VERSION ""

NS_ :

BS_:

BU_: HVESP01 HVESS

BO_ 2499741802 HVESP01_InternalResistance_6: 8 HVESP01
 SG_ HVESP01_brickResistance_01__6 m0: 8|14@1+ (0.01,0) [0|50] "mOhm"  HVESP01
 SG_ HVESP01_brickResistance_02__6 m0: 22|14@1+ (0.01,0) [0|50] "mOhm"  HVESP01
 SG_ HVESP01_brickResistance_03__6 m0: 36|14@1+ (0.01,0) [0|50] "mOhm"  HVESP01
 SG_ HVESP01_brickResistance_04__6 m0: 50|14@1+ (0.01,0) [0|50] "mOhm"  HVESP01
 SG_ HVESP01_brickResistance_05__6 m1: 8|14@1+ (0.01,0) [0|50] "mOhm"  HVESP01
 SG_ HVESP01_brickResistance_06__6 m1: 22|14@1+ (0.01,0) [0|50] "mOhm"  HVESP01
 SG_ HVESP01_brickResistance_07__6 m1: 36|14@1+ (0.01,0) [0|50] "mOhm"  HVESP01
 SG_ HVESP01_brickResistance_08__6 m1: 50|14@1+ (0.01,0) [0|50] "mOhm"  HVESP01
 SG_ HVESP01_brickResistance_09__6 m2: 8|14@1+ (0.01,0) [0|50] "mOhm"  HVESP01
 SG_ HVESP01_brickResistance_10__6 m2: 22|14@1+ (0.01,0) [0|50] "mOhm"  HVESP01
 SG_ HVESP01_brickResistance_11__6 m2: 36|14@1+ (0.01,0) [0|50] "mOhm"  HVESP01
 SG_ HVESP01_brickResistance_12__6 m2: 50|14@1+ (0.01,0) [0|50] "mOhm"  HVESP01
 SG_ HVESP01_brickResistance_13__6 m3: 8|14@1+ (0.01,0) [0|50] "mOhm"  HVESP01
 SG_ HVESP01_brickResistance_14__6 m3: 22|14@1+ (0.01,0) [0|50] "mOhm"  HVESP01
 SG_ HVESP01_brickResistance_15__6 m3: 36|14@1+ (0.01,0) [0|50] "mOhm"  HVESP01
 SG_ HVESP01_brickResistance_16__6 m3: 50|14@1+ (0.01,0) [0|50] "mOhm"  HVESP01
 SG_ HVESP01_brickResistance_17__6 m4: 8|14@1+ (0.01,0) [0|50] "mOhm"  HVESP01
 SG_ HVESP01_brickResistance_18__6 m4: 22|14@1+ (0.01,0) [0|50] "mOhm"  HVESP01
 SG_ HVESP01_brickResistance_19__6 m4: 36|14@1+ (0.01,0) [0|50] "mOhm"  HVESP01
 SG_ HVESP01_brickResistance_20__6 m4: 50|14@1+ (0.01,0) [0|50] "mOhm"  HVESP01
 SG_ HVESP01_brickResistance_21__6 m5: 8|14@1+ (0.01,0) [0|50] "mOhm"  HVESP01
 SG_ HVESP01_brickResistance_22__6 m5: 22|14@1+ (0.01,0) [0|50] "mOhm"  HVESP01
 SG_ HVESP01_brickResistance_23__6 m5: 36|14@1+ (0.01,0) [0|50] "mOhm"  HVESP01
 SG_ HVESP01_brickResistance_24__6 m5: 50|14@1+ (0.01,0) [0|50] "mOhm"  HVESP01
 SG_ HVESP01_brickResistance_25__6 m6: 8|14@1+ (0.01,0) [0|50] "mOhm"  HVESP01
 SG_ HVESP01_brickResistance_26__6 m6: 22|14@1+ (0.01,0) [0|50] "mOhm"  HVESP01
 SG_ HVESP01_brickResistance_27__6 m6: 36|14@1+ (0.01,0) [0|50] "mOhm"  HVESP01
 SG_ HVESP01_brickResistance_28__6 m6: 50|14@1+ (0.01,0) [0|50] "mOhm"  HVESP01
 SG_ HVESP01_brickResistance_29__6 m7: 8|14@1+ (0.01,0) [0|50] "mOhm"  HVESP01
 SG_ HVESP01_brickResistance_30__6 m7: 22|14@1+ (0.01,0) [0|50] "mOhm"  HVESP01
 SG_ HVESP01_brickResistance_31__6 m7: 36|14@1+ (0.01,0) [0|50] "mOhm"  HVESP01
 SG_ HVESP01_brickResistance_32__6 m7: 50|14@1+ (0.01,0) [0|50] "mOhm"  HVESP01
 SG_ HVESP01_brickResistance_33__6 m8: 8|14@1+ (0.01,0) [0|50] "mOhm"  HVESP01
 SG_ HVESP01_brickResistance_34__6 m8: 22|14@1+ (0.01,0) [0|50] "mOhm"  HVESP01
 SG_ HVESP01_brickResistance_35__6 m8: 36|14@1+ (0.01,0) [0|50] "mOhm"  HVESP01
 SG_ HVESP01_brickResistance_36__6 m8: 50|14@1+ (0.01,0) [0|50] "mOhm"  HVESP01
 SG_ HVESP01_brickResistance_37__6 m9: 8|14@1+ (0.01,0) [0|50] "mOhm"  HVESP01
 SG_ HVESP01_brickResistance_38__6 m9: 22|14@1+ (0.01,0) [0|50] "mOhm"  HVESP01
 SG_ HVESP01_brickResistance_39__6 m9: 36|14@1+ (0.01,0) [0|50] "mOhm"  HVESP01
 SG_ HVESP01_brickResistance_40__6 m9: 50|14@1+ (0.01,0) [0|50] "mOhm"  HVESP01
 SG_ HVESP01_brickResistance_41__6 m10: 8|14@1+ (0.01,0) [0|50] "mOhm"  HVESP01
 SG_ HVESP01_brickResistance_42__6 m10: 22|14@1+ (0.01,0) [0|50] "mOhm"  HVESP01
 SG_ HVESP01_brickResistance_43__6 m10: 36|14@1+ (0.01,0) [0|50] "mOhm"  HVESP01
 SG_ HVESP01_brickResistance_44__6 m10: 50|14@1+ (0.01,0) [0|50] "mOhm"  HVESP01
 SG_ HVESP01_brickResistance_45__6 m11: 8|14@1+ (0.01,0) [0|50] "mOhm"  HVESP01
 SG_ HVESP01_brickResistance_46__6 m11: 22|14@1+ (0.01,0) [0|50] "mOhm"  HVESP01
 SG_ HVESP01_brickResistance_47__6 m11: 36|14@1+ (0.01,0) [0|50] "mOhm"  HVESP01
 SG_ HVESP01_brickResistance_48__6 m11: 50|14@1+ (0.01,0) [0|50] "mOhm"  HVESP01
 SG_ HVESP01_brickResistance_49__6 m12: 8|14@1+ (0.01,0) [0|50] "mOhm"  HVESP01
 SG_ HVESP01_brickResistance_50__6 m12: 22|14@1+ (0.01,0) [0|50] "mOhm"  HVESP01
 SG_ HVESP01_brickResistance_51__6 m12: 36|14@1+ (0.01,0) [0|50] "mOhm"  HVESP01
 SG_ HVESP01_brickResistance_52__6 m12: 50|14@1+ (0.01,0) [0|50] "mOhm"  HVESP01
 SG_ HVESP01_brickResistance_53__6 m13: 8|14@1+ (0.01,0) [0|50] "mOhm"  HVESP01
 SG_ HVESP01_brickResistance_54__6 m13: 22|14@1+ (0.01,0) [0|50] "mOhm"  HVESP01
 SG_ HVESP01_brickResistance_55__6 m13: 36|14@1+ (0.01,0) [0|50] "mOhm"  HVESP01
 SG_ HVESP01_brickResistance_56__6 m13: 50|14@1+ (0.01,0) [0|50] "mOhm"  HVESP01
 SG_ HVESP01_brickResistance_57__6 m14: 8|14@1+ (0.01,0) [0|50] "mOhm"  HVESP01
 SG_ HVESP01_brickResistance_58__6 m14: 22|14@1+ (0.01,0) [0|50] "mOhm"  HVESP01
 SG_ HVESP01_brickResistance_59__6 m14: 36|14@1+ (0.01,0) [0|50] "mOhm"  HVESP01
 SG_ HVESP01_brickResistance_60__6 m14: 50|14@1+ (0.01,0) [0|50] "mOhm"  HVESP01
 SG_ HVESP01_brickResistance_61__6 m15: 8|14@1+ (0.01,0) [0|50] "mOhm"  HVESP01
 SG_ HVESP01_brickResistance_62__6 m15: 22|14@1+ (0.01,0) [0|50] "mOhm"  HVESP01
 SG_ HVESP01_brickResistance_63__6 m15: 36|14@1+ (0.01,0) [0|50] "mOhm"  HVESP01
 SG_ HVESP01_brickResistance_64__6 m15: 50|14@1+ (0.01,0) [0|50] "mOhm"  HVESP01
 SG_ HVESP01_brickResistance_65__6 m16: 8|14@1+ (0.01,0) [0|50] "mOhm"  HVESP01
 SG_ HVESP01_brickResistance_66__6 m16: 22|14@1+ (0.01,0) [0|50] "mOhm"  HVESP01
 SG_ HVESP01_brickResistance_67__6 m16: 36|14@1+ (0.01,0) [0|50] "mOhm"  HVESP01
 SG_ HVESP01_brickResistance_68__6 m16: 50|14@1+ (0.01,0) [0|50] "mOhm"  HVESP01
 SG_ HVESP01_brickResistance_69__6 m17: 8|14@1+ (0.01,0) [0|50] "mOhm"  HVESP01
 SG_ HVESP01_brickResistance_70__6 m17: 22|14@1+ (0.01,0) [0|50] "mOhm"  HVESP01
 SG_ HVESP01_brickResistance_71__6 m17: 36|14@1+ (0.01,0) [0|50] "mOhm"  HVESP01
 SG_ HVESP01_brickResistance_72__6 m17: 50|14@1+ (0.01,0) [0|50] "mOhm"  HVESP01
 SG_ HVESP01_brickResistance_73__6 m18: 8|14@1+ (0.01,0) [0|50] "mOhm"  HVESP01
 SG_ HVESP01_brickResistance_74__6 m18: 22|14@1+ (0.01,0) [0|50] "mOhm"  HVESP01
 SG_ HVESP01_brickResistance_75__6 m18: 36|14@1+ (0.01,0) [0|50] "mOhm"  HVESP01
 SG_ HVESP01_brickResistance_76__6 m18: 50|14@1+ (0.01,0) [0|50] "mOhm"  HVESP01
 SG_ HVESP01_brickResistance_77__6 m19: 8|14@1+ (0.01,0) [0|50] "mOhm"  HVESP01
 SG_ HVESP01_brickResistance_78__6 m19: 22|14@1+ (0.01,0) [0|50] "mOhm"  HVESP01
 SG_ HVESP01_brickResistance_79__6 m19: 36|14@1+ (0.01,0) [0|50] "mOhm"  HVESP01
 SG_ HVESP01_brickResistance_80__6 m19: 50|14@1+ (0.01,0) [0|50] "mOhm"  HVESP01
 SG_ HVESP01_brickResistance_81__6 m20: 8|14@1+ (0.01,0) [0|50] "mOhm"  HVESP01
 SG_ HVESP01_brickResistance_82__6 m20: 22|14@1+ (0.01,0) [0|50] "mOhm"  HVESP01
 SG_ HVESP01_brickResistance_83__6 m20: 36|14@1+ (0.01,0) [0|50] "mOhm"  HVESP01
 SG_ HVESP01_brickResistance_84__6 m20: 50|14@1+ (0.01,0) [0|50] "mOhm"  HVESP01
 SG_ HVESP01_brickResistance_85__6 m21: 8|14@1+ (0.01,0) [0|50] "mOhm"  HVESP01
 SG_ HVESP01_brickResistance_86__6 m21: 22|14@1+ (0.01,0) [0|50] "mOhm"  HVESP01
 SG_ HVESP01_brickResistance_87__6 m21: 36|14@1+ (0.01,0) [0|50] "mOhm"  HVESP01
 SG_ HVESP01_brickResistance_88__6 m21: 50|14@1+ (0.01,0) [0|50] "mOhm"  HVESP01
 SG_ HVESP01_brickResistance_89__6 m22: 8|14@1+ (0.01,0) [0|50] "mOhm"  HVESP01
 SG_ HVESP01_brickResistance_90__6 m22: 22|14@1+ (0.01,0) [0|50] "mOhm"  HVESP01
 SG_ HVESP01_brickResistance_91__6 m22: 36|14@1+ (0.01,0) [0|50] "mOhm"  HVESP01
 SG_ HVESP01_brickResistance_92__6 m22: 50|14@1+ (0.01,0) [0|50] "mOhm"  HVESP01
 SG_ HVESP01_brickResistance_93__6 m23: 8|14@1+ (0.01,0) [0|50] "mOhm"  HVESP01
 SG_ HVESP01_brickResistance_94__6 m23: 22|14@1+ (0.01,0) [0|50] "mOhm"  HVESP01
 SG_ HVESP01_brickResistance_95__6 m23: 36|14@1+ (0.01,0) [0|50] "mOhm"  HVESP01
 SG_ HVESP01_brickResistance_96__6 m23: 50|14@1+ (0.01,0) [0|50] "mOhm"  HVESP01
 SG_ HVESP01_brickResistance_97__6 m24: 8|14@1+ (0.01,0) [0|50] "mOhm"  HVESP01
 SG_ HVESP01_brickResistance_98__6 m24: 22|14@1+ (0.01,0) [0|50] "mOhm"  HVESP01
 SG_ HVESP01_brickResistance_99__6 m24: 36|14@1+ (0.01,0) [0|50] "mOhm"  HVESP01
 SG_ HVESP01_brickResistance_100_6 m24: 50|14@1+ (0.01,0) [0|50] "mOhm"  HVESP01
 SG_ HVESP01_brickResistance_101_6 m25: 8|14@1+ (0.01,0) [0|50] "mOhm"  HVESP01
 SG_ HVESP01_brickResistance_102_6 m25: 22|14@1+ (0.01,0) [0|50] "mOhm"  HVESP01
 SG_ HVESP01_brickResistance_103_6 m25: 36|14@1+ (0.01,0) [0|50] "mOhm"  HVESP01
 SG_ HVESP01_brickResistance_104_6 m25: 50|14@1+ (0.01,0) [0|50] "mOhm"  HVESP01
 SG_ HVESP01_brickResistance_105_6 m26: 8|14@1+ (0.01,0) [0|50] "mOhm"  HVESP01
 SG_ HVESP01_brickResistance_106_6 m26: 22|14@1+ (0.01,0) [0|50] "mOhm"  HVESP01
 SG_ HVESP01_brickResistance_107_6 m26: 36|14@1+ (0.01,0) [0|50] "mOhm"  HVESP01
 SG_ HVESP01_brickResistance_108_6 m26: 50|14@1+ (0.01,0) [0|50] "mOhm"  HVESP01
 SG_ HVESP01_brickResistance_109_6 m27: 8|14@1+ (0.01,0) [0|50] "mOhm"  HVESP01
 SG_ HVESP01_brickResistance_110_6 m27: 22|14@1+ (0.01,0) [0|50] "mOhm"  HVESP01
 SG_ HVESP01_brickResistance_111_6 m27: 36|14@1+ (0.01,0) [0|50] "mOhm"  HVESP01
 SG_ HVESP01_brickResistance_112_6 m27: 50|14@1+ (0.01,0) [0|50] "mOhm"  HVESP01
 SG_ HVESP01_brickResistance_113_6 m28: 8|14@1+ (0.01,0) [0|50] "mOhm"  HVESP01
 SG_ HVESP01_brickResistance_114_6 m28: 22|14@1+ (0.01,0) [0|50] "mOhm"  HVESP01
 SG_ HVESP01_brickResistance_115_6 m28: 36|14@1+ (0.01,0) [0|50] "mOhm"  HVESP01
 SG_ HVESP01_brickResistance_116_6 m28: 50|14@1+ (0.01,0) [0|50] "mOhm"  HVESP01
 SG_ HVESP01_brickResistance_117_6 m29: 8|14@1+ (0.01,0) [0|50] "mOhm"  HVESP01
 SG_ HVESP01_brickResistance_118_6 m29: 22|14@1+ (0.01,0) [0|50] "mOhm"  HVESP01
 SG_ HVESP01_brickResistance_119_6 m29: 36|14@1+ (0.01,0) [0|50] "mOhm"  HVESP01
 SG_ HVESP01_brickResistance_120_6 m29: 50|14@1+ (0.01,0) [0|50] "mOhm"  HVESP01
 SG_ HVESP01_brickResistance_121_6 m30: 8|14@1+ (0.01,0) [0|50] "mOhm"  HVESP01
 SG_ HVESP01_brickResistance_122_6 m30: 22|14@1+ (0.01,0) [0|50] "mOhm"  HVESP01
 SG_ HVESP01_brickResistance_123_6 m30: 36|14@1+ (0.01,0) [0|50] "mOhm"  HVESP01
 SG_ HVESP01_brickResistance_124_6 m30: 50|14@1+ (0.01,0) [0|50] "mOhm"  HVESP01
 SG_ HVESP01_brickResistance_125_6 m31: 8|14@1+ (0.01,0) [0|50] "mOhm"  HVESP01
 SG_ HVESP01_brickResistance_126_6 m31: 22|14@1+ (0.01,0) [0|50] "mOhm"  HVESP01
 SG_ HVESP01_brickResistance_127_6 m31: 36|14@1+ (0.01,0) [0|50] "mOhm"  HVESP01
 SG_ HVESP01_brickResistance_128_6 m31: 50|14@1+ (0.01,0) [0|50] "mOhm"  HVESP01
 SG_ HVESP01_brickResistance_129_6 m32: 8|14@1+ (0.01,0) [0|50] "mOhm"  HVESP01
 SG_ HVESP01_brickResistance_130_6 m32: 22|14@1+ (0.01,0) [0|50] "mOhm"  HVESP01
 SG_ HVESP01_brickResistance_131_6 m32: 36|14@1+ (0.01,0) [0|50] "mOhm"  HVESP01
 SG_ HVESP01_brickResistance_132_6 m32: 50|14@1+ (0.01,0) [0|50] "mOhm"  HVESP01
 SG_ HVESP01_brickResistance_133_6 m33: 8|14@1+ (0.01,0) [0|50] "mOhm"  HVESP01
 SG_ HVESP01_brickResistance_134_6 m33: 22|14@1+ (0.01,0) [0|50] "mOhm"  HVESP01
 SG_ HVESP01_brickResistance_135_6 m33: 36|14@1+ (0.01,0) [0|50] "mOhm"  HVESP01
 SG_ HVESP01_brickResistance_136_6 m33: 50|14@1+ (0.01,0) [0|50] "mOhm"  HVESP01
 SG_ HVESP01_brickResistance_137_6 m34: 8|14@1+ (0.01,0) [0|50] "mOhm"  HVESP01
 SG_ HVESP01_brickResistance_138_6 m34: 22|14@1+ (0.01,0) [0|50] "mOhm"  HVESP01
 SG_ HVESP01_brickResistance_139_6 m34: 36|14@1+ (0.01,0) [0|50] "mOhm"  HVESP01
 SG_ HVESP01_brickResistance_140_6 m34: 50|14@1+ (0.01,0) [0|50] "mOhm"  HVESP01
 SG_ HVESP01_brickResistance_141_6 m35: 8|14@1+ (0.01,0) [0|50] "mOhm"  HVESP01
 SG_ HVESP01_brickResistance_142_6 m35: 22|14@1+ (0.01,0) [0|50] "mOhm"  HVESP01
 SG_ HVESP01_brickResistance_143_6 m35: 36|14@1+ (0.01,0) [0|50] "mOhm"  HVESP01
 SG_ HVESP01_brickResistance_144_6 m35: 50|14@1+ (0.01,0) [0|50] "mOhm"  HVESP01
 SG_ HVESP01_brickResistance_145_6 m36: 8|14@1+ (0.01,0) [0|50] "mOhm"  HVESP01
 SG_ HVESP01_brickResistance_146_6 m36: 22|14@1+ (0.01,0) [0|50] "mOhm"  HVESP01
 SG_ HVESP01_brickResistance_147_6 m36: 36|14@1+ (0.01,0) [0|50] "mOhm"  HVESP01
 SG_ HVESP01_brickResistance_148_6 m36: 50|14@1+ (0.01,0) [0|50] "mOhm"  HVESP01
 SG_ HVESP01_brickResistance_149_6 m37: 8|14@1+ (0.01,0) [0|50] "mOhm"  HVESP01
 SG_ HVESP01_brickResistance_150_6 m37: 22|14@1+ (0.01,0) [0|50] "mOhm"  HVESP01
 SG_ HVESP01_brickResistance_151_6 m37: 36|14@1+ (0.01,0) [0|50] "mOhm"  HVESP01
 SG_ HVESP01_brickResistance_152_6 m37: 50|14@1+ (0.01,0) [0|50] "mOhm"  HVESP01
 SG_ HVESP01_brickResistance_153_6 m38: 8|14@1+ (0.01,0) [0|50] "mOhm"  HVESP01
 SG_ HVESP01_brickResistance_154_6 m38: 22|14@1+ (0.01,0) [0|50] "mOhm"  HVESP01
 SG_ HVESP01_brickResistance_155_6 m38: 36|14@1+ (0.01,0) [0|50] "mOhm"  HVESP01
 SG_ HVESP01_brickResistance_156_6 m38: 50|14@1+ (0.01,0) [0|50] "mOhm"  HVESP01
 SG_ HVESP01_brickResistance_157_6 m39: 8|14@1+ (0.01,0) [0|50] "mOhm"  HVESP01
 SG_ HVESP01_brickResistance_158_6 m39: 22|14@1+ (0.01,0) [0|50] "mOhm"  HVESP01
 SG_ HVESP01_brickResistance_159_6 m39: 36|14@1+ (0.01,0) [0|50] "mOhm"  HVESP01
 SG_ HVESP01_brickResistance_160_6 m39: 50|14@1+ (0.01,0) [0|50] "mOhm"  HVESP01
 SG_ HVESP01_brickResistance_161_6 m40: 8|14@1+ (0.01,0) [0|50] "mOhm"  HVESP01
 SG_ HVESP01_brickResistance_162_6 m40: 22|14@1+ (0.01,0) [0|50] "mOhm"  HVESP01
 SG_ HVESP01_brickResistance_163_6 m40: 36|14@1+ (0.01,0) [0|50] "mOhm"  HVESP01
 SG_ HVESP01_brickResistance_164_6 m40: 50|14@1+ (0.01,0) [0|50] "mOhm"  HVESP01
 SG_ HVESP01_brickResistance_165_6 m41: 8|14@1+ (0.01,0) [0|50] "mOhm"  HVESP01
 SG_ HVESP01_brickResistance_166_6 m41: 22|14@1+ (0.01,0) [0|50] "mOhm"  HVESP01
 SG_ HVESP01_brickResistance_167_6 m41: 36|14@1+ (0.01,0) [0|50] "mOhm"  HVESP01
 SG_ HVESP01_brickResistance_168_6 m41: 50|14@1+ (0.01,0) [0|50] "mOhm"  HVESP01
 SG_ HVESP01_brickResistance_169_6 m42: 8|14@1+ (0.01,0) [0|50] "mOhm"  HVESP01
 SG_ HVESP01_brickResistance_170_6 m42: 22|14@1+ (0.01,0) [0|50] "mOhm"  HVESP01
 SG_ HVESP01_brickResistance_171_6 m42: 36|14@1+ (0.01,0) [0|50] "mOhm"  HVESP01
 SG_ HVESP01_brickResistance_172_6 m42: 50|14@1+ (0.01,0) [0|50] "mOhm"  HVESP01
 SG_ HVESP01_brickResistance_173_6 m43: 8|14@1+ (0.01,0) [0|50] "mOhm"  HVESP01
 SG_ HVESP01_brickResistance_174_6 m43: 22|14@1+ (0.01,0) [0|50] "mOhm"  HVESP01
 SG_ HVESP01_brickResistance_175_6 m43: 36|14@1+ (0.01,0) [0|50] "mOhm"  HVESP01
 SG_ HVESP01_brickResistance_176_6 m43: 50|14@1+ (0.01,0) [0|50] "mOhm"  HVESP01
 SG_ HVESP01_brickResistance_177_6 m44: 8|14@1+ (0.01,0) [0|50] "mOhm"  HVESP01
 SG_ HVESP01_brickResistance_178_6 m44: 22|14@1+ (0.01,0) [0|50] "mOhm"  HVESP01
 SG_ HVESP01_brickResistance_179_6 m44: 36|14@1+ (0.01,0) [0|50] "mOhm"  HVESP01
 SG_ HVESP01_brickResistance_180_6 m44: 50|14@1+ (0.01,0) [0|50] "mOhm"  HVESP01
 SG_ HVESP01_brickResistance_181_6 m45: 8|14@1+ (0.01,0) [0|50] "mOhm"  HVESP01
 SG_ HVESP01_brickResistance_182_6 m45: 22|14@1+ (0.01,0) [0|50] "mOhm"  HVESP01
 SG_ HVESP01_brickResistance_183_6 m45: 36|14@1+ (0.01,0) [0|50] "mOhm"  HVESP01
 SG_ HVESP01_brickResistance_184_6 m45: 50|14@1+ (0.01,0) [0|50] "mOhm"  HVESP01
 SG_ HVESP01_brickResistance_185_6 m46: 8|14@1+ (0.01,0) [0|50] "mOhm"  HVESP01
 SG_ HVESP01_brickResistance_186_6 m46: 22|14@1+ (0.01,0) [0|50] "mOhm"  HVESP01
 SG_ HVESP01_brickResistance_187_6 m46: 36|14@1+ (0.01,0) [0|50] "mOhm"  HVESP01
 SG_ HVESP01_brickResistance_188_6 m46: 50|14@1+ (0.01,0) [0|50] "mOhm"  HVESP01
 SG_ HVESP01_brickResistance_189_6 m47: 8|14@1+ (0.01,0) [0|50] "mOhm"  HVESP01
 SG_ HVESP01_brickResistance_190_6 m47: 22|14@1+ (0.01,0) [0|50] "mOhm"  HVESP01
 SG_ HVESP01_brickResistance_191_6 m47: 36|14@1+ (0.01,0) [0|50] "mOhm"  HVESP01
 SG_ HVESP01_brickResistance_192_6 m47: 50|14@1+ (0.01,0) [0|50] "mOhm"  HVESP01
 SG_ multiplexorbr_6 M: 0|8@1+ (1,0) [0|255] ""  HVESP01

BO_ 2499741803 HVESP01_InternalResistance_7: 8 HVESP01
 SG_ HVESP01_brickResistance_01__7 m0: 8|14@1+ (0.01,0) [0|50] "mOhm"  HVESP01
 SG_ HVESP01_brickResistance_02__7 m0: 22|14@1+ (0.01,0) [0|50] "mOhm"  HVESP01
 SG_ HVESP01_brickResistance_03__7 m0: 36|14@1+ (0.01,0) [0|50] "mOhm"  HVESP01
 SG_ HVESP01_brickResistance_04__7 m0: 50|14@1+ (0.01,0) [0|50] "mOhm"  HVESP01
 SG_ HVESP01_brickResistance_05__7 m1: 8|14@1+ (0.01,0) [0|50] "mOhm"  HVESP01
 SG_ HVESP01_brickResistance_06__7 m1: 22|14@1+ (0.01,0) [0|50] "mOhm"  HVESP01
 SG_ HVESP01_brickResistance_07__7 m1: 36|14@1+ (0.01,0) [0|50] "mOhm"  HVESP01
 SG_ HVESP01_brickResistance_08__7 m1: 50|14@1+ (0.01,0) [0|50] "mOhm"  HVESP01
 SG_ HVESP01_brickResistance_09__7 m2: 8|14@1+ (0.01,0) [0|50] "mOhm"  HVESP01
 SG_ HVESP01_brickResistance_10__7 m2: 22|14@1+ (0.01,0) [0|50] "mOhm"  HVESP01
 SG_ HVESP01_brickResistance_11__7 m2: 36|14@1+ (0.01,0) [0|50] "mOhm"  HVESP01
 SG_ HVESP01_brickResistance_12__7 m2: 50|14@1+ (0.01,0) [0|50] "mOhm"  HVESP01
 SG_ HVESP01_brickResistance_13__7 m3: 8|14@1+ (0.01,0) [0|50] "mOhm"  HVESP01
 SG_ HVESP01_brickResistance_14__7 m3: 22|14@1+ (0.01,0) [0|50] "mOhm"  HVESP01
 SG_ HVESP01_brickResistance_15__7 m3: 36|14@1+ (0.01,0) [0|50] "mOhm"  HVESP01
 SG_ HVESP01_brickResistance_16__7 m3: 50|14@1+ (0.01,0) [0|50] "mOhm"  HVESP01
 SG_ HVESP01_brickResistance_17__7 m4: 8|14@1+ (0.01,0) [0|50] "mOhm"  HVESP01
 SG_ HVESP01_brickResistance_18__7 m4: 22|14@1+ (0.01,0) [0|50] "mOhm"  HVESP01
 SG_ HVESP01_brickResistance_19__7 m4: 36|14@1+ (0.01,0) [0|50] "mOhm"  HVESP01
 SG_ HVESP01_brickResistance_20__7 m4: 50|14@1+ (0.01,0) [0|50] "mOhm"  HVESP01
 SG_ HVESP01_brickResistance_21__7 m5: 8|14@1+ (0.01,0) [0|50] "mOhm"  HVESP01
 SG_ HVESP01_brickResistance_22__7 m5: 22|14@1+ (0.01,0) [0|50] "mOhm"  HVESP01
 SG_ HVESP01_brickResistance_23__7 m5: 36|14@1+ (0.01,0) [0|50] "mOhm"  HVESP01
 SG_ HVESP01_brickResistance_24__7 m5: 50|14@1+ (0.01,0) [0|50] "mOhm"  HVESP01
 SG_ HVESP01_brickResistance_25__7 m6: 8|14@1+ (0.01,0) [0|50] "mOhm"  HVESP01
 SG_ HVESP01_brickResistance_26__7 m6: 22|14@1+ (0.01,0) [0|50] "mOhm"  HVESP01
 SG_ HVESP01_brickResistance_27__7 m6: 36|14@1+ (0.01,0) [0|50] "mOhm"  HVESP01
 SG_ HVESP01_brickResistance_28__7 m6: 50|14@1+ (0.01,0) [0|50] "mOhm"  HVESP01
 SG_ HVESP01_brickResistance_29__7 m7: 8|14@1+ (0.01,0) [0|50] "mOhm"  HVESP01
 SG_ HVESP01_brickResistance_30__7 m7: 22|14@1+ (0.01,0) [0|50] "mOhm"  HVESP01
 SG_ HVESP01_brickResistance_31__7 m7: 36|14@1+ (0.01,0) [0|50] "mOhm"  HVESP01
 SG_ HVESP01_brickResistance_32__7 m7: 50|14@1+ (0.01,0) [0|50] "mOhm"  HVESP01
 SG_ HVESP01_brickResistance_33__7 m8: 8|14@1+ (0.01,0) [0|50] "mOhm"  HVESP01
 SG_ HVESP01_brickResistance_34__7 m8: 22|14@1+ (0.01,0) [0|50] "mOhm"  HVESP01
 SG_ HVESP01_brickResistance_35__7 m8: 36|14@1+ (0.01,0) [0|50] "mOhm"  HVESP01
 SG_ HVESP01_brickResistance_36__7 m8: 50|14@1+ (0.01,0) [0|50] "mOhm"  HVESP01
 SG_ HVESP01_brickResistance_37__7 m9: 8|14@1+ (0.01,0) [0|50] "mOhm"  HVESP01
 SG_ HVESP01_brickResistance_38__7 m9: 22|14@1+ (0.01,0) [0|50] "mOhm"  HVESP01
 SG_ HVESP01_brickResistance_39__7 m9: 36|14@1+ (0.01,0) [0|50] "mOhm"  HVESP01
 SG_ HVESP01_brickResistance_40__7 m9: 50|14@1+ (0.01,0) [0|50] "mOhm"  HVESP01
 SG_ HVESP01_brickResistance_41__7 m10: 8|14@1+ (0.01,0) [0|50] "mOhm"  HVESP01
 SG_ HVESP01_brickResistance_42__7 m10: 22|14@1+ (0.01,0) [0|50] "mOhm"  HVESP01
 SG_ HVESP01_brickResistance_43__7 m10: 36|14@1+ (0.01,0) [0|50] "mOhm"  HVESP01
 SG_ HVESP01_brickResistance_44__7 m10: 50|14@1+ (0.01,0) [0|50] "mOhm"  HVESP01
 SG_ HVESP01_brickResistance_45__7 m11: 8|14@1+ (0.01,0) [0|50] "mOhm"  HVESP01
 SG_ HVESP01_brickResistance_46__7 m11: 22|14@1+ (0.01,0) [0|50] "mOhm"  HVESP01
 SG_ HVESP01_brickResistance_47__7 m11: 36|14@1+ (0.01,0) [0|50] "mOhm"  HVESP01
 SG_ HVESP01_brickResistance_48__7 m11: 50|14@1+ (0.01,0) [0|50] "mOhm"  HVESP01
 SG_ HVESP01_brickResistance_49__7 m12: 8|14@1+ (0.01,0) [0|50] "mOhm"  HVESP01
 SG_ HVESP01_brickResistance_50__7 m12: 22|14@1+ (0.01,0) [0|50] "mOhm"  HVESP01
 SG_ HVESP01_brickResistance_51__7 m12: 36|14@1+ (0.01,0) [0|50] "mOhm"  HVESP01
 SG_ HVESP01_brickResistance_52__7 m12: 50|14@1+ (0.01,0) [0|50] "mOhm"  HVESP01
 SG_ HVESP01_brickResistance_53__7 m13: 8|14@1+ (0.01,0) [0|50] "mOhm"  HVESP01
 SG_ HVESP01_brickResistance_54__7 m13: 22|14@1+ (0.01,0) [0|50] "mOhm"  HVESP01
 SG_ HVESP01_brickResistance_55__7 m13: 36|14@1+ (0.01,0) [0|50] "mOhm"  HVESP01
 SG_ HVESP01_brickResistance_56__7 m13: 50|14@1+ (0.01,0) [0|50] "mOhm"  HVESP01
 SG_ HVESP01_brickResistance_57__7 m14: 8|14@1+ (0.01,0) [0|50] "mOhm"  HVESP01
 SG_ HVESP01_brickResistance_58__7 m14: 22|14@1+ (0.01,0) [0|50] "mOhm"  HVESP01
 SG_ HVESP01_brickResistance_59__7 m14: 36|14@1+ (0.01,0) [0|50] "mOhm"  HVESP01
 SG_ HVESP01_brickResistance_60__7 m14: 50|14@1+ (0.01,0) [0|50] "mOhm"  HVESP01
 SG_ HVESP01_brickResistance_61__7 m15: 8|14@1+ (0.01,0) [0|50] "mOhm"  HVESP01
 SG_ HVESP01_brickResistance_62__7 m15: 22|14@1+ (0.01,0) [0|50] "mOhm"  HVESP01
 SG_ HVESP01_brickResistance_63__7 m15: 36|14@1+ (0.01,0) [0|50] "mOhm"  HVESP01
 SG_ HVESP01_brickResistance_64__7 m15: 50|14@1+ (0.01,0) [0|50] "mOhm"  HVESP01
 SG_ HVESP01_brickResistance_65__7 m16: 8|14@1+ (0.01,0) [0|50] "mOhm"  HVESP01
 SG_ HVESP01_brickResistance_66__7 m16: 22|14@1+ (0.01,0) [0|50] "mOhm"  HVESP01
 SG_ HVESP01_brickResistance_67__7 m16: 36|14@1+ (0.01,0) [0|50] "mOhm"  HVESP01
 SG_ HVESP01_brickResistance_68__7 m16: 50|14@1+ (0.01,0) [0|50] "mOhm"  HVESP01
 SG_ HVESP01_brickResistance_69__7 m17: 8|14@1+ (0.01,0) [0|50] "mOhm"  HVESP01
 SG_ HVESP01_brickResistance_70__7 m17: 22|14@1+ (0.01,0) [0|50] "mOhm"  HVESP01
 SG_ HVESP01_brickResistance_71__7 m17: 36|14@1+ (0.01,0) [0|50] "mOhm"  HVESP01
 SG_ HVESP01_brickResistance_72__7 m17: 50|14@1+ (0.01,0) [0|50] "mOhm"  HVESP01
 SG_ HVESP01_brickResistance_73__7 m18: 8|14@1+ (0.01,0) [0|50] "mOhm"  HVESP01
 SG_ HVESP01_brickResistance_74__7 m18: 22|14@1+ (0.01,0) [0|50] "mOhm"  HVESP01
 SG_ HVESP01_brickResistance_75__7 m18: 36|14@1+ (0.01,0) [0|50] "mOhm"  HVESP01
 SG_ HVESP01_brickResistance_76__7 m18: 50|14@1+ (0.01,0) [0|50] "mOhm"  HVESP01
 SG_ HVESP01_brickResistance_77__7 m19: 8|14@1+ (0.01,0) [0|50] "mOhm"  HVESP01
 SG_ HVESP01_brickResistance_78__7 m19: 22|14@1+ (0.01,0) [0|50] "mOhm"  HVESP01
 SG_ HVESP01_brickResistance_79__7 m19: 36|14@1+ (0.01,0) [0|50] "mOhm"  HVESP01
 SG_ HVESP01_brickResistance_80__7 m19: 50|14@1+ (0.01,0) [0|50] "mOhm"  HVESP01
 SG_ HVESP01_brickResistance_81__7 m20: 8|14@1+ (0.01,0) [0|50] "mOhm"  HVESP01
 SG_ HVESP01_brickResistance_82__7 m20: 22|14@1+ (0.01,0) [0|50] "mOhm"  HVESP01
 SG_ HVESP01_brickResistance_83__7 m20: 36|14@1+ (0.01,0) [0|50] "mOhm"  HVESP01
 SG_ HVESP01_brickResistance_84__7 m20: 50|14@1+ (0.01,0) [0|50] "mOhm"  HVESP01
 SG_ HVESP01_brickResistance_85__7 m21: 8|14@1+ (0.01,0) [0|50] "mOhm"  HVESP01
 SG_ HVESP01_brickResistance_86__7 m21: 22|14@1+ (0.01,0) [0|50] "mOhm"  HVESP01
 SG_ HVESP01_brickResistance_87__7 m21: 36|14@1+ (0.01,0) [0|50] "mOhm"  HVESP01
 SG_ HVESP01_brickResistance_88__7 m21: 50|14@1+ (0.01,0) [0|50] "mOhm"  HVESP01
 SG_ HVESP01_brickResistance_89__7 m22: 8|14@1+ (0.01,0) [0|50] "mOhm"  HVESP01
 SG_ HVESP01_brickResistance_90__7 m22: 22|14@1+ (0.01,0) [0|50] "mOhm"  HVESP01
 SG_ HVESP01_brickResistance_91__7 m22: 36|14@1+ (0.01,0) [0|50] "mOhm"  HVESP01
 SG_ HVESP01_brickResistance_92__7 m22: 50|14@1+ (0.01,0) [0|50] "mOhm"  HVESP01
 SG_ HVESP01_brickResistance_93__7 m23: 8|14@1+ (0.01,0) [0|50] "mOhm"  HVESP01
 SG_ HVESP01_brickResistance_94__7 m23: 22|14@1+ (0.01,0) [0|50] "mOhm"  HVESP01
 SG_ HVESP01_brickResistance_95__7 m23: 36|14@1+ (0.01,0) [0|50] "mOhm"  HVESP01
 SG_ HVESP01_brickResistance_96__7 m23: 50|14@1+ (0.01,0) [0|50] "mOhm"  HVESP01
 SG_ HVESP01_brickResistance_97__7 m24: 8|14@1+ (0.01,0) [0|50] "mOhm"  HVESP01
 SG_ HVESP01_brickResistance_98__7 m24: 22|14@1+ (0.01,0) [0|50] "mOhm"  HVESP01
 SG_ HVESP01_brickResistance_99__7 m24: 36|14@1+ (0.01,0) [0|50] "mOhm"  HVESP01
 SG_ HVESP01_brickResistance_100_7 m24: 50|14@1+ (0.01,0) [0|50] "mOhm"  HVESP01
 SG_ HVESP01_brickResistance_101_7 m25: 8|14@1+ (0.01,0) [0|50] "mOhm"  HVESP01
 SG_ HVESP01_brickResistance_102_7 m25: 22|14@1+ (0.01,0) [0|50] "mOhm"  HVESP01
 SG_ HVESP01_brickResistance_103_7 m25: 36|14@1+ (0.01,0) [0|50] "mOhm"  HVESP01
 SG_ HVESP01_brickResistance_104_7 m25: 50|14@1+ (0.01,0) [0|50] "mOhm"  HVESP01
 SG_ HVESP01_brickResistance_105_7 m26: 8|14@1+ (0.01,0) [0|50] "mOhm"  HVESP01
 SG_ HVESP01_brickResistance_106_7 m26: 22|14@1+ (0.01,0) [0|50] "mOhm"  HVESP01
 SG_ HVESP01_brickResistance_107_7 m26: 36|14@1+ (0.01,0) [0|50] "mOhm"  HVESP01
 SG_ HVESP01_brickResistance_108_7 m26: 50|14@1+ (0.01,0) [0|50] "mOhm"  HVESP01
 SG_ HVESP01_brickResistance_109_7 m27: 8|14@1+ (0.01,0) [0|50] "mOhm"  HVESP01
 SG_ HVESP01_brickResistance_110_7 m27: 22|14@1+ (0.01,0) [0|50] "mOhm"  HVESP01
 SG_ HVESP01_brickResistance_111_7 m27: 36|14@1+ (0.01,0) [0|50] "mOhm"  HVESP01
 SG_ HVESP01_brickResistance_112_7 m27: 50|14@1+ (0.01,0) [0|50] "mOhm"  HVESP01
 SG_ HVESP01_brickResistance_113_7 m28: 8|14@1+ (0.01,0) [0|50] "mOhm"  HVESP01
 SG_ HVESP01_brickResistance_114_7 m28: 22|14@1+ (0.01,0) [0|50] "mOhm"  HVESP01
 SG_ HVESP01_brickResistance_115_7 m28: 36|14@1+ (0.01,0) [0|50] "mOhm"  HVESP01
 SG_ HVESP01_brickResistance_116_7 m28: 50|14@1+ (0.01,0) [0|50] "mOhm"  HVESP01
 SG_ HVESP01_brickResistance_117_7 m29: 8|14@1+ (0.01,0) [0|50] "mOhm"  HVESP01
 SG_ HVESP01_brickResistance_118_7 m29: 22|14@1+ (0.01,0) [0|50] "mOhm"  HVESP01
 SG_ HVESP01_brickResistance_119_7 m29: 36|14@1+ (0.01,0) [0|50] "mOhm"  HVESP01
 SG_ HVESP01_brickResistance_120_7 m29: 50|14@1+ (0.01,0) [0|50] "mOhm"  HVESP01
 SG_ HVESP01_brickResistance_121_7 m30: 8|14@1+ (0.01,0) [0|50] "mOhm"  HVESP01
 SG_ HVESP01_brickResistance_122_7 m30: 22|14@1+ (0.01,0) [0|50] "mOhm"  HVESP01
 SG_ HVESP01_brickResistance_123_7 m30: 36|14@1+ (0.01,0) [0|50] "mOhm"  HVESP01
 SG_ HVESP01_brickResistance_124_7 m30: 50|14@1+ (0.01,0) [0|50] "mOhm"  HVESP01
 SG_ HVESP01_brickResistance_125_7 m31: 8|14@1+ (0.01,0) [0|50] "mOhm"  HVESP01
 SG_ HVESP01_brickResistance_126_7 m31: 22|14@1+ (0.01,0) [0|50] "mOhm"  HVESP01
 SG_ HVESP01_brickResistance_127_7 m31: 36|14@1+ (0.01,0) [0|50] "mOhm"  HVESP01
 SG_ HVESP01_brickResistance_128_7 m31: 50|14@1+ (0.01,0) [0|50] "mOhm"  HVESP01
 SG_ HVESP01_brickResistance_129_7 m32: 8|14@1+ (0.01,0) [0|50] "mOhm"  HVESP01
 SG_ HVESP01_brickResistance_130_7 m32: 22|14@1+ (0.01,0) [0|50] "mOhm"  HVESP01
 SG_ HVESP01_brickResistance_131_7 m32: 36|14@1+ (0.01,0) [0|50] "mOhm"  HVESP01
 SG_ HVESP01_brickResistance_132_7 m32: 50|14@1+ (0.01,0) [0|50] "mOhm"  HVESP01
 SG_ HVESP01_brickResistance_133_7 m33: 8|14@1+ (0.01,0) [0|50] "mOhm"  HVESP01
 SG_ HVESP01_brickResistance_134_7 m33: 22|14@1+ (0.01,0) [0|50] "mOhm"  HVESP01
 SG_ HVESP01_brickResistance_135_7 m33: 36|14@1+ (0.01,0) [0|50] "mOhm"  HVESP01
 SG_ HVESP01_brickResistance_136_7 m33: 50|14@1+ (0.01,0) [0|50] "mOhm"  HVESP01
 SG_ HVESP01_brickResistance_137_7 m34: 8|14@1+ (0.01,0) [0|50] "mOhm"  HVESP01
 SG_ HVESP01_brickResistance_138_7 m34: 22|14@1+ (0.01,0) [0|50] "mOhm"  HVESP01
 SG_ HVESP01_brickResistance_139_7 m34: 36|14@1+ (0.01,0) [0|50] "mOhm"  HVESP01
 SG_ HVESP01_brickResistance_140_7 m34: 50|14@1+ (0.01,0) [0|50] "mOhm"  HVESP01
 SG_ HVESP01_brickResistance_141_7 m35: 8|14@1+ (0.01,0) [0|50] "mOhm"  HVESP01
 SG_ HVESP01_brickResistance_142_7 m35: 22|14@1+ (0.01,0) [0|50] "mOhm"  HVESP01
 SG_ HVESP01_brickResistance_143_7 m35: 36|14@1+ (0.01,0) [0|50] "mOhm"  HVESP01
 SG_ HVESP01_brickResistance_144_7 m35: 50|14@1+ (0.01,0) [0|50] "mOhm"  HVESP01
 SG_ HVESP01_brickResistance_145_7 m36: 8|14@1+ (0.01,0) [0|50] "mOhm"  HVESP01
 SG_ HVESP01_brickResistance_146_7 m36: 22|14@1+ (0.01,0) [0|50] "mOhm"  HVESP01
 SG_ HVESP01_brickResistance_147_7 m36: 36|14@1+ (0.01,0) [0|50] "mOhm"  HVESP01
 SG_ HVESP01_brickResistance_148_7 m36: 50|14@1+ (0.01,0) [0|50] "mOhm"  HVESP01
 SG_ HVESP01_brickResistance_149_7 m37: 8|14@1+ (0.01,0) [0|50] "mOhm"  HVESP01
 SG_ HVESP01_brickResistance_150_7 m37: 22|14@1+ (0.01,0) [0|50] "mOhm"  HVESP01
 SG_ HVESP01_brickResistance_151_7 m37: 36|14@1+ (0.01,0) [0|50] "mOhm"  HVESP01
 SG_ HVESP01_brickResistance_152_7 m37: 50|14@1+ (0.01,0) [0|50] "mOhm"  HVESP01
 SG_ HVESP01_brickResistance_153_7 m38: 8|14@1+ (0.01,0) [0|50] "mOhm"  HVESP01
 SG_ HVESP01_brickResistance_154_7 m38: 22|14@1+ (0.01,0) [0|50] "mOhm"  HVESP01
 SG_ HVESP01_brickResistance_155_7 m38: 36|14@1+ (0.01,0) [0|50] "mOhm"  HVESP01
 SG_ HVESP01_brickResistance_156_7 m38: 50|14@1+ (0.01,0) [0|50] "mOhm"  HVESP01
 SG_ HVESP01_brickResistance_157_7 m39: 8|14@1+ (0.01,0) [0|50] "mOhm"  HVESP01
 SG_ HVESP01_brickResistance_158_7 m39: 22|14@1+ (0.01,0) [0|50] "mOhm"  HVESP01
 SG_ HVESP01_brickResistance_159_7 m39: 36|14@1+ (0.01,0) [0|50] "mOhm"  HVESP01
 SG_ HVESP01_brickResistance_160_7 m39: 50|14@1+ (0.01,0) [0|50] "mOhm"  HVESP01
 SG_ HVESP01_brickResistance_161_7 m40: 8|14@1+ (0.01,0) [0|50] "mOhm"  HVESP01
 SG_ HVESP01_brickResistance_162_7 m40: 22|14@1+ (0.01,0) [0|50] "mOhm"  HVESP01
 SG_ HVESP01_brickResistance_163_7 m40: 36|14@1+ (0.01,0) [0|50] "mOhm"  HVESP01
 SG_ HVESP01_brickResistance_164_7 m40: 50|14@1+ (0.01,0) [0|50] "mOhm"  HVESP01
 SG_ HVESP01_brickResistance_165_7 m41: 8|14@1+ (0.01,0) [0|50] "mOhm"  HVESP01
 SG_ HVESP01_brickResistance_166_7 m41: 22|14@1+ (0.01,0) [0|50] "mOhm"  HVESP01
 SG_ HVESP01_brickResistance_167_7 m41: 36|14@1+ (0.01,0) [0|50] "mOhm"  HVESP01
 SG_ HVESP01_brickResistance_168_7 m41: 50|14@1+ (0.01,0) [0|50] "mOhm"  HVESP01
 SG_ HVESP01_brickResistance_169_7 m42: 8|14@1+ (0.01,0) [0|50] "mOhm"  HVESP01
 SG_ HVESP01_brickResistance_170_7 m42: 22|14@1+ (0.01,0) [0|50] "mOhm"  HVESP01
 SG_ HVESP01_brickResistance_171_7 m42: 36|14@1+ (0.01,0) [0|50] "mOhm"  HVESP01
 SG_ HVESP01_brickResistance_172_7 m42: 50|14@1+ (0.01,0) [0|50] "mOhm"  HVESP01
 SG_ HVESP01_brickResistance_173_7 m43: 8|14@1+ (0.01,0) [0|50] "mOhm"  HVESP01
 SG_ HVESP01_brickResistance_174_7 m43: 22|14@1+ (0.01,0) [0|50] "mOhm"  HVESP01
 SG_ HVESP01_brickResistance_175_7 m43: 36|14@1+ (0.01,0) [0|50] "mOhm"  HVESP01
 SG_ HVESP01_brickResistance_176_7 m43: 50|14@1+ (0.01,0) [0|50] "mOhm"  HVESP01
 SG_ HVESP01_brickResistance_177_7 m44: 8|14@1+ (0.01,0) [0|50] "mOhm"  HVESP01
 SG_ HVESP01_brickResistance_178_7 m44: 22|14@1+ (0.01,0) [0|50] "mOhm"  HVESP01
 SG_ HVESP01_brickResistance_179_7 m44: 36|14@1+ (0.01,0) [0|50] "mOhm"  HVESP01
 SG_ HVESP01_brickResistance_180_7 m44: 50|14@1+ (0.01,0) [0|50] "mOhm"  HVESP01
 SG_ HVESP01_brickResistance_181_7 m45: 8|14@1+ (0.01,0) [0|50] "mOhm"  HVESP01
 SG_ HVESP01_brickResistance_182_7 m45: 22|14@1+ (0.01,0) [0|50] "mOhm"  HVESP01
 SG_ HVESP01_brickResistance_183_7 m45: 36|14@1+ (0.01,0) [0|50] "mOhm"  HVESP01
 SG_ HVESP01_brickResistance_184_7 m45: 50|14@1+ (0.01,0) [0|50] "mOhm"  HVESP01
 SG_ HVESP01_brickResistance_185_7 m46: 8|14@1+ (0.01,0) [0|50] "mOhm"  HVESP01
 SG_ HVESP01_brickResistance_186_7 m46: 22|14@1+ (0.01,0) [0|50] "mOhm"  HVESP01
 SG_ HVESP01_brickResistance_187_7 m46: 36|14@1+ (0.01,0) [0|50] "mOhm"  HVESP01
 SG_ HVESP01_brickResistance_188_7 m46: 50|14@1+ (0.01,0) [0|50] "mOhm"  HVESP01
 SG_ HVESP01_brickResistance_189_7 m47: 8|14@1+ (0.01,0) [0|50] "mOhm"  HVESP01
 SG_ HVESP01_brickResistance_190_7 m47: 22|14@1+ (0.01,0) [0|50] "mOhm"  HVESP01
 SG_ HVESP01_brickResistance_191_7 m47: 36|14@1+ (0.01,0) [0|50] "mOhm"  HVESP01
 SG_ HVESP01_brickResistance_192_7 m47: 50|14@1+ (0.01,0) [0|50] "mOhm"  HVESP01
 SG_ multiplexorbr_7 M: 0|8@1+ (1,0) [0|255] ""  HVESP01

BO_ 2499741804 HVESP01_InternalResistance_8: 8 HVESP01
 SG_ HVESP01_brickResistance_01__8 m0: 8|14@1+ (0.01,0) [0|50] "mOhm"  HVESP01
 SG_ HVESP01_brickResistance_02__8 m0: 22|14@1+ (0.01,0) [0|50] "mOhm"  HVESP01
 SG_ HVESP01_brickResistance_03__8 m0: 36|14@1+ (0.01,0) [0|50] "mOhm"  HVESP01
 SG_ HVESP01_brickResistance_04__8 m0: 50|14@1+ (0.01,0) [0|50] "mOhm"  HVESP01
 SG_ HVESP01_brickResistance_05__8 m1: 8|14@1+ (0.01,0) [0|50] "mOhm"  HVESP01
 SG_ HVESP01_brickResistance_06__8 m1: 22|14@1+ (0.01,0) [0|50] "mOhm"  HVESP01
 SG_ HVESP01_brickResistance_07__8 m1: 36|14@1+ (0.01,0) [0|50] "mOhm"  HVESP01
 SG_ HVESP01_brickResistance_08__8 m1: 50|14@1+ (0.01,0) [0|50] "mOhm"  HVESP01
 SG_ HVESP01_brickResistance_09__8 m2: 8|14@1+ (0.01,0) [0|50] "mOhm"  HVESP01
 SG_ HVESP01_brickResistance_10__8 m2: 22|14@1+ (0.01,0) [0|50] "mOhm"  HVESP01
 SG_ HVESP01_brickResistance_11__8 m2: 36|14@1+ (0.01,0) [0|50] "mOhm"  HVESP01
 SG_ HVESP01_brickResistance_12__8 m2: 50|14@1+ (0.01,0) [0|50] "mOhm"  HVESP01
 SG_ HVESP01_brickResistance_13__8 m3: 8|14@1+ (0.01,0) [0|50] "mOhm"  HVESP01
 SG_ HVESP01_brickResistance_14__8 m3: 22|14@1+ (0.01,0) [0|50] "mOhm"  HVESP01
 SG_ HVESP01_brickResistance_15__8 m3: 36|14@1+ (0.01,0) [0|50] "mOhm"  HVESP01
 SG_ HVESP01_brickResistance_16__8 m3: 50|14@1+ (0.01,0) [0|50] "mOhm"  HVESP01
 SG_ HVESP01_brickResistance_17__8 m4: 8|14@1+ (0.01,0) [0|50] "mOhm"  HVESP01
 SG_ HVESP01_brickResistance_18__8 m4: 22|14@1+ (0.01,0) [0|50] "mOhm"  HVESP01
 SG_ HVESP01_brickResistance_19__8 m4: 36|14@1+ (0.01,0) [0|50] "mOhm"  HVESP01
 SG_ HVESP01_brickResistance_20__8 m4: 50|14@1+ (0.01,0) [0|50] "mOhm"  HVESP01
 SG_ HVESP01_brickResistance_21__8 m5: 8|14@1+ (0.01,0) [0|50] "mOhm"  HVESP01
 SG_ HVESP01_brickResistance_22__8 m5: 22|14@1+ (0.01,0) [0|50] "mOhm"  HVESP01
 SG_ HVESP01_brickResistance_23__8 m5: 36|14@1+ (0.01,0) [0|50] "mOhm"  HVESP01
 SG_ HVESP01_brickResistance_24__8 m5: 50|14@1+ (0.01,0) [0|50] "mOhm"  HVESP01
 SG_ HVESP01_brickResistance_25__8 m6: 8|14@1+ (0.01,0) [0|50] "mOhm"  HVESP01
 SG_ HVESP01_brickResistance_26__8 m6: 22|14@1+ (0.01,0) [0|50] "mOhm"  HVESP01
 SG_ HVESP01_brickResistance_27__8 m6: 36|14@1+ (0.01,0) [0|50] "mOhm"  HVESP01
 SG_ HVESP01_brickResistance_28__8 m6: 50|14@1+ (0.01,0) [0|50] "mOhm"  HVESP01
 SG_ HVESP01_brickResistance_29__8 m7: 8|14@1+ (0.01,0) [0|50] "mOhm"  HVESP01
 SG_ HVESP01_brickResistance_30__8 m7: 22|14@1+ (0.01,0) [0|50] "mOhm"  HVESP01
 SG_ HVESP01_brickResistance_31__8 m7: 36|14@1+ (0.01,0) [0|50] "mOhm"  HVESP01
 SG_ HVESP01_brickResistance_32__8 m7: 50|14@1+ (0.01,0) [0|50] "mOhm"  HVESP01
 SG_ HVESP01_brickResistance_33__8 m8: 8|14@1+ (0.01,0) [0|50] "mOhm"  HVESP01
 SG_ HVESP01_brickResistance_34__8 m8: 22|14@1+ (0.01,0) [0|50] "mOhm"  HVESP01
 SG_ HVESP01_brickResistance_35__8 m8: 36|14@1+ (0.01,0) [0|50] "mOhm"  HVESP01
 SG_ HVESP01_brickResistance_36__8 m8: 50|14@1+ (0.01,0) [0|50] "mOhm"  HVESP01
 SG_ HVESP01_brickResistance_37__8 m9: 8|14@1+ (0.01,0) [0|50] "mOhm"  HVESP01
 SG_ HVESP01_brickResistance_38__8 m9: 22|14@1+ (0.01,0) [0|50] "mOhm"  HVESP01
 SG_ HVESP01_brickResistance_39__8 m9: 36|14@1+ (0.01,0) [0|50] "mOhm"  HVESP01
 SG_ HVESP01_brickResistance_40__8 m9: 50|14@1+ (0.01,0) [0|50] "mOhm"  HVESP01
 SG_ HVESP01_brickResistance_41__8 m10: 8|14@1+ (0.01,0) [0|50] "mOhm"  HVESP01
 SG_ HVESP01_brickResistance_42__8 m10: 22|14@1+ (0.01,0) [0|50] "mOhm"  HVESP01
 SG_ HVESP01_brickResistance_43__8 m10: 36|14@1+ (0.01,0) [0|50] "mOhm"  HVESP01
 SG_ HVESP01_brickResistance_44__8 m10: 50|14@1+ (0.01,0) [0|50] "mOhm"  HVESP01
 SG_ HVESP01_brickResistance_45__8 m11: 8|14@1+ (0.01,0) [0|50] "mOhm"  HVESP01
 SG_ HVESP01_brickResistance_46__8 m11: 22|14@1+ (0.01,0) [0|50] "mOhm"  HVESP01
 SG_ HVESP01_brickResistance_47__8 m11: 36|14@1+ (0.01,0) [0|50] "mOhm"  HVESP01
 SG_ HVESP01_brickResistance_48__8 m11: 50|14@1+ (0.01,0) [0|50] "mOhm"  HVESP01
 SG_ HVESP01_brickResistance_49__8 m12: 8|14@1+ (0.01,0) [0|50] "mOhm"  HVESP01
 SG_ HVESP01_brickResistance_50__8 m12: 22|14@1+ (0.01,0) [0|50] "mOhm"  HVESP01
 SG_ HVESP01_brickResistance_51__8 m12: 36|14@1+ (0.01,0) [0|50] "mOhm"  HVESP01
 SG_ HVESP01_brickResistance_52__8 m12: 50|14@1+ (0.01,0) [0|50] "mOhm"  HVESP01
 SG_ HVESP01_brickResistance_53__8 m13: 8|14@1+ (0.01,0) [0|50] "mOhm"  HVESP01
 SG_ HVESP01_brickResistance_54__8 m13: 22|14@1+ (0.01,0) [0|50] "mOhm"  HVESP01
 SG_ HVESP01_brickResistance_55__8 m13: 36|14@1+ (0.01,0) [0|50] "mOhm"  HVESP01
 SG_ HVESP01_brickResistance_56__8 m13: 50|14@1+ (0.01,0) [0|50] "mOhm"  HVESP01
 SG_ HVESP01_brickResistance_57__8 m14: 8|14@1+ (0.01,0) [0|50] "mOhm"  HVESP01
 SG_ HVESP01_brickResistance_58__8 m14: 22|14@1+ (0.01,0) [0|50] "mOhm"  HVESP01
 SG_ HVESP01_brickResistance_59__8 m14: 36|14@1+ (0.01,0) [0|50] "mOhm"  HVESP01
 SG_ HVESP01_brickResistance_60__8 m14: 50|14@1+ (0.01,0) [0|50] "mOhm"  HVESP01
 SG_ HVESP01_brickResistance_61__8 m15: 8|14@1+ (0.01,0) [0|50] "mOhm"  HVESP01
 SG_ HVESP01_brickResistance_62__8 m15: 22|14@1+ (0.01,0) [0|50] "mOhm"  HVESP01
 SG_ HVESP01_brickResistance_63__8 m15: 36|14@1+ (0.01,0) [0|50] "mOhm"  HVESP01
 SG_ HVESP01_brickResistance_64__8 m15: 50|14@1+ (0.01,0) [0|50] "mOhm"  HVESP01
 SG_ HVESP01_brickResistance_65__8 m16: 8|14@1+ (0.01,0) [0|50] "mOhm"  HVESP01
 SG_ HVESP01_brickResistance_66__8 m16: 22|14@1+ (0.01,0) [0|50] "mOhm"  HVESP01
 SG_ HVESP01_brickResistance_67__8 m16: 36|14@1+ (0.01,0) [0|50] "mOhm"  HVESP01
 SG_ HVESP01_brickResistance_68__8 m16: 50|14@1+ (0.01,0) [0|50] "mOhm"  HVESP01
 SG_ HVESP01_brickResistance_69__8 m17: 8|14@1+ (0.01,0) [0|50] "mOhm"  HVESP01
 SG_ HVESP01_brickResistance_70__8 m17: 22|14@1+ (0.01,0) [0|50] "mOhm"  HVESP01
 SG_ HVESP01_brickResistance_71__8 m17: 36|14@1+ (0.01,0) [0|50] "mOhm"  HVESP01
 SG_ HVESP01_brickResistance_72__8 m17: 50|14@1+ (0.01,0) [0|50] "mOhm"  HVESP01
 SG_ HVESP01_brickResistance_73__8 m18: 8|14@1+ (0.01,0) [0|50] "mOhm"  HVESP01
 SG_ HVESP01_brickResistance_74__8 m18: 22|14@1+ (0.01,0) [0|50] "mOhm"  HVESP01
 SG_ HVESP01_brickResistance_75__8 m18: 36|14@1+ (0.01,0) [0|50] "mOhm"  HVESP01
 SG_ HVESP01_brickResistance_76__8 m18: 50|14@1+ (0.01,0) [0|50] "mOhm"  HVESP01
 SG_ HVESP01_brickResistance_77__8 m19: 8|14@1+ (0.01,0) [0|50] "mOhm"  HVESP01
 SG_ HVESP01_brickResistance_78__8 m19: 22|14@1+ (0.01,0) [0|50] "mOhm"  HVESP01
 SG_ HVESP01_brickResistance_79__8 m19: 36|14@1+ (0.01,0) [0|50] "mOhm"  HVESP01
 SG_ HVESP01_brickResistance_80__8 m19: 50|14@1+ (0.01,0) [0|50] "mOhm"  HVESP01
 SG_ HVESP01_brickResistance_81__8 m20: 8|14@1+ (0.01,0) [0|50] "mOhm"  HVESP01
 SG_ HVESP01_brickResistance_82__8 m20: 22|14@1+ (0.01,0) [0|50] "mOhm"  HVESP01
 SG_ HVESP01_brickResistance_83__8 m20: 36|14@1+ (0.01,0) [0|50] "mOhm"  HVESP01
 SG_ HVESP01_brickResistance_84__8 m20: 50|14@1+ (0.01,0) [0|50] "mOhm"  HVESP01
 SG_ HVESP01_brickResistance_85__8 m21: 8|14@1+ (0.01,0) [0|50] "mOhm"  HVESP01
 SG_ HVESP01_brickResistance_86__8 m21: 22|14@1+ (0.01,0) [0|50] "mOhm"  HVESP01
 SG_ HVESP01_brickResistance_87__8 m21: 36|14@1+ (0.01,0) [0|50] "mOhm"  HVESP01
 SG_ HVESP01_brickResistance_88__8 m21: 50|14@1+ (0.01,0) [0|50] "mOhm"  HVESP01
 SG_ HVESP01_brickResistance_89__8 m22: 8|14@1+ (0.01,0) [0|50] "mOhm"  HVESP01
 SG_ HVESP01_brickResistance_90__8 m22: 22|14@1+ (0.01,0) [0|50] "mOhm"  HVESP01
 SG_ HVESP01_brickResistance_91__8 m22: 36|14@1+ (0.01,0) [0|50] "mOhm"  HVESP01
 SG_ HVESP01_brickResistance_92__8 m22: 50|14@1+ (0.01,0) [0|50] "mOhm"  HVESP01
 SG_ HVESP01_brickResistance_93__8 m23: 8|14@1+ (0.01,0) [0|50] "mOhm"  HVESP01
 SG_ HVESP01_brickResistance_94__8 m23: 22|14@1+ (0.01,0) [0|50] "mOhm"  HVESP01
 SG_ HVESP01_brickResistance_95__8 m23: 36|14@1+ (0.01,0) [0|50] "mOhm"  HVESP01
 SG_ HVESP01_brickResistance_96__8 m23: 50|14@1+ (0.01,0) [0|50] "mOhm"  HVESP01
 SG_ HVESP01_brickResistance_97__8 m24: 8|14@1+ (0.01,0) [0|50] "mOhm"  HVESP01
 SG_ HVESP01_brickResistance_98__8 m24: 22|14@1+ (0.01,0) [0|50] "mOhm"  HVESP01
 SG_ HVESP01_brickResistance_99__8 m24: 36|14@1+ (0.01,0) [0|50] "mOhm"  HVESP01
 SG_ HVESP01_brickResistance_100_8 m24: 50|14@1+ (0.01,0) [0|50] "mOhm"  HVESP01
 SG_ HVESP01_brickResistance_101_8 m25: 8|14@1+ (0.01,0) [0|50] "mOhm"  HVESP01
 SG_ HVESP01_brickResistance_102_8 m25: 22|14@1+ (0.01,0) [0|50] "mOhm"  HVESP01
 SG_ HVESP01_brickResistance_103_8 m25: 36|14@1+ (0.01,0) [0|50] "mOhm"  HVESP01
 SG_ HVESP01_brickResistance_104_8 m25: 50|14@1+ (0.01,0) [0|50] "mOhm"  HVESP01
 SG_ HVESP01_brickResistance_105_8 m26: 8|14@1+ (0.01,0) [0|50] "mOhm"  HVESP01
 SG_ HVESP01_brickResistance_106_8 m26: 22|14@1+ (0.01,0) [0|50] "mOhm"  HVESP01
 SG_ HVESP01_brickResistance_107_8 m26: 36|14@1+ (0.01,0) [0|50] "mOhm"  HVESP01
 SG_ HVESP01_brickResistance_108_8 m26: 50|14@1+ (0.01,0) [0|50] "mOhm"  HVESP01
 SG_ HVESP01_brickResistance_109_8 m27: 8|14@1+ (0.01,0) [0|50] "mOhm"  HVESP01
 SG_ HVESP01_brickResistance_110_8 m27: 22|14@1+ (0.01,0) [0|50] "mOhm"  HVESP01
 SG_ HVESP01_brickResistance_111_8 m27: 36|14@1+ (0.01,0) [0|50] "mOhm"  HVESP01
 SG_ HVESP01_brickResistance_112_8 m27: 50|14@1+ (0.01,0) [0|50] "mOhm"  HVESP01
 SG_ HVESP01_brickResistance_113_8 m28: 8|14@1+ (0.01,0) [0|50] "mOhm"  HVESP01
 SG_ HVESP01_brickResistance_114_8 m28: 22|14@1+ (0.01,0) [0|50] "mOhm"  HVESP01
 SG_ HVESP01_brickResistance_115_8 m28: 36|14@1+ (0.01,0) [0|50] "mOhm"  HVESP01
 SG_ HVESP01_brickResistance_116_8 m28: 50|14@1+ (0.01,0) [0|50] "mOhm"  HVESP01
 SG_ HVESP01_brickResistance_117_8 m29: 8|14@1+ (0.01,0) [0|50] "mOhm"  HVESP01
 SG_ HVESP01_brickResistance_118_8 m29: 22|14@1+ (0.01,0) [0|50] "mOhm"  HVESP01
 SG_ HVESP01_brickResistance_119_8 m29: 36|14@1+ (0.01,0) [0|50] "mOhm"  HVESP01
 SG_ HVESP01_brickResistance_120_8 m29: 50|14@1+ (0.01,0) [0|50] "mOhm"  HVESP01
 SG_ HVESP01_brickResistance_121_8 m30: 8|14@1+ (0.01,0) [0|50] "mOhm"  HVESP01
 SG_ HVESP01_brickResistance_122_8 m30: 22|14@1+ (0.01,0) [0|50] "mOhm"  HVESP01
 SG_ HVESP01_brickResistance_123_8 m30: 36|14@1+ (0.01,0) [0|50] "mOhm"  HVESP01
 SG_ HVESP01_brickResistance_124_8 m30: 50|14@1+ (0.01,0) [0|50] "mOhm"  HVESP01
 SG_ HVESP01_brickResistance_125_8 m31: 8|14@1+ (0.01,0) [0|50] "mOhm"  HVESP01
 SG_ HVESP01_brickResistance_126_8 m31: 22|14@1+ (0.01,0) [0|50] "mOhm"  HVESP01
 SG_ HVESP01_brickResistance_127_8 m31: 36|14@1+ (0.01,0) [0|50] "mOhm"  HVESP01
 SG_ HVESP01_brickResistance_128_8 m31: 50|14@1+ (0.01,0) [0|50] "mOhm"  HVESP01
 SG_ HVESP01_brickResistance_129_8 m32: 8|14@1+ (0.01,0) [0|50] "mOhm"  HVESP01
 SG_ HVESP01_brickResistance_130_8 m32: 22|14@1+ (0.01,0) [0|50] "mOhm"  HVESP01
 SG_ HVESP01_brickResistance_131_8 m32: 36|14@1+ (0.01,0) [0|50] "mOhm"  HVESP01
 SG_ HVESP01_brickResistance_132_8 m32: 50|14@1+ (0.01,0) [0|50] "mOhm"  HVESP01
 SG_ HVESP01_brickResistance_133_8 m33: 8|14@1+ (0.01,0) [0|50] "mOhm"  HVESP01
 SG_ HVESP01_brickResistance_134_8 m33: 22|14@1+ (0.01,0) [0|50] "mOhm"  HVESP01
 SG_ HVESP01_brickResistance_135_8 m33: 36|14@1+ (0.01,0) [0|50] "mOhm"  HVESP01
 SG_ HVESP01_brickResistance_136_8 m33: 50|14@1+ (0.01,0) [0|50] "mOhm"  HVESP01
 SG_ HVESP01_brickResistance_137_8 m34: 8|14@1+ (0.01,0) [0|50] "mOhm"  HVESP01
 SG_ HVESP01_brickResistance_138_8 m34: 22|14@1+ (0.01,0) [0|50] "mOhm"  HVESP01
 SG_ HVESP01_brickResistance_139_8 m34: 36|14@1+ (0.01,0) [0|50] "mOhm"  HVESP01
 SG_ HVESP01_brickResistance_140_8 m34: 50|14@1+ (0.01,0) [0|50] "mOhm"  HVESP01
 SG_ HVESP01_brickResistance_141_8 m35: 8|14@1+ (0.01,0) [0|50] "mOhm"  HVESP01
 SG_ HVESP01_brickResistance_142_8 m35: 22|14@1+ (0.01,0) [0|50] "mOhm"  HVESP01
 SG_ HVESP01_brickResistance_143_8 m35: 36|14@1+ (0.01,0) [0|50] "mOhm"  HVESP01
 SG_ HVESP01_brickResistance_144_8 m35: 50|14@1+ (0.01,0) [0|50] "mOhm"  HVESP01
 SG_ HVESP01_brickResistance_145_8 m36: 8|14@1+ (0.01,0) [0|50] "mOhm"  HVESP01
 SG_ HVESP01_brickResistance_146_8 m36: 22|14@1+ (0.01,0) [0|50] "mOhm"  HVESP01
 SG_ HVESP01_brickResistance_147_8 m36: 36|14@1+ (0.01,0) [0|50] "mOhm"  HVESP01
 SG_ HVESP01_brickResistance_148_8 m36: 50|14@1+ (0.01,0) [0|50] "mOhm"  HVESP01
 SG_ HVESP01_brickResistance_149_8 m37: 8|14@1+ (0.01,0) [0|50] "mOhm"  HVESP01
 SG_ HVESP01_brickResistance_150_8 m37: 22|14@1+ (0.01,0) [0|50] "mOhm"  HVESP01
 SG_ HVESP01_brickResistance_151_8 m37: 36|14@1+ (0.01,0) [0|50] "mOhm"  HVESP01
 SG_ HVESP01_brickResistance_152_8 m37: 50|14@1+ (0.01,0) [0|50] "mOhm"  HVESP01
 SG_ HVESP01_brickResistance_153_8 m38: 8|14@1+ (0.01,0) [0|50] "mOhm"  HVESP01
 SG_ HVESP01_brickResistance_154_8 m38: 22|14@1+ (0.01,0) [0|50] "mOhm"  HVESP01
 SG_ HVESP01_brickResistance_155_8 m38: 36|14@1+ (0.01,0) [0|50] "mOhm"  HVESP01
 SG_ HVESP01_brickResistance_156_8 m38: 50|14@1+ (0.01,0) [0|50] "mOhm"  HVESP01
 SG_ HVESP01_brickResistance_157_8 m39: 8|14@1+ (0.01,0) [0|50] "mOhm"  HVESP01
 SG_ HVESP01_brickResistance_158_8 m39: 22|14@1+ (0.01,0) [0|50] "mOhm"  HVESP01
 SG_ HVESP01_brickResistance_159_8 m39: 36|14@1+ (0.01,0) [0|50] "mOhm"  HVESP01
 SG_ HVESP01_brickResistance_160_8 m39: 50|14@1+ (0.01,0) [0|50] "mOhm"  HVESP01
 SG_ HVESP01_brickResistance_161_8 m40: 8|14@1+ (0.01,0) [0|50] "mOhm"  HVESP01
 SG_ HVESP01_brickResistance_162_8 m40: 22|14@1+ (0.01,0) [0|50] "mOhm"  HVESP01
 SG_ HVESP01_brickResistance_163_8 m40: 36|14@1+ (0.01,0) [0|50] "mOhm"  HVESP01
 SG_ HVESP01_brickResistance_164_8 m40: 50|14@1+ (0.01,0) [0|50] "mOhm"  HVESP01
 SG_ HVESP01_brickResistance_165_8 m41: 8|14@1+ (0.01,0) [0|50] "mOhm"  HVESP01
 SG_ HVESP01_brickResistance_166_8 m41: 22|14@1+ (0.01,0) [0|50] "mOhm"  HVESP01
 SG_ HVESP01_brickResistance_167_8 m41: 36|14@1+ (0.01,0) [0|50] "mOhm"  HVESP01
 SG_ HVESP01_brickResistance_168_8 m41: 50|14@1+ (0.01,0) [0|50] "mOhm"  HVESP01
 SG_ HVESP01_brickResistance_169_8 m42: 8|14@1+ (0.01,0) [0|50] "mOhm"  HVESP01
 SG_ HVESP01_brickResistance_170_8 m42: 22|14@1+ (0.01,0) [0|50] "mOhm"  HVESP01
 SG_ HVESP01_brickResistance_171_8 m42: 36|14@1+ (0.01,0) [0|50] "mOhm"  HVESP01
 SG_ HVESP01_brickResistance_172_8 m42: 50|14@1+ (0.01,0) [0|50] "mOhm"  HVESP01
 SG_ HVESP01_brickResistance_173_8 m43: 8|14@1+ (0.01,0) [0|50] "mOhm"  HVESP01
 SG_ HVESP01_brickResistance_174_8 m43: 22|14@1+ (0.01,0) [0|50] "mOhm"  HVESP01
 SG_ HVESP01_brickResistance_175_8 m43: 36|14@1+ (0.01,0) [0|50] "mOhm"  HVESP01
 SG_ HVESP01_brickResistance_176_8 m43: 50|14@1+ (0.01,0) [0|50] "mOhm"  HVESP01
 SG_ HVESP01_brickResistance_177_8 m44: 8|14@1+ (0.01,0) [0|50] "mOhm"  HVESP01
 SG_ HVESP01_brickResistance_178_8 m44: 22|14@1+ (0.01,0) [0|50] "mOhm"  HVESP01
 SG_ HVESP01_brickResistance_179_8 m44: 36|14@1+ (0.01,0) [0|50] "mOhm"  HVESP01
 SG_ HVESP01_brickResistance_180_8 m44: 50|14@1+ (0.01,0) [0|50] "mOhm"  HVESP01
 SG_ HVESP01_brickResistance_181_8 m45: 8|14@1+ (0.01,0) [0|50] "mOhm"  HVESP01
 SG_ HVESP01_brickResistance_182_8 m45: 22|14@1+ (0.01,0) [0|50] "mOhm"  HVESP01
 SG_ HVESP01_brickResistance_183_8 m45: 36|14@1+ (0.01,0) [0|50] "mOhm"  HVESP01
 SG_ HVESP01_brickResistance_184_8 m45: 50|14@1+ (0.01,0) [0|50] "mOhm"  HVESP01
 SG_ HVESP01_brickResistance_185_8 m46: 8|14@1+ (0.01,0) [0|50] "mOhm"  HVESP01
 SG_ HVESP01_brickResistance_186_8 m46: 22|14@1+ (0.01,0) [0|50] "mOhm"  HVESP01
 SG_ HVESP01_brickResistance_187_8 m46: 36|14@1+ (0.01,0) [0|50] "mOhm"  HVESP01
 SG_ HVESP01_brickResistance_188_8 m46: 50|14@1+ (0.01,0) [0|50] "mOhm"  HVESP01
 SG_ HVESP01_brickResistance_189_8 m47: 8|14@1+ (0.01,0) [0|50] "mOhm"  HVESP01
 SG_ HVESP01_brickResistance_190_8 m47: 22|14@1+ (0.01,0) [0|50] "mOhm"  HVESP01
 SG_ HVESP01_brickResistance_191_8 m47: 36|14@1+ (0.01,0) [0|50] "mOhm"  HVESP01
 SG_ HVESP01_brickResistance_192_8 m47: 50|14@1+ (0.01,0) [0|50] "mOhm"  HVESP01
 SG_ multiplexorbr_8 M: 0|8@1+ (1,0) [0|255] ""  HVESP01

BO_ 2499742053 HVESP01_modTemperature_1: 8 HVESP01
 SG_ HVESP01_modTemperature_01_1 m0: 16|8@1- (1,25) [-103|152] "Celsius"  HVESP01
 SG_ HVESP01_modTemperature_02_1 m0: 24|8@1- (1,25) [-103|152] "Celsius"  HVESP01
 SG_ HVESP01_modTemperature_03_1 m0: 32|8@1- (1,25) [-103|152] "Celsius"  HVESP01
 SG_ HVESP01_modTemperature_04_1 m0: 40|8@1- (1,25) [-103|152] "Celsius"  HVESP01
 SG_ HVESP01_modTemperature_05_1 m0: 48|8@1- (1,25) [-103|152] "Celsius"  HVESP01
 SG_ HVESP01_modTemperature_06_1 m1: 16|8@1- (1,25) [-103|152] "Celsius"  HVESP01
 SG_ HVESP01_modTemperature_07_1 m1: 24|8@1- (1,25) [-103|152] "Celsius"  HVESP01
 SG_ HVESP01_modTemperature_08_1 m1: 32|8@1- (1,25) [-103|152] "Celsius"  HVESP01
 SG_ HVESP01_modTemperature_09_1 m1: 40|8@1- (1,25) [-103|152] "Celsius"  HVESP01
 SG_ HVESP01_modTemperature_10_1 m1: 48|8@1- (1,25) [-103|152] "Celsius"  HVESP01
 SG_ HVESP01_modTemperature_11_1 m2: 16|8@1- (1,25) [-103|152] "Celsius"  HVESP01
 SG_ HVESP01_modTemperature_12_1 m2: 24|8@1- (1,25) [-103|152] "Celsius"  HVESP01
 SG_ HVESP01_modTemperature_13_1 m2: 32|8@1- (1,25) [-103|152] "Celsius"  HVESP01
 SG_ HVESP01_modTemperature_14_1 m2: 40|8@1- (1,25) [-103|152] "Celsius"  HVESP01
 SG_ HVESP01_modTemperature_15_1 m2: 48|8@1- (1,25) [-103|152] "Celsius"  HVESP01
 SG_ HVESP01_modTemperature_16_1 m3: 16|8@1- (1,25) [-103|152] "Celsius"  HVESP01
 SG_ HVESP01_modTemperature_17_1 m3: 24|8@1- (1,25) [-103|152] "Celsius"  HVESP01
 SG_ HVESP01_modTemperature_18_1 m3: 32|8@1- (1,25) [-103|152] "Celsius"  HVESP01
 SG_ HVESP01_modTemperature_19_1 m3: 40|8@1- (1,25) [-103|152] "Celsius"  HVESP01
 SG_ HVESP01_modTemperature_20_1 m3: 48|8@1- (1,25) [-103|152] "Celsius"  HVESP01
 SG_ HVESP01_modTemperature_21_1 m4: 16|8@1- (1,25) [-103|152] "Celsius"  HVESP01
 SG_ HVESP01_modTemperature_22_1 m4: 24|8@1- (1,25) [-103|152] "Celsius"  HVESP01
 SG_ HVESP01_modTemperature_23_1 m4: 32|8@1- (1,25) [-103|152] "Celsius"  HVESP01
 SG_ HVESP01_modTemperature_24_1 m4: 40|8@1- (1,25) [-103|152] "Celsius"  HVESP01
 SG_ HVESP01_modTemperature_25_1 m4: 48|8@1- (1,25) [-103|152] "Celsius"  HVESP01
 SG_ HVESP01_modTemperature_26_1 m5: 16|8@1- (1,25) [-103|152] "Celsius"  HVESP01
 SG_ HVESP01_modTemperature_27_1 m5: 24|8@1- (1,25) [-103|152] "Celsius"  HVESP01
 SG_ HVESP01_modTemperature_28_1 m5: 32|8@1- (1,25) [-103|152] "Celsius"  HVESP01
 SG_ HVESP01_modTemperature_29_1 m5: 40|8@1- (1,25) [-103|152] "Celsius"  HVESP01
 SG_ HVESP01_modTemperature_30_1 m5: 48|8@1- (1,25) [-103|152] "Celsius"  HVESP01
 SG_ HVESP01_modTemperature_31_1 m6: 16|8@1- (1,25) [-103|152] "Celsius"  HVESP01
 SG_ HVESP01_modTemperature_32_1 m6: 24|8@1- (1,25) [-103|152] "Celsius"  HVESP01
 SG_ HVESP01_modTemperature_33_1 m6: 32|8@1- (1,25) [-103|152] "Celsius"  HVESP01
 SG_ HVESP01_modTemperature_34_1 m6: 40|8@1- (1,25) [-103|152] "Celsius"  HVESP01
 SG_ HVESP01_modTemperature_35_1 m6: 48|8@1- (1,25) [-103|152] "Celsius"  HVESP01
 SG_ HVESP01_modTemperature_36_1 m7: 16|8@1- (1,25) [-103|152] "Celsius"  HVESP01
 SG_ HVESP01_modTemperature_37_1 m7: 24|8@1- (1,25) [-103|152] "Celsius"  HVESP01
 SG_ HVESP01_modTemperature_38_1 m7: 32|8@1- (1,25) [-103|152] "Celsius"  HVESP01
 SG_ HVESP01_modTemperature_39_1 m7: 40|8@1- (1,25) [-103|152] "Celsius"  HVESP01
 SG_ HVESP01_modTemperature_40_1 m7: 48|8@1- (1,25) [-103|152] "Celsius"  HVESP01
 SG_ HVESP01_modTemperature_41_1 m8: 16|8@1- (1,25) [-103|152] "Celsius"  HVESP01
 SG_ HVESP01_modTemperature_42_1 m8: 24|8@1- (1,25) [-103|152] "Celsius"  HVESP01
 SG_ HVESP01_modTemperature_43_1 m8: 32|8@1- (1,25) [-103|152] "Celsius"  HVESP01
 SG_ HVESP01_modTemperature_44_1 m8: 40|8@1- (1,25) [-103|152] "Celsius"  HVESP01
 SG_ HVESP01_modTemperature_45_1 m8: 48|8@1- (1,25) [-103|152] "Celsius"  HVESP01
 SG_ HVESP01_modTemperature_46_1 m9: 16|8@1- (1,25) [-103|152] "Celsius"  HVESP01
 SG_ HVESP01_modTemperature_47_1 m9: 24|8@1- (1,25) [-103|152] "Celsius"  HVESP01
 SG_ HVESP01_modTemperature_48_1 m9: 32|8@1- (1,25) [-103|152] "Celsius"  HVESP01
 SG_ HVESP01_modTemperature_49_1 m9: 40|8@1- (1,25) [-103|152] "Celsius"  HVESP01
 SG_ HVESP01_modTemperature_50_1 m9: 48|8@1- (1,25) [-103|152] "Celsius"  HVESP01
 SG_ multiplexormt_1 M: 0|9@1+ (1,0) [0|255] ""  HVESP01

BO_ 2499742054 HVESP01_modTemperature_2: 8 HVESP01
 SG_ HVESP01_modTemperature_01_2 m0: 16|8@1- (1,25) [-103|152] "Celsius"  HVESP01
 SG_ HVESP01_modTemperature_02_2 m0: 24|8@1- (1,25) [-103|152] "Celsius"  HVESP01
 SG_ HVESP01_modTemperature_03_2 m0: 32|8@1- (1,25) [-103|152] "Celsius"  HVESP01
 SG_ HVESP01_modTemperature_04_2 m0: 40|8@1- (1,25) [-103|152] "Celsius"  HVESP01
 SG_ HVESP01_modTemperature_05_2 m0: 48|8@1- (1,25) [-103|152] "Celsius"  HVESP01
 SG_ HVESP01_modTemperature_06_2 m1: 16|8@1- (1,25) [-103|152] "Celsius"  HVESP01
 SG_ HVESP01_modTemperature_07_2 m1: 24|8@1- (1,25) [-103|152] "Celsius"  HVESP01
 SG_ HVESP01_modTemperature_08_2 m1: 32|8@1- (1,25) [-103|152] "Celsius"  HVESP01
 SG_ HVESP01_modTemperature_09_2 m1: 40|8@1- (1,25) [-103|152] "Celsius"  HVESP01
 SG_ HVESP01_modTemperature_10_2 m1: 48|8@1- (1,25) [-103|152] "Celsius"  HVESP01
 SG_ HVESP01_modTemperature_11_2 m2: 16|8@1- (1,25) [-103|152] "Celsius"  HVESP01
 SG_ HVESP01_modTemperature_12_2 m2: 24|8@1- (1,25) [-103|152] "Celsius"  HVESP01
 SG_ HVESP01_modTemperature_13_2 m2: 32|8@1- (1,25) [-103|152] "Celsius"  HVESP01
 SG_ HVESP01_modTemperature_14_2 m2: 40|8@1- (1,25) [-103|152] "Celsius"  HVESP01
 SG_ HVESP01_modTemperature_15_2 m2: 48|8@1- (1,25) [-103|152] "Celsius"  HVESP01
 SG_ HVESP01_modTemperature_16_2 m3: 16|8@1- (1,25) [-103|152] "Celsius"  HVESP01
 SG_ HVESP01_modTemperature_17_2 m3: 24|8@1- (1,25) [-103|152] "Celsius"  HVESP01
 SG_ HVESP01_modTemperature_18_2 m3: 32|8@1- (1,25) [-103|152] "Celsius"  HVESP01
 SG_ HVESP01_modTemperature_19_2 m3: 40|8@1- (1,25) [-103|152] "Celsius"  HVESP01
 SG_ HVESP01_modTemperature_20_2 m3: 48|8@1- (1,25) [-103|152] "Celsius"  HVESP01
 SG_ HVESP01_modTemperature_21_2 m4: 16|8@1- (1,25) [-103|152] "Celsius"  HVESP01
 SG_ HVESP01_modTemperature_22_2 m4: 24|8@1- (1,25) [-103|152] "Celsius"  HVESP01
 SG_ HVESP01_modTemperature_23_2 m4: 32|8@1- (1,25) [-103|152] "Celsius"  HVESP01
 SG_ HVESP01_modTemperature_24_2 m4: 40|8@1- (1,25) [-103|152] "Celsius"  HVESP01
 SG_ HVESP01_modTemperature_25_2 m4: 48|8@1- (1,25) [-103|152] "Celsius"  HVESP01
 SG_ HVESP01_modTemperature_26_2 m5: 16|8@1- (1,25) [-103|152] "Celsius"  HVESP01
 SG_ HVESP01_modTemperature_27_2 m5: 24|8@1- (1,25) [-103|152] "Celsius"  HVESP01
 SG_ HVESP01_modTemperature_28_2 m5: 32|8@1- (1,25) [-103|152] "Celsius"  HVESP01
 SG_ HVESP01_modTemperature_29_2 m5: 40|8@1- (1,25) [-103|152] "Celsius"  HVESP01
 SG_ HVESP01_modTemperature_30_2 m5: 48|8@1- (1,25) [-103|152] "Celsius"  HVESP01
 SG_ HVESP01_modTemperature_31_2 m6: 16|8@1- (1,25) [-103|152] "Celsius"  HVESP01
 SG_ HVESP01_modTemperature_32_2 m6: 24|8@1- (1,25) [-103|152] "Celsius"  HVESP01
 SG_ HVESP01_modTemperature_33_2 m6: 32|8@1- (1,25) [-103|152] "Celsius"  HVESP01
 SG_ HVESP01_modTemperature_34_2 m6: 40|8@1- (1,25) [-103|152] "Celsius"  HVESP01
 SG_ HVESP01_modTemperature_35_2 m6: 48|8@1- (1,25) [-103|152] "Celsius"  HVESP01
 SG_ HVESP01_modTemperature_36_2 m7: 16|8@1- (1,25) [-103|152] "Celsius"  HVESP01
 SG_ HVESP01_modTemperature_37_2 m7: 24|8@1- (1,25) [-103|152] "Celsius"  HVESP01
 SG_ HVESP01_modTemperature_38_2 m7: 32|8@1- (1,25) [-103|152] "Celsius"  HVESP01
 SG_ HVESP01_modTemperature_39_2 m7: 40|8@1- (1,25) [-103|152] "Celsius"  HVESP01
 SG_ HVESP01_modTemperature_40_2 m7: 48|8@1- (1,25) [-103|152] "Celsius"  HVESP01
 SG_ HVESP01_modTemperature_41_2 m8: 16|8@1- (1,25) [-103|152] "Celsius"  HVESP01
 SG_ HVESP01_modTemperature_42_2 m8: 24|8@1- (1,25) [-103|152] "Celsius"  HVESP01
 SG_ HVESP01_modTemperature_43_2 m8: 32|8@1- (1,25) [-103|152] "Celsius"  HVESP01
 SG_ HVESP01_modTemperature_44_2 m8: 40|8@1- (1,25) [-103|152] "Celsius"  HVESP01
 SG_ HVESP01_modTemperature_45_2 m8: 48|8@1- (1,25) [-103|152] "Celsius"  HVESP01
 SG_ HVESP01_modTemperature_46_2 m9: 16|8@1- (1,25) [-103|152] "Celsius"  HVESP01
 SG_ HVESP01_modTemperature_47_2 m9: 24|8@1- (1,25) [-103|152] "Celsius"  HVESP01
 SG_ HVESP01_modTemperature_48_2 m9: 32|8@1- (1,25) [-103|152] "Celsius"  HVESP01
 SG_ HVESP01_modTemperature_49_2 m9: 40|8@1- (1,25) [-103|152] "Celsius"  HVESP01
 SG_ HVESP01_modTemperature_50_2 m9: 48|8@1- (1,25) [-103|152] "Celsius"  HVESP01
 SG_ multiplexormt_2 M: 0|9@1+ (1,0) [0|255] ""  HVESP01

BO_ 2499742055 HVESP01_modTemperature_3: 8 HVESP01
 SG_ HVESP01_modTemperature_01_3 m0: 16|8@1- (1,25) [-103|152] "Celsius"  HVESP01
 SG_ HVESP01_modTemperature_02_3 m0: 24|8@1- (1,25) [-103|152] "Celsius"  HVESP01
 SG_ HVESP01_modTemperature_03_3 m0: 32|8@1- (1,25) [-103|152] "Celsius"  HVESP01
 SG_ HVESP01_modTemperature_04_3 m0: 40|8@1- (1,25) [-103|152] "Celsius"  HVESP01
 SG_ HVESP01_modTemperature_05_3 m0: 48|8@1- (1,25) [-103|152] "Celsius"  HVESP01
 SG_ HVESP01_modTemperature_06_3 m1: 16|8@1- (1,25) [-103|152] "Celsius"  HVESP01
 SG_ HVESP01_modTemperature_07_3 m1: 24|8@1- (1,25) [-103|152] "Celsius"  HVESP01
 SG_ HVESP01_modTemperature_08_3 m1: 32|8@1- (1,25) [-103|152] "Celsius"  HVESP01
 SG_ HVESP01_modTemperature_09_3 m1: 40|8@1- (1,25) [-103|152] "Celsius"  HVESP01
 SG_ HVESP01_modTemperature_10_3 m1: 48|8@1- (1,25) [-103|152] "Celsius"  HVESP01
 SG_ HVESP01_modTemperature_11_3 m2: 16|8@1- (1,25) [-103|152] "Celsius"  HVESP01
 SG_ HVESP01_modTemperature_12_3 m2: 24|8@1- (1,25) [-103|152] "Celsius"  HVESP01
 SG_ HVESP01_modTemperature_13_3 m2: 32|8@1- (1,25) [-103|152] "Celsius"  HVESP01
 SG_ HVESP01_modTemperature_14_3 m2: 40|8@1- (1,25) [-103|152] "Celsius"  HVESP01
 SG_ HVESP01_modTemperature_15_3 m2: 48|8@1- (1,25) [-103|152] "Celsius"  HVESP01
 SG_ HVESP01_modTemperature_16_3 m3: 16|8@1- (1,25) [-103|152] "Celsius"  HVESP01
 SG_ HVESP01_modTemperature_17_3 m3: 24|8@1- (1,25) [-103|152] "Celsius"  HVESP01
 SG_ HVESP01_modTemperature_18_3 m3: 32|8@1- (1,25) [-103|152] "Celsius"  HVESP01
 SG_ HVESP01_modTemperature_19_3 m3: 40|8@1- (1,25) [-103|152] "Celsius"  HVESP01
 SG_ HVESP01_modTemperature_20_3 m3: 48|8@1- (1,25) [-103|152] "Celsius"  HVESP01
 SG_ HVESP01_modTemperature_21_3 m4: 16|8@1- (1,25) [-103|152] "Celsius"  HVESP01
 SG_ HVESP01_modTemperature_22_3 m4: 24|8@1- (1,25) [-103|152] "Celsius"  HVESP01
 SG_ HVESP01_modTemperature_23_3 m4: 32|8@1- (1,25) [-103|152] "Celsius"  HVESP01
 SG_ HVESP01_modTemperature_24_3 m4: 40|8@1- (1,25) [-103|152] "Celsius"  HVESP01
 SG_ HVESP01_modTemperature_25_3 m4: 48|8@1- (1,25) [-103|152] "Celsius"  HVESP01
 SG_ HVESP01_modTemperature_26_3 m5: 16|8@1- (1,25) [-103|152] "Celsius"  HVESP01
 SG_ HVESP01_modTemperature_27_3 m5: 24|8@1- (1,25) [-103|152] "Celsius"  HVESP01
 SG_ HVESP01_modTemperature_28_3 m5: 32|8@1- (1,25) [-103|152] "Celsius"  HVESP01
 SG_ HVESP01_modTemperature_29_3 m5: 40|8@1- (1,25) [-103|152] "Celsius"  HVESP01
 SG_ HVESP01_modTemperature_30_3 m5: 48|8@1- (1,25) [-103|152] "Celsius"  HVESP01
 SG_ HVESP01_modTemperature_31_3 m6: 16|8@1- (1,25) [-103|152] "Celsius"  HVESP01
 SG_ HVESP01_modTemperature_32_3 m6: 24|8@1- (1,25) [-103|152] "Celsius"  HVESP01
 SG_ HVESP01_modTemperature_33_3 m6: 32|8@1- (1,25) [-103|152] "Celsius"  HVESP01
 SG_ HVESP01_modTemperature_34_3 m6: 40|8@1- (1,25) [-103|152] "Celsius"  HVESP01
 SG_ HVESP01_modTemperature_35_3 m6: 48|8@1- (1,25) [-103|152] "Celsius"  HVESP01
 SG_ HVESP01_modTemperature_36_3 m7: 16|8@1- (1,25) [-103|152] "Celsius"  HVESP01
 SG_ HVESP01_modTemperature_37_3 m7: 24|8@1- (1,25) [-103|152] "Celsius"  HVESP01
 SG_ HVESP01_modTemperature_38_3 m7: 32|8@1- (1,25) [-103|152] "Celsius"  HVESP01
 SG_ HVESP01_modTemperature_39_3 m7: 40|8@1- (1,25) [-103|152] "Celsius"  HVESP01
 SG_ HVESP01_modTemperature_40_3 m7: 48|8@1- (1,25) [-103|152] "Celsius"  HVESP01
 SG_ HVESP01_modTemperature_41_3 m8: 16|8@1- (1,25) [-103|152] "Celsius"  HVESP01
 SG_ HVESP01_modTemperature_42_3 m8: 24|8@1- (1,25) [-103|152] "Celsius"  HVESP01
 SG_ HVESP01_modTemperature_43_3 m8: 32|8@1- (1,25) [-103|152] "Celsius"  HVESP01
 SG_ HVESP01_modTemperature_44_3 m8: 40|8@1- (1,25) [-103|152] "Celsius"  HVESP01
 SG_ HVESP01_modTemperature_45_3 m8: 48|8@1- (1,25) [-103|152] "Celsius"  HVESP01
 SG_ HVESP01_modTemperature_46_3 m9: 16|8@1- (1,25) [-103|152] "Celsius"  HVESP01
 SG_ HVESP01_modTemperature_47_3 m9: 24|8@1- (1,25) [-103|152] "Celsius"  HVESP01
 SG_ HVESP01_modTemperature_48_3 m9: 32|8@1- (1,25) [-103|152] "Celsius"  HVESP01
 SG_ HVESP01_modTemperature_49_3 m9: 40|8@1- (1,25) [-103|152] "Celsius"  HVESP01
 SG_ HVESP01_modTemperature_50_3 m9: 48|8@1- (1,25) [-103|152] "Celsius"  HVESP01
 SG_ multiplexormt_3 M: 0|9@1+ (1,0) [0|255] ""  HVESP01

BO_ 2499742056 HVESP01_modTemperature_4: 8 HVESP01
 SG_ HVESP01_modTemperature_01_4 m0: 16|8@1- (1,25) [-103|152] "Celsius"  HVESP01
 SG_ HVESP01_modTemperature_02_4 m0: 24|8@1- (1,25) [-103|152] "Celsius"  HVESP01
 SG_ HVESP01_modTemperature_03_4 m0: 32|8@1- (1,25) [-103|152] "Celsius"  HVESP01
 SG_ HVESP01_modTemperature_04_4 m0: 40|8@1- (1,25) [-103|152] "Celsius"  HVESP01
 SG_ HVESP01_modTemperature_05_4 m0: 48|8@1- (1,25) [-103|152] "Celsius"  HVESP01
 SG_ HVESP01_modTemperature_06_4 m1: 16|8@1- (1,25) [-103|152] "Celsius"  HVESP01
 SG_ HVESP01_modTemperature_07_4 m1: 24|8@1- (1,25) [-103|152] "Celsius"  HVESP01
 SG_ HVESP01_modTemperature_08_4 m1: 32|8@1- (1,25) [-103|152] "Celsius"  HVESP01
 SG_ HVESP01_modTemperature_09_4 m1: 40|8@1- (1,25) [-103|152] "Celsius"  HVESP01
 SG_ HVESP01_modTemperature_10_4 m1: 48|8@1- (1,25) [-103|152] "Celsius"  HVESP01
 SG_ HVESP01_modTemperature_11_4 m2: 16|8@1- (1,25) [-103|152] "Celsius"  HVESP01
 SG_ HVESP01_modTemperature_12_4 m2: 24|8@1- (1,25) [-103|152] "Celsius"  HVESP01
 SG_ HVESP01_modTemperature_13_4 m2: 32|8@1- (1,25) [-103|152] "Celsius"  HVESP01
 SG_ HVESP01_modTemperature_14_4 m2: 40|8@1- (1,25) [-103|152] "Celsius"  HVESP01
 SG_ HVESP01_modTemperature_15_4 m2: 48|8@1- (1,25) [-103|152] "Celsius"  HVESP01
 SG_ HVESP01_modTemperature_16_4 m3: 16|8@1- (1,25) [-103|152] "Celsius"  HVESP01
 SG_ HVESP01_modTemperature_17_4 m3: 24|8@1- (1,25) [-103|152] "Celsius"  HVESP01
 SG_ HVESP01_modTemperature_18_4 m3: 32|8@1- (1,25) [-103|152] "Celsius"  HVESP01
 SG_ HVESP01_modTemperature_19_4 m3: 40|8@1- (1,25) [-103|152] "Celsius"  HVESP01
 SG_ HVESP01_modTemperature_20_4 m3: 48|8@1- (1,25) [-103|152] "Celsius"  HVESP01
 SG_ HVESP01_modTemperature_21_4 m4: 16|8@1- (1,25) [-103|152] "Celsius"  HVESP01
 SG_ HVESP01_modTemperature_22_4 m4: 24|8@1- (1,25) [-103|152] "Celsius"  HVESP01
 SG_ HVESP01_modTemperature_23_4 m4: 32|8@1- (1,25) [-103|152] "Celsius"  HVESP01
 SG_ HVESP01_modTemperature_24_4 m4: 40|8@1- (1,25) [-103|152] "Celsius"  HVESP01
 SG_ HVESP01_modTemperature_25_4 m4: 48|8@1- (1,25) [-103|152] "Celsius"  HVESP01
 SG_ HVESP01_modTemperature_26_4 m5: 16|8@1- (1,25) [-103|152] "Celsius"  HVESP01
 SG_ HVESP01_modTemperature_27_4 m5: 24|8@1- (1,25) [-103|152] "Celsius"  HVESP01
 SG_ HVESP01_modTemperature_28_4 m5: 32|8@1- (1,25) [-103|152] "Celsius"  HVESP01
 SG_ HVESP01_modTemperature_29_4 m5: 40|8@1- (1,25) [-103|152] "Celsius"  HVESP01
 SG_ HVESP01_modTemperature_30_4 m5: 48|8@1- (1,25) [-103|152] "Celsius"  HVESP01
 SG_ HVESP01_modTemperature_31_4 m6: 16|8@1- (1,25) [-103|152] "Celsius"  HVESP01
 SG_ HVESP01_modTemperature_32_4 m6: 24|8@1- (1,25) [-103|152] "Celsius"  HVESP01
 SG_ HVESP01_modTemperature_33_4 m6: 32|8@1- (1,25) [-103|152] "Celsius"  HVESP01
 SG_ HVESP01_modTemperature_34_4 m6: 40|8@1- (1,25) [-103|152] "Celsius"  HVESP01
 SG_ HVESP01_modTemperature_35_4 m6: 48|8@1- (1,25) [-103|152] "Celsius"  HVESP01
 SG_ HVESP01_modTemperature_36_4 m7: 16|8@1- (1,25) [-103|152] "Celsius"  HVESP01
 SG_ HVESP01_modTemperature_37_4 m7: 24|8@1- (1,25) [-103|152] "Celsius"  HVESP01
 SG_ HVESP01_modTemperature_38_4 m7: 32|8@1- (1,25) [-103|152] "Celsius"  HVESP01
 SG_ HVESP01_modTemperature_39_4 m7: 40|8@1- (1,25) [-103|152] "Celsius"  HVESP01
 SG_ HVESP01_modTemperature_40_4 m7: 48|8@1- (1,25) [-103|152] "Celsius"  HVESP01
 SG_ HVESP01_modTemperature_41_4 m8: 16|8@1- (1,25) [-103|152] "Celsius"  HVESP01
 SG_ HVESP01_modTemperature_42_4 m8: 24|8@1- (1,25) [-103|152] "Celsius"  HVESP01
 SG_ HVESP01_modTemperature_43_4 m8: 32|8@1- (1,25) [-103|152] "Celsius"  HVESP01
 SG_ HVESP01_modTemperature_44_4 m8: 40|8@1- (1,25) [-103|152] "Celsius"  HVESP01
 SG_ HVESP01_modTemperature_45_4 m8: 48|8@1- (1,25) [-103|152] "Celsius"  HVESP01
 SG_ HVESP01_modTemperature_46_4 m9: 16|8@1- (1,25) [-103|152] "Celsius"  HVESP01
 SG_ HVESP01_modTemperature_47_4 m9: 24|8@1- (1,25) [-103|152] "Celsius"  HVESP01
 SG_ HVESP01_modTemperature_48_4 m9: 32|8@1- (1,25) [-103|152] "Celsius"  HVESP01
 SG_ HVESP01_modTemperature_49_4 m9: 40|8@1- (1,25) [-103|152] "Celsius"  HVESP01
 SG_ HVESP01_modTemperature_50_4 m9: 48|8@1- (1,25) [-103|152] "Celsius"  HVESP01
 SG_ multiplexormt_4 M: 0|9@1+ (1,0) [0|255] ""  HVESP01

BO_ 2499742057 HVESP01_modTemperature_5: 8 HVESP01
 SG_ HVESP01_modTemperature_01_5 m0: 16|8@1- (1,25) [-103|152] "Celsius"  HVESP01
 SG_ HVESP01_modTemperature_02_5 m0: 24|8@1- (1,25) [-103|152] "Celsius"  HVESP01
 SG_ HVESP01_modTemperature_03_5 m0: 32|8@1- (1,25) [-103|152] "Celsius"  HVESP01
 SG_ HVESP01_modTemperature_04_5 m0: 40|8@1- (1,25) [-103|152] "Celsius"  HVESP01
 SG_ HVESP01_modTemperature_05_5 m0: 48|8@1- (1,25) [-103|152] "Celsius"  HVESP01
 SG_ HVESP01_modTemperature_06_5 m1: 16|8@1- (1,25) [-103|152] "Celsius"  HVESP01
 SG_ HVESP01_modTemperature_07_5 m1: 24|8@1- (1,25) [-103|152] "Celsius"  HVESP01
 SG_ HVESP01_modTemperature_08_5 m1: 32|8@1- (1,25) [-103|152] "Celsius"  HVESP01
 SG_ HVESP01_modTemperature_09_5 m1: 40|8@1- (1,25) [-103|152] "Celsius"  HVESP01
 SG_ HVESP01_modTemperature_10_5 m1: 48|8@1- (1,25) [-103|152] "Celsius"  HVESP01
 SG_ HVESP01_modTemperature_11_5 m2: 16|8@1- (1,25) [-103|152] "Celsius"  HVESP01
 SG_ HVESP01_modTemperature_12_5 m2: 24|8@1- (1,25) [-103|152] "Celsius"  HVESP01
 SG_ HVESP01_modTemperature_13_5 m2: 32|8@1- (1,25) [-103|152] "Celsius"  HVESP01
 SG_ HVESP01_modTemperature_14_5 m2: 40|8@1- (1,25) [-103|152] "Celsius"  HVESP01
 SG_ HVESP01_modTemperature_15_5 m2: 48|8@1- (1,25) [-103|152] "Celsius"  HVESP01
 SG_ HVESP01_modTemperature_16_5 m3: 16|8@1- (1,25) [-103|152] "Celsius"  HVESP01
 SG_ HVESP01_modTemperature_17_5 m3: 24|8@1- (1,25) [-103|152] "Celsius"  HVESP01
 SG_ HVESP01_modTemperature_18_5 m3: 32|8@1- (1,25) [-103|152] "Celsius"  HVESP01
 SG_ HVESP01_modTemperature_19_5 m3: 40|8@1- (1,25) [-103|152] "Celsius"  HVESP01
 SG_ HVESP01_modTemperature_20_5 m3: 48|8@1- (1,25) [-103|152] "Celsius"  HVESP01
 SG_ HVESP01_modTemperature_21_5 m4: 16|8@1- (1,25) [-103|152] "Celsius"  HVESP01
 SG_ HVESP01_modTemperature_22_5 m4: 24|8@1- (1,25) [-103|152] "Celsius"  HVESP01
 SG_ HVESP01_modTemperature_23_5 m4: 32|8@1- (1,25) [-103|152] "Celsius"  HVESP01
 SG_ HVESP01_modTemperature_24_5 m4: 40|8@1- (1,25) [-103|152] "Celsius"  HVESP01
 SG_ HVESP01_modTemperature_25_5 m4: 48|8@1- (1,25) [-103|152] "Celsius"  HVESP01
 SG_ HVESP01_modTemperature_26_5 m5: 16|8@1- (1,25) [-103|152] "Celsius"  HVESP01
 SG_ HVESP01_modTemperature_27_5 m5: 24|8@1- (1,25) [-103|152] "Celsius"  HVESP01
 SG_ HVESP01_modTemperature_28_5 m5: 32|8@1- (1,25) [-103|152] "Celsius"  HVESP01
 SG_ HVESP01_modTemperature_29_5 m5: 40|8@1- (1,25) [-103|152] "Celsius"  HVESP01
 SG_ HVESP01_modTemperature_30_5 m5: 48|8@1- (1,25) [-103|152] "Celsius"  HVESP01
 SG_ HVESP01_modTemperature_31_5 m6: 16|8@1- (1,25) [-103|152] "Celsius"  HVESP01
 SG_ HVESP01_modTemperature_32_5 m6: 24|8@1- (1,25) [-103|152] "Celsius"  HVESP01
 SG_ HVESP01_modTemperature_33_5 m6: 32|8@1- (1,25) [-103|152] "Celsius"  HVESP01
 SG_ HVESP01_modTemperature_34_5 m6: 40|8@1- (1,25) [-103|152] "Celsius"  HVESP01
 SG_ HVESP01_modTemperature_35_5 m6: 48|8@1- (1,25) [-103|152] "Celsius"  HVESP01
 SG_ HVESP01_modTemperature_36_5 m7: 16|8@1- (1,25) [-103|152] "Celsius"  HVESP01
 SG_ HVESP01_modTemperature_37_5 m7: 24|8@1- (1,25) [-103|152] "Celsius"  HVESP01
 SG_ HVESP01_modTemperature_38_5 m7: 32|8@1- (1,25) [-103|152] "Celsius"  HVESP01
 SG_ HVESP01_modTemperature_39_5 m7: 40|8@1- (1,25) [-103|152] "Celsius"  HVESP01
 SG_ HVESP01_modTemperature_40_5 m7: 48|8@1- (1,25) [-103|152] "Celsius"  HVESP01
 SG_ HVESP01_modTemperature_41_5 m8: 16|8@1- (1,25) [-103|152] "Celsius"  HVESP01
 SG_ HVESP01_modTemperature_42_5 m8: 24|8@1- (1,25) [-103|152] "Celsius"  HVESP01
 SG_ HVESP01_modTemperature_43_5 m8: 32|8@1- (1,25) [-103|152] "Celsius"  HVESP01
 SG_ HVESP01_modTemperature_44_5 m8: 40|8@1- (1,25) [-103|152] "Celsius"  HVESP01
 SG_ HVESP01_modTemperature_45_5 m8: 48|8@1- (1,25) [-103|152] "Celsius"  HVESP01
 SG_ HVESP01_modTemperature_46_5 m9: 16|8@1- (1,25) [-103|152] "Celsius"  HVESP01
 SG_ HVESP01_modTemperature_47_5 m9: 24|8@1- (1,25) [-103|152] "Celsius"  HVESP01
 SG_ HVESP01_modTemperature_48_5 m9: 32|8@1- (1,25) [-103|152] "Celsius"  HVESP01
 SG_ HVESP01_modTemperature_49_5 m9: 40|8@1- (1,25) [-103|152] "Celsius"  HVESP01
 SG_ HVESP01_modTemperature_50_5 m9: 48|8@1- (1,25) [-103|152] "Celsius"  HVESP01
 SG_ multiplexormt_5 M: 0|9@1+ (1,0) [0|255] ""  HVESP01

BO_ 2499742058 HVESP01_modTemperature_6: 8 HVESP01
 SG_ HVESP01_modTemperature_01_6 m0: 16|8@1- (1,25) [-103|152] "Celsius"  HVESP01
 SG_ HVESP01_modTemperature_02_6 m0: 24|8@1- (1,25) [-103|152] "Celsius"  HVESP01
 SG_ HVESP01_modTemperature_03_6 m0: 32|8@1- (1,25) [-103|152] "Celsius"  HVESP01
 SG_ HVESP01_modTemperature_04_6 m0: 40|8@1- (1,25) [-103|152] "Celsius"  HVESP01
 SG_ HVESP01_modTemperature_05_6 m0: 48|8@1- (1,25) [-103|152] "Celsius"  HVESP01
 SG_ HVESP01_modTemperature_06_6 m1: 16|8@1- (1,25) [-103|152] "Celsius"  HVESP01
 SG_ HVESP01_modTemperature_07_6 m1: 24|8@1- (1,25) [-103|152] "Celsius"  HVESP01
 SG_ HVESP01_modTemperature_08_6 m1: 32|8@1- (1,25) [-103|152] "Celsius"  HVESP01
 SG_ HVESP01_modTemperature_09_6 m1: 40|8@1- (1,25) [-103|152] "Celsius"  HVESP01
 SG_ HVESP01_modTemperature_10_6 m1: 48|8@1- (1,25) [-103|152] "Celsius"  HVESP01
 SG_ HVESP01_modTemperature_11_6 m2: 16|8@1- (1,25) [-103|152] "Celsius"  HVESP01
 SG_ HVESP01_modTemperature_12_6 m2: 24|8@1- (1,25) [-103|152] "Celsius"  HVESP01
 SG_ HVESP01_modTemperature_13_6 m2: 32|8@1- (1,25) [-103|152] "Celsius"  HVESP01
 SG_ HVESP01_modTemperature_14_6 m2: 40|8@1- (1,25) [-103|152] "Celsius"  HVESP01
 SG_ HVESP01_modTemperature_15_6 m2: 48|8@1- (1,25) [-103|152] "Celsius"  HVESP01
 SG_ HVESP01_modTemperature_16_6 m3: 16|8@1- (1,25) [-103|152] "Celsius"  HVESP01
 SG_ HVESP01_modTemperature_17_6 m3: 24|8@1- (1,25) [-103|152] "Celsius"  HVESP01
 SG_ HVESP01_modTemperature_18_6 m3: 32|8@1- (1,25) [-103|152] "Celsius"  HVESP01
 SG_ HVESP01_modTemperature_19_6 m3: 40|8@1- (1,25) [-103|152] "Celsius"  HVESP01
 SG_ HVESP01_modTemperature_20_6 m3: 48|8@1- (1,25) [-103|152] "Celsius"  HVESP01
 SG_ HVESP01_modTemperature_21_6 m4: 16|8@1- (1,25) [-103|152] "Celsius"  HVESP01
 SG_ HVESP01_modTemperature_22_6 m4: 24|8@1- (1,25) [-103|152] "Celsius"  HVESP01
 SG_ HVESP01_modTemperature_23_6 m4: 32|8@1- (1,25) [-103|152] "Celsius"  HVESP01
 SG_ HVESP01_modTemperature_24_6 m4: 40|8@1- (1,25) [-103|152] "Celsius"  HVESP01
 SG_ HVESP01_modTemperature_25_6 m4: 48|8@1- (1,25) [-103|152] "Celsius"  HVESP01
 SG_ HVESP01_modTemperature_26_6 m5: 16|8@1- (1,25) [-103|152] "Celsius"  HVESP01
 SG_ HVESP01_modTemperature_27_6 m5: 24|8@1- (1,25) [-103|152] "Celsius"  HVESP01
 SG_ HVESP01_modTemperature_28_6 m5: 32|8@1- (1,25) [-103|152] "Celsius"  HVESP01
 SG_ HVESP01_modTemperature_29_6 m5: 40|8@1- (1,25) [-103|152] "Celsius"  HVESP01
 SG_ HVESP01_modTemperature_30_6 m5: 48|8@1- (1,25) [-103|152] "Celsius"  HVESP01
 SG_ HVESP01_modTemperature_31_6 m6: 16|8@1- (1,25) [-103|152] "Celsius"  HVESP01
 SG_ HVESP01_modTemperature_32_6 m6: 24|8@1- (1,25) [-103|152] "Celsius"  HVESP01
 SG_ HVESP01_modTemperature_33_6 m6: 32|8@1- (1,25) [-103|152] "Celsius"  HVESP01
 SG_ HVESP01_modTemperature_34_6 m6: 40|8@1- (1,25) [-103|152] "Celsius"  HVESP01
 SG_ HVESP01_modTemperature_35_6 m6: 48|8@1- (1,25) [-103|152] "Celsius"  HVESP01
 SG_ HVESP01_modTemperature_36_6 m7: 16|8@1- (1,25) [-103|152] "Celsius"  HVESP01
 SG_ HVESP01_modTemperature_37_6 m7: 24|8@1- (1,25) [-103|152] "Celsius"  HVESP01
 SG_ HVESP01_modTemperature_38_6 m7: 32|8@1- (1,25) [-103|152] "Celsius"  HVESP01
 SG_ HVESP01_modTemperature_39_6 m7: 40|8@1- (1,25) [-103|152] "Celsius"  HVESP01
 SG_ HVESP01_modTemperature_40_6 m7: 48|8@1- (1,25) [-103|152] "Celsius"  HVESP01
 SG_ HVESP01_modTemperature_41_6 m8: 16|8@1- (1,25) [-103|152] "Celsius"  HVESP01
 SG_ HVESP01_modTemperature_42_6 m8: 24|8@1- (1,25) [-103|152] "Celsius"  HVESP01
 SG_ HVESP01_modTemperature_43_6 m8: 32|8@1- (1,25) [-103|152] "Celsius"  HVESP01
 SG_ HVESP01_modTemperature_44_6 m8: 40|8@1- (1,25) [-103|152] "Celsius"  HVESP01
 SG_ HVESP01_modTemperature_45_6 m8: 48|8@1- (1,25) [-103|152] "Celsius"  HVESP01
 SG_ HVESP01_modTemperature_46_6 m9: 16|8@1- (1,25) [-103|152] "Celsius"  HVESP01
 SG_ HVESP01_modTemperature_47_6 m9: 24|8@1- (1,25) [-103|152] "Celsius"  HVESP01
 SG_ HVESP01_modTemperature_48_6 m9: 32|8@1- (1,25) [-103|152] "Celsius"  HVESP01
 SG_ HVESP01_modTemperature_49_6 m9: 40|8@1- (1,25) [-103|152] "Celsius"  HVESP01
 SG_ HVESP01_modTemperature_50_6 m9: 48|8@1- (1,25) [-103|152] "Celsius"  HVESP01
 SG_ multiplexormt_6 M: 0|9@1+ (1,0) [0|255] ""  HVESP01

BO_ 2499742059 HVESP01_modTemperature_7: 8 HVESP01
 SG_ HVESP01_modTemperature_01_7 m0: 16|8@1- (1,25) [-103|152] "Celsius"  HVESP01
 SG_ HVESP01_modTemperature_02_7 m0: 24|8@1- (1,25) [-103|152] "Celsius"  HVESP01
 SG_ HVESP01_modTemperature_03_7 m0: 32|8@1- (1,25) [-103|152] "Celsius"  HVESP01
 SG_ HVESP01_modTemperature_04_7 m0: 40|8@1- (1,25) [-103|152] "Celsius"  HVESP01
 SG_ HVESP01_modTemperature_05_7 m0: 48|8@1- (1,25) [-103|152] "Celsius"  HVESP01
 SG_ HVESP01_modTemperature_06_7 m1: 16|8@1- (1,25) [-103|152] "Celsius"  HVESP01
 SG_ HVESP01_modTemperature_07_7 m1: 24|8@1- (1,25) [-103|152] "Celsius"  HVESP01
 SG_ HVESP01_modTemperature_08_7 m1: 32|8@1- (1,25) [-103|152] "Celsius"  HVESP01
 SG_ HVESP01_modTemperature_09_7 m1: 40|8@1- (1,25) [-103|152] "Celsius"  HVESP01
 SG_ HVESP01_modTemperature_10_7 m1: 48|8@1- (1,25) [-103|152] "Celsius"  HVESP01
 SG_ HVESP01_modTemperature_11_7 m2: 16|8@1- (1,25) [-103|152] "Celsius"  HVESP01
 SG_ HVESP01_modTemperature_12_7 m2: 24|8@1- (1,25) [-103|152] "Celsius"  HVESP01
 SG_ HVESP01_modTemperature_13_7 m2: 32|8@1- (1,25) [-103|152] "Celsius"  HVESP01
 SG_ HVESP01_modTemperature_14_7 m2: 40|8@1- (1,25) [-103|152] "Celsius"  HVESP01
 SG_ HVESP01_modTemperature_15_7 m2: 48|8@1- (1,25) [-103|152] "Celsius"  HVESP01
 SG_ HVESP01_modTemperature_16_7 m3: 16|8@1- (1,25) [-103|152] "Celsius"  HVESP01
 SG_ HVESP01_modTemperature_17_7 m3: 24|8@1- (1,25) [-103|152] "Celsius"  HVESP01
 SG_ HVESP01_modTemperature_18_7 m3: 32|8@1- (1,25) [-103|152] "Celsius"  HVESP01
 SG_ HVESP01_modTemperature_19_7 m3: 40|8@1- (1,25) [-103|152] "Celsius"  HVESP01
 SG_ HVESP01_modTemperature_20_7 m3: 48|8@1- (1,25) [-103|152] "Celsius"  HVESP01
 SG_ HVESP01_modTemperature_21_7 m4: 16|8@1- (1,25) [-103|152] "Celsius"  HVESP01
 SG_ HVESP01_modTemperature_22_7 m4: 24|8@1- (1,25) [-103|152] "Celsius"  HVESP01
 SG_ HVESP01_modTemperature_23_7 m4: 32|8@1- (1,25) [-103|152] "Celsius"  HVESP01
 SG_ HVESP01_modTemperature_24_7 m4: 40|8@1- (1,25) [-103|152] "Celsius"  HVESP01
 SG_ HVESP01_modTemperature_25_7 m4: 48|8@1- (1,25) [-103|152] "Celsius"  HVESP01
 SG_ HVESP01_modTemperature_26_7 m5: 16|8@1- (1,25) [-103|152] "Celsius"  HVESP01
 SG_ HVESP01_modTemperature_27_7 m5: 24|8@1- (1,25) [-103|152] "Celsius"  HVESP01
 SG_ HVESP01_modTemperature_28_7 m5: 32|8@1- (1,25) [-103|152] "Celsius"  HVESP01
 SG_ HVESP01_modTemperature_29_7 m5: 40|8@1- (1,25) [-103|152] "Celsius"  HVESP01
 SG_ HVESP01_modTemperature_30_7 m5: 48|8@1- (1,25) [-103|152] "Celsius"  HVESP01
 SG_ HVESP01_modTemperature_31_7 m6: 16|8@1- (1,25) [-103|152] "Celsius"  HVESP01
 SG_ HVESP01_modTemperature_32_7 m6: 24|8@1- (1,25) [-103|152] "Celsius"  HVESP01
 SG_ HVESP01_modTemperature_33_7 m6: 32|8@1- (1,25) [-103|152] "Celsius"  HVESP01
 SG_ HVESP01_modTemperature_34_7 m6: 40|8@1- (1,25) [-103|152] "Celsius"  HVESP01
 SG_ HVESP01_modTemperature_35_7 m6: 48|8@1- (1,25) [-103|152] "Celsius"  HVESP01
 SG_ HVESP01_modTemperature_36_7 m7: 16|8@1- (1,25) [-103|152] "Celsius"  HVESP01
 SG_ HVESP01_modTemperature_37_7 m7: 24|8@1- (1,25) [-103|152] "Celsius"  HVESP01
 SG_ HVESP01_modTemperature_38_7 m7: 32|8@1- (1,25) [-103|152] "Celsius"  HVESP01
 SG_ HVESP01_modTemperature_39_7 m7: 40|8@1- (1,25) [-103|152] "Celsius"  HVESP01
 SG_ HVESP01_modTemperature_40_7 m7: 48|8@1- (1,25) [-103|152] "Celsius"  HVESP01
 SG_ HVESP01_modTemperature_41_7 m8: 16|8@1- (1,25) [-103|152] "Celsius"  HVESP01
 SG_ HVESP01_modTemperature_42_7 m8: 24|8@1- (1,25) [-103|152] "Celsius"  HVESP01
 SG_ HVESP01_modTemperature_43_7 m8: 32|8@1- (1,25) [-103|152] "Celsius"  HVESP01
 SG_ HVESP01_modTemperature_44_7 m8: 40|8@1- (1,25) [-103|152] "Celsius"  HVESP01
 SG_ HVESP01_modTemperature_45_7 m8: 48|8@1- (1,25) [-103|152] "Celsius"  HVESP01
 SG_ HVESP01_modTemperature_46_7 m9: 16|8@1- (1,25) [-103|152] "Celsius"  HVESP01
 SG_ HVESP01_modTemperature_47_7 m9: 24|8@1- (1,25) [-103|152] "Celsius"  HVESP01
 SG_ HVESP01_modTemperature_48_7 m9: 32|8@1- (1,25) [-103|152] "Celsius"  HVESP01
 SG_ HVESP01_modTemperature_49_7 m9: 40|8@1- (1,25) [-103|152] "Celsius"  HVESP01
 SG_ HVESP01_modTemperature_50_7 m9: 48|8@1- (1,25) [-103|152] "Celsius"  HVESP01
 SG_ multiplexormt_7 M: 0|9@1+ (1,0) [0|255] ""  HVESP01

BO_ 2499742060 HVESP01_modTemperature_8: 8 HVESP01
 SG_ HVESP01_modTemperature_01_8 m0: 16|8@1- (1,25) [-103|152] "Celsius"  HVESP01
 SG_ HVESP01_modTemperature_02_8 m0: 24|8@1- (1,25) [-103|152] "Celsius"  HVESP01
 SG_ HVESP01_modTemperature_03_8 m0: 32|8@1- (1,25) [-103|152] "Celsius"  HVESP01
 SG_ HVESP01_modTemperature_04_8 m0: 40|8@1- (1,25) [-103|152] "Celsius"  HVESP01
 SG_ HVESP01_modTemperature_05_8 m0: 48|8@1- (1,25) [-103|152] "Celsius"  HVESP01
 SG_ HVESP01_modTemperature_06_8 m1: 16|8@1- (1,25) [-103|152] "Celsius"  HVESP01
 SG_ HVESP01_modTemperature_07_8 m1: 24|8@1- (1,25) [-103|152] "Celsius"  HVESP01
 SG_ HVESP01_modTemperature_08_8 m1: 32|8@1- (1,25) [-103|152] "Celsius"  HVESP01
 SG_ HVESP01_modTemperature_09_8 m1: 40|8@1- (1,25) [-103|152] "Celsius"  HVESP01
 SG_ HVESP01_modTemperature_10_8 m1: 48|8@1- (1,25) [-103|152] "Celsius"  HVESP01
 SG_ HVESP01_modTemperature_11_8 m2: 16|8@1- (1,25) [-103|152] "Celsius"  HVESP01
 SG_ HVESP01_modTemperature_12_8 m2: 24|8@1- (1,25) [-103|152] "Celsius"  HVESP01
 SG_ HVESP01_modTemperature_13_8 m2: 32|8@1- (1,25) [-103|152] "Celsius"  HVESP01
 SG_ HVESP01_modTemperature_14_8 m2: 40|8@1- (1,25) [-103|152] "Celsius"  HVESP01
 SG_ HVESP01_modTemperature_15_8 m2: 48|8@1- (1,25) [-103|152] "Celsius"  HVESP01
 SG_ HVESP01_modTemperature_16_8 m3: 16|8@1- (1,25) [-103|152] "Celsius"  HVESP01
 SG_ HVESP01_modTemperature_17_8 m3: 24|8@1- (1,25) [-103|152] "Celsius"  HVESP01
 SG_ HVESP01_modTemperature_18_8 m3: 32|8@1- (1,25) [-103|152] "Celsius"  HVESP01
 SG_ HVESP01_modTemperature_19_8 m3: 40|8@1- (1,25) [-103|152] "Celsius"  HVESP01
 SG_ HVESP01_modTemperature_20_8 m3: 48|8@1- (1,25) [-103|152] "Celsius"  HVESP01
 SG_ HVESP01_modTemperature_21_8 m4: 16|8@1- (1,25) [-103|152] "Celsius"  HVESP01
 SG_ HVESP01_modTemperature_22_8 m4: 24|8@1- (1,25) [-103|152] "Celsius"  HVESP01
 SG_ HVESP01_modTemperature_23_8 m4: 32|8@1- (1,25) [-103|152] "Celsius"  HVESP01
 SG_ HVESP01_modTemperature_24_8 m4: 40|8@1- (1,25) [-103|152] "Celsius"  HVESP01
 SG_ HVESP01_modTemperature_25_8 m4: 48|8@1- (1,25) [-103|152] "Celsius"  HVESP01
 SG_ HVESP01_modTemperature_26_8 m5: 16|8@1- (1,25) [-103|152] "Celsius"  HVESP01
 SG_ HVESP01_modTemperature_27_8 m5: 24|8@1- (1,25) [-103|152] "Celsius"  HVESP01
 SG_ HVESP01_modTemperature_28_8 m5: 32|8@1- (1,25) [-103|152] "Celsius"  HVESP01
 SG_ HVESP01_modTemperature_29_8 m5: 40|8@1- (1,25) [-103|152] "Celsius"  HVESP01
 SG_ HVESP01_modTemperature_30_8 m5: 48|8@1- (1,25) [-103|152] "Celsius"  HVESP01
 SG_ HVESP01_modTemperature_31_8 m6: 16|8@1- (1,25) [-103|152] "Celsius"  HVESP01
 SG_ HVESP01_modTemperature_32_8 m6: 24|8@1- (1,25) [-103|152] "Celsius"  HVESP01
 SG_ HVESP01_modTemperature_33_8 m6: 32|8@1- (1,25) [-103|152] "Celsius"  HVESP01
 SG_ HVESP01_modTemperature_34_8 m6: 40|8@1- (1,25) [-103|152] "Celsius"  HVESP01
 SG_ HVESP01_modTemperature_35_8 m6: 48|8@1- (1,25) [-103|152] "Celsius"  HVESP01
 SG_ HVESP01_modTemperature_36_8 m7: 16|8@1- (1,25) [-103|152] "Celsius"  HVESP01
 SG_ HVESP01_modTemperature_37_8 m7: 24|8@1- (1,25) [-103|152] "Celsius"  HVESP01
 SG_ HVESP01_modTemperature_38_8 m7: 32|8@1- (1,25) [-103|152] "Celsius"  HVESP01
 SG_ HVESP01_modTemperature_39_8 m7: 40|8@1- (1,25) [-103|152] "Celsius"  HVESP01
 SG_ HVESP01_modTemperature_40_8 m7: 48|8@1- (1,25) [-103|152] "Celsius"  HVESP01
 SG_ HVESP01_modTemperature_41_8 m8: 16|8@1- (1,25) [-103|152] "Celsius"  HVESP01
 SG_ HVESP01_modTemperature_42_8 m8: 24|8@1- (1,25) [-103|152] "Celsius"  HVESP01
 SG_ HVESP01_modTemperature_43_8 m8: 32|8@1- (1,25) [-103|152] "Celsius"  HVESP01
 SG_ HVESP01_modTemperature_44_8 m8: 40|8@1- (1,25) [-103|152] "Celsius"  HVESP01
 SG_ HVESP01_modTemperature_45_8 m8: 48|8@1- (1,25) [-103|152] "Celsius"  HVESP01
 SG_ HVESP01_modTemperature_46_8 m9: 16|8@1- (1,25) [-103|152] "Celsius"  HVESP01
 SG_ HVESP01_modTemperature_47_8 m9: 24|8@1- (1,25) [-103|152] "Celsius"  HVESP01
 SG_ HVESP01_modTemperature_48_8 m9: 32|8@1- (1,25) [-103|152] "Celsius"  HVESP01
 SG_ HVESP01_modTemperature_49_8 m9: 40|8@1- (1,25) [-103|152] "Celsius"  HVESP01
 SG_ HVESP01_modTemperature_50_8 m9: 48|8@1- (1,25) [-103|152] "Celsius"  HVESP01
 SG_ multiplexormt_8 M: 0|9@1+ (1,0) [0|255] ""  HVESP01

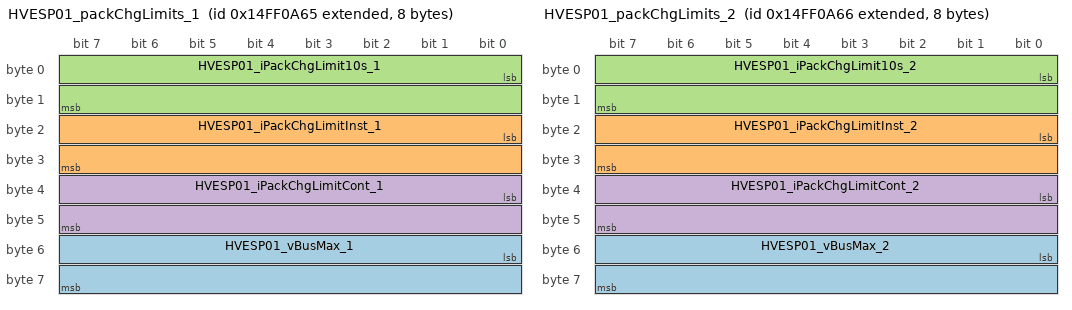
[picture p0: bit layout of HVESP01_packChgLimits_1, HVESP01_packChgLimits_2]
BO_ 2499742309 HVESP01_packChgLimits_1: 8 HVESP01
 SG_ HVESP01_vBusMax_1 : 48|16@1+ (0.02,0) [0|1310.7] "V"  HVESP01
 SG_ HVESP01_iPackChgLimitInst_1 : 16|16@1+ (0.025,0) [0|1638.375] "A"  HVESP01
 SG_ HVESP01_iPackChgLimit10s_1 : 0|16@1+ (0.025,0) [0|1638.375] "A"  HVESP01
 SG_ HVESP01_iPackChgLimitCont_1 : 32|16@1+ (0.01,0) [0|655.35] "A"  HVESP01

BO_ 2499742310 HVESP01_packChgLimits_2: 8 HVESP01
 SG_ HVESP01_vBusMax_2 : 48|16@1+ (0.02,0) [0|1310.7] "V"  HVESP01
 SG_ HVESP01_iPackChgLimitInst_2 : 16|16@1+ (0.025,0) [0|1638.375] "A"  HVESP01
 SG_ HVESP01_iPackChgLimit10s_2 : 0|16@1+ (0.025,0) [0|1638.375] "A"  HVESP01
 SG_ HVESP01_iPackChgLimitCont_2 : 32|16@1+ (0.01,0) [0|655.35] "A"  HVESP01

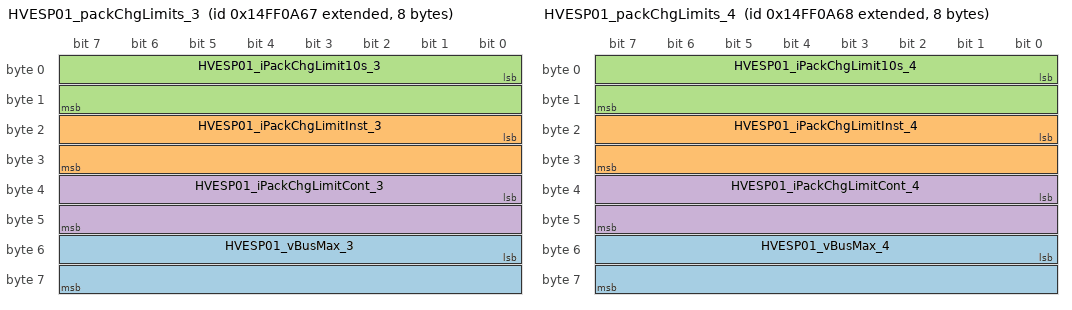
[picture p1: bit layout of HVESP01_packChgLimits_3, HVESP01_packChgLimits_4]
BO_ 2499742311 HVESP01_packChgLimits_3: 8 HVESP01
 SG_ HVESP01_vBusMax_3 : 48|16@1+ (0.02,0) [0|1310.7] "V"  HVESP01
 SG_ HVESP01_iPackChgLimitInst_3 : 16|16@1+ (0.025,0) [0|1638.375] "A"  HVESP01
 SG_ HVESP01_iPackChgLimit10s_3 : 0|16@1+ (0.025,0) [0|1638.375] "A"  HVESP01
 SG_ HVESP01_iPackChgLimitCont_3 : 32|16@1+ (0.01,0) [0|655.35] "A"  HVESP01

BO_ 2499742312 HVESP01_packChgLimits_4: 8 HVESP01
 SG_ HVESP01_vBusMax_4 : 48|16@1+ (0.02,0) [0|1310.7] "V"  HVESP01
 SG_ HVESP01_iPackChgLimitInst_4 : 16|16@1+ (0.025,0) [0|1638.375] "A"  HVESP01
 SG_ HVESP01_iPackChgLimit10s_4 : 0|16@1+ (0.025,0) [0|1638.375] "A"  HVESP01
 SG_ HVESP01_iPackChgLimitCont_4 : 32|16@1+ (0.01,0) [0|655.35] "A"  HVESP01

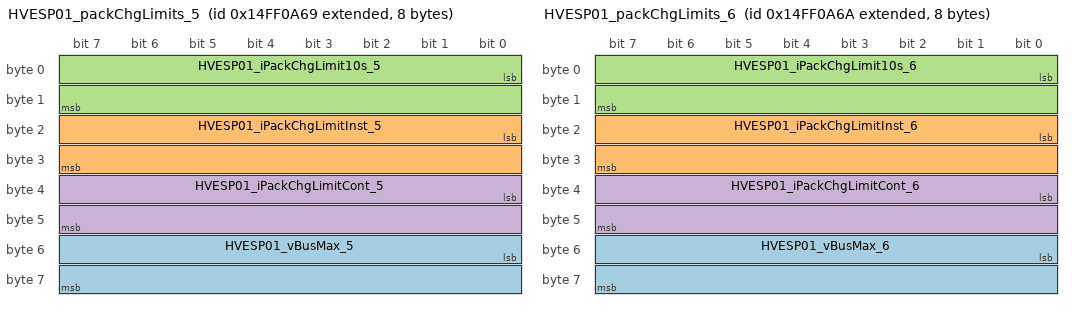
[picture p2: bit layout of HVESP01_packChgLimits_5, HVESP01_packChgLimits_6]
BO_ 2499742313 HVESP01_packChgLimits_5: 8 HVESP01
 SG_ HVESP01_vBusMax_5 : 48|16@1+ (0.02,0) [0|1310.7] "V"  HVESP01
 SG_ HVESP01_iPackChgLimitInst_5 : 16|16@1+ (0.025,0) [0|1638.375] "A"  HVESP01
 SG_ HVESP01_iPackChgLimit10s_5 : 0|16@1+ (0.025,0) [0|1638.375] "A"  HVESP01
 SG_ HVESP01_iPackChgLimitCont_5 : 32|16@1+ (0.01,0) [0|655.35] "A"  HVESP01

BO_ 2499742314 HVESP01_packChgLimits_6: 8 HVESP01
 SG_ HVESP01_vBusMax_6 : 48|16@1+ (0.02,0) [0|1310.7] "V"  HVESP01
 SG_ HVESP01_iPackChgLimitInst_6 : 16|16@1+ (0.025,0) [0|1638.375] "A"  HVESP01
 SG_ HVESP01_iPackChgLimit10s_6 : 0|16@1+ (0.025,0) [0|1638.375] "A"  HVESP01
 SG_ HVESP01_iPackChgLimitCont_6 : 32|16@1+ (0.01,0) [0|655.35] "A"  HVESP01

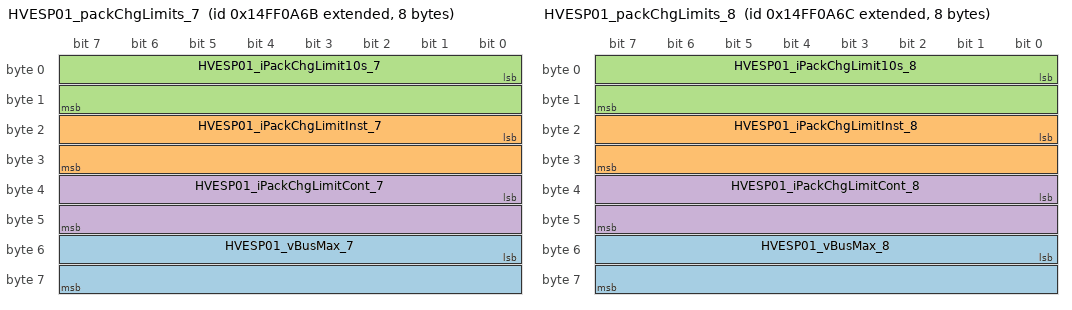
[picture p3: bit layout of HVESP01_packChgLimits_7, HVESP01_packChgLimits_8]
BO_ 2499742315 HVESP01_packChgLimits_7: 8 HVESP01
 SG_ HVESP01_vBusMax_7 : 48|16@1+ (0.02,0) [0|1310.7] "V"  HVESP01
 SG_ HVESP01_iPackChgLimitInst_7 : 16|16@1+ (0.025,0) [0|1638.375] "A"  HVESP01
 SG_ HVESP01_iPackChgLimit10s_7 : 0|16@1+ (0.025,0) [0|1638.375] "A"  HVESP01
 SG_ HVESP01_iPackChgLimitCont_7 : 32|16@1+ (0.01,0) [0|655.35] "A"  HVESP01

BO_ 2499742316 HVESP01_packChgLimits_8: 8 HVESP01
 SG_ HVESP01_vBusMax_8 : 48|16@1+ (0.02,0) [0|1310.7] "V"  HVESP01
 SG_ HVESP01_iPackChgLimitInst_8 : 16|16@1+ (0.025,0) [0|1638.375] "A"  HVESP01
 SG_ HVESP01_iPackChgLimit10s_8 : 0|16@1+ (0.025,0) [0|1638.375] "A"  HVESP01
 SG_ HVESP01_iPackChgLimitCont_8 : 32|16@1+ (0.01,0) [0|655.35] "A"  HVESP01

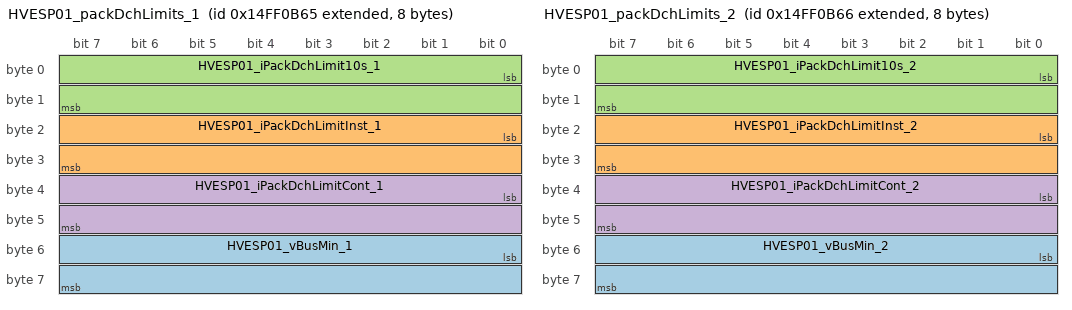
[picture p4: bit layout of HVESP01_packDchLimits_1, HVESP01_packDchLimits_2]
BO_ 2499742565 HVESP01_packDchLimits_1: 8 HVESP01
 SG_ HVESP01_vBusMin_1 : 48|16@1+ (0.02,0) [0|1310.7] "V"  HVESP01
 SG_ HVESP01_iPackDchLimitInst_1 : 16|16@1- (0.1,0) [-3276.8|0] "A"  HVESP01
 SG_ HVESP01_iPackDchLimit10s_1 : 0|16@1- (-0.1,0) [-3276.7|0] "A"  HVESP01
 SG_ HVESP01_iPackDchLimitCont_1 : 32|16@1- (0.02,0) [-655.36|0] "A"  HVESP01

BO_ 2499742566 HVESP01_packDchLimits_2: 8 HVESP01
 SG_ HVESP01_vBusMin_2 : 48|16@1+ (0.02,0) [0|1310.7] "V"  HVESP01
 SG_ HVESP01_iPackDchLimitInst_2 : 16|16@1- (0.1,0) [-3276.8|0] "A"  HVESP01
 SG_ HVESP01_iPackDchLimit10s_2 : 0|16@1- (-0.1,0) [-3276.7|0] "A"  HVESP01
 SG_ HVESP01_iPackDchLimitCont_2 : 32|16@1- (0.02,0) [-655.36|0] "A"  HVESP01

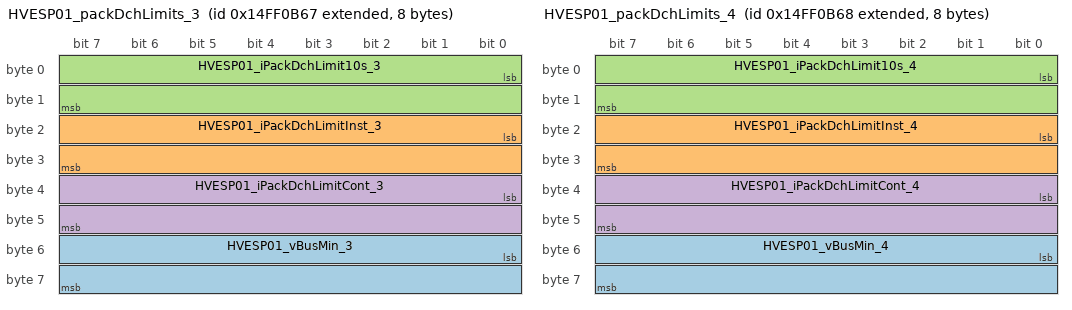
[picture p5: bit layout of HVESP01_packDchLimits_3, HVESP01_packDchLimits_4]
BO_ 2499742567 HVESP01_packDchLimits_3: 8 HVESP01
 SG_ HVESP01_vBusMin_3 : 48|16@1+ (0.02,0) [0|1310.7] "V"  HVESP01
 SG_ HVESP01_iPackDchLimitInst_3 : 16|16@1- (0.1,0) [-3276.8|0] "A"  HVESP01
 SG_ HVESP01_iPackDchLimit10s_3 : 0|16@1- (-0.1,0) [-3276.7|0] "A"  HVESP01
 SG_ HVESP01_iPackDchLimitCont_3 : 32|16@1- (0.02,0) [-655.36|0] "A"  HVESP01

BO_ 2499742568 HVESP01_packDchLimits_4: 8 HVESP01
 SG_ HVESP01_vBusMin_4 : 48|16@1+ (0.02,0) [0|1310.7] "V"  HVESP01
 SG_ HVESP01_iPackDchLimitInst_4 : 16|16@1- (0.1,0) [-3276.8|0] "A"  HVESP01
 SG_ HVESP01_iPackDchLimit10s_4 : 0|16@1- (-0.1,0) [-3276.7|0] "A"  HVESP01
 SG_ HVESP01_iPackDchLimitCont_4 : 32|16@1- (0.02,0) [-655.36|0] "A"  HVESP01

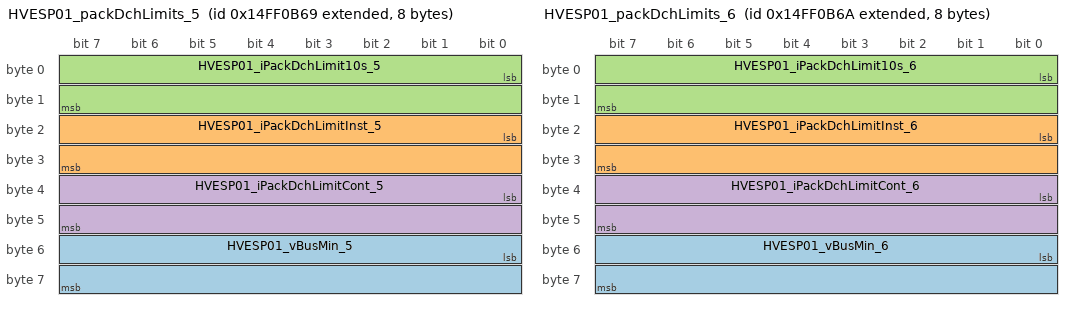
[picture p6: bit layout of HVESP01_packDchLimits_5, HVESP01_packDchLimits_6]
BO_ 2499742569 HVESP01_packDchLimits_5: 8 HVESP01
 SG_ HVESP01_vBusMin_5 : 48|16@1+ (0.02,0) [0|1310.7] "V"  HVESP01
 SG_ HVESP01_iPackDchLimitInst_5 : 16|16@1- (0.1,0) [-3276.8|0] "A"  HVESP01
 SG_ HVESP01_iPackDchLimit10s_5 : 0|16@1- (-0.1,0) [-3276.7|0] "A"  HVESP01
 SG_ HVESP01_iPackDchLimitCont_5 : 32|16@1- (0.02,0) [-655.36|0] "A"  HVESP01

BO_ 2499742570 HVESP01_packDchLimits_6: 8 HVESP01
 SG_ HVESP01_vBusMin_6 : 48|16@1+ (0.02,0) [0|1310.7] "V"  HVESP01
 SG_ HVESP01_iPackDchLimitInst_6 : 16|16@1- (0.1,0) [-3276.8|0] "A"  HVESP01
 SG_ HVESP01_iPackDchLimit10s_6 : 0|16@1- (-0.1,0) [-3276.7|0] "A"  HVESP01
 SG_ HVESP01_iPackDchLimitCont_6 : 32|16@1- (0.02,0) [-655.36|0] "A"  HVESP01

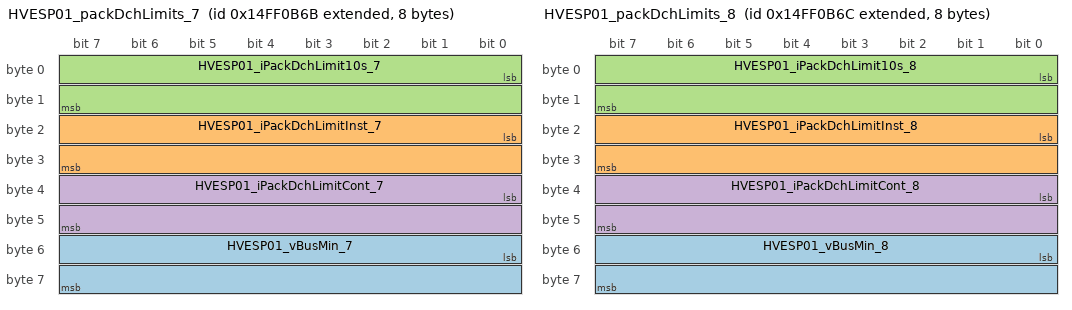
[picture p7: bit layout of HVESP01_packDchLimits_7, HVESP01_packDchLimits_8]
BO_ 2499742571 HVESP01_packDchLimits_7: 8 HVESP01
 SG_ HVESP01_vBusMin_7 : 48|16@1+ (0.02,0) [0|1310.7] "V"  HVESP01
 SG_ HVESP01_iPackDchLimitInst_7 : 16|16@1- (0.1,0) [-3276.8|0] "A"  HVESP01
 SG_ HVESP01_iPackDchLimit10s_7 : 0|16@1- (-0.1,0) [-3276.7|0] "A"  HVESP01
 SG_ HVESP01_iPackDchLimitCont_7 : 32|16@1- (0.02,0) [-655.36|0] "A"  HVESP01

BO_ 2499742572 HVESP01_packDchLimits_8: 8 HVESP01
 SG_ HVESP01_vBusMin_8 : 48|16@1+ (0.02,0) [0|1310.7] "V"  HVESP01
 SG_ HVESP01_iPackDchLimitInst_8 : 16|16@1- (0.1,0) [-3276.8|0] "A"  HVESP01
 SG_ HVESP01_iPackDchLimit10s_8 : 0|16@1- (-0.1,0) [-3276.7|0] "A"  HVESP01
 SG_ HVESP01_iPackDchLimitCont_8 : 32|16@1- (0.02,0) [-655.36|0] "A"  HVESP01

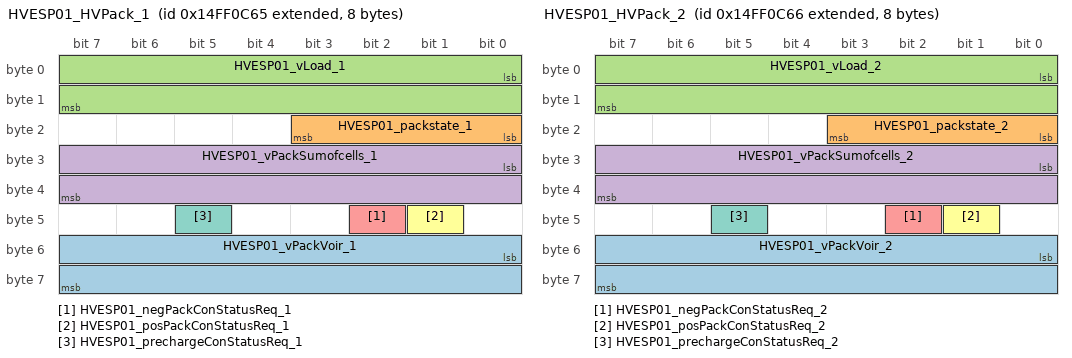
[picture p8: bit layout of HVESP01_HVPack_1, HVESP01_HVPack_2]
BO_ 2499742821 HVESP01_HVPack_1: 8 HVESP01
 SG_ HVESP01_vPackVoir_1 : 48|16@1+ (0.05,0) [0|3276.75] "V"  HVESP01
 SG_ HVESP01_packstate_1 : 16|4@1+ (1,0) [0|15] ""  HVESP01
 SG_ HVESP01_vLoad_1 : 0|16@1+ (0.05,0) [0|3276.75] "V"  HVESP01
 SG_ HVESP01_vPackSumofcells_1 : 24|16@1+ (0.05,0) [0|3276.75] "V"  HVESP01
 SG_ HVESP01_negPackConStatusReq_1 : 42|1@1+ (1,0) [0|1] ""  HVESP01
 SG_ HVESP01_posPackConStatusReq_1 : 41|1@1+ (1,0) [0|1] ""  HVESP01
 SG_ HVESP01_prechargeConStatusReq_1 : 45|1@1+ (1,0) [0|1] ""  HVESP01

BO_ 2499742822 HVESP01_HVPack_2: 8 HVESP01
 SG_ HVESP01_vPackVoir_2 : 48|16@1+ (0.05,0) [0|3276.75] "V"  HVESP01
 SG_ HVESP01_packstate_2 : 16|4@1+ (1,0) [0|15] ""  HVESP01
 SG_ HVESP01_vLoad_2 : 0|16@1+ (0.05,0) [0|3276.75] "V"  HVESP01
 SG_ HVESP01_vPackSumofcells_2 : 24|16@1+ (0.05,0) [0|3276.75] "V"  HVESP01
 SG_ HVESP01_negPackConStatusReq_2 : 42|1@1+ (1,0) [0|1] ""  HVESP01
 SG_ HVESP01_posPackConStatusReq_2 : 41|1@1+ (1,0) [0|1] ""  HVESP01
 SG_ HVESP01_prechargeConStatusReq_2 : 45|1@1+ (1,0) [0|1] ""  HVESP01

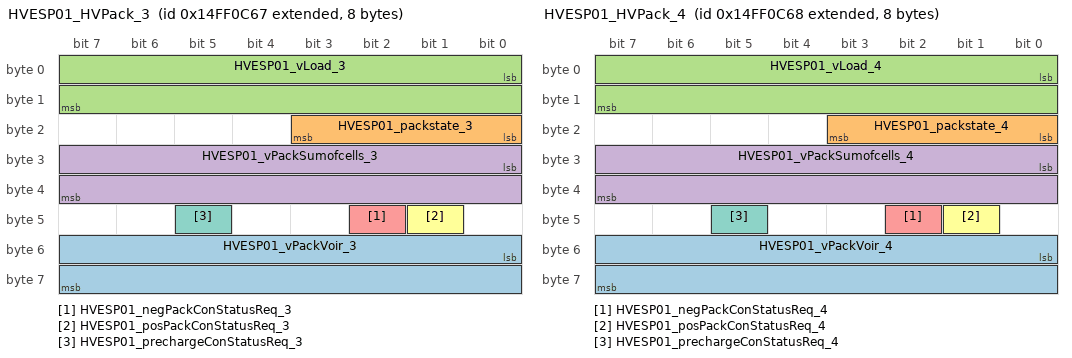
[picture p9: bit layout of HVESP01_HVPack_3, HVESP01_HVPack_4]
BO_ 2499742823 HVESP01_HVPack_3: 8 HVESP01
 SG_ HVESP01_vPackVoir_3 : 48|16@1+ (0.05,0) [0|3276.75] "V"  HVESP01
 SG_ HVESP01_packstate_3 : 16|4@1+ (1,0) [0|15] ""  HVESP01
 SG_ HVESP01_vLoad_3 : 0|16@1+ (0.05,0) [0|3276.75] "V"  HVESP01
 SG_ HVESP01_vPackSumofcells_3 : 24|16@1+ (0.05,0) [0|3276.75] "V"  HVESP01
 SG_ HVESP01_negPackConStatusReq_3 : 42|1@1+ (1,0) [0|1] ""  HVESP01
 SG_ HVESP01_posPackConStatusReq_3 : 41|1@1+ (1,0) [0|1] ""  HVESP01
 SG_ HVESP01_prechargeConStatusReq_3 : 45|1@1+ (1,0) [0|1] ""  HVESP01

BO_ 2499742824 HVESP01_HVPack_4: 8 HVESP01
 SG_ HVESP01_vPackVoir_4 : 48|16@1+ (0.05,0) [0|3276.75] "V"  HVESP01
 SG_ HVESP01_packstate_4 : 16|4@1+ (1,0) [0|15] ""  HVESP01
 SG_ HVESP01_vLoad_4 : 0|16@1+ (0.05,0) [0|3276.75] "V"  HVESP01
 SG_ HVESP01_vPackSumofcells_4 : 24|16@1+ (0.05,0) [0|3276.75] "V"  HVESP01
 SG_ HVESP01_negPackConStatusReq_4 : 42|1@1+ (1,0) [0|1] ""  HVESP01
 SG_ HVESP01_posPackConStatusReq_4 : 41|1@1+ (1,0) [0|1] ""  HVESP01
 SG_ HVESP01_prechargeConStatusReq_4 : 45|1@1+ (1,0) [0|1] ""  HVESP01

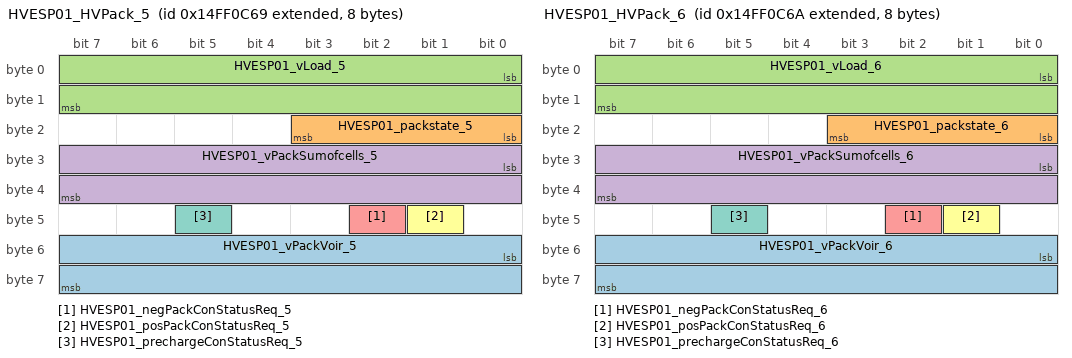
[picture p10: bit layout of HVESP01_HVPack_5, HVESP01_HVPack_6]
BO_ 2499742825 HVESP01_HVPack_5: 8 HVESP01
 SG_ HVESP01_vPackVoir_5 : 48|16@1+ (0.05,0) [0|3276.75] "V"  HVESP01
 SG_ HVESP01_packstate_5 : 16|4@1+ (1,0) [0|15] ""  HVESP01
 SG_ HVESP01_vLoad_5 : 0|16@1+ (0.05,0) [0|3276.75] "V"  HVESP01
 SG_ HVESP01_vPackSumofcells_5 : 24|16@1+ (0.05,0) [0|3276.75] "V"  HVESP01
 SG_ HVESP01_negPackConStatusReq_5 : 42|1@1+ (1,0) [0|1] ""  HVESP01
 SG_ HVESP01_posPackConStatusReq_5 : 41|1@1+ (1,0) [0|1] ""  HVESP01
 SG_ HVESP01_prechargeConStatusReq_5 : 45|1@1+ (1,0) [0|1] ""  HVESP01

BO_ 2499742826 HVESP01_HVPack_6: 8 HVESP01
 SG_ HVESP01_vPackVoir_6 : 48|16@1+ (0.05,0) [0|3276.75] "V"  HVESP01
 SG_ HVESP01_packstate_6 : 16|4@1+ (1,0) [0|15] ""  HVESP01
 SG_ HVESP01_vLoad_6 : 0|16@1+ (0.05,0) [0|3276.75] "V"  HVESP01
 SG_ HVESP01_vPackSumofcells_6 : 24|16@1+ (0.05,0) [0|3276.75] "V"  HVESP01
 SG_ HVESP01_negPackConStatusReq_6 : 42|1@1+ (1,0) [0|1] ""  HVESP01
 SG_ HVESP01_posPackConStatusReq_6 : 41|1@1+ (1,0) [0|1] ""  HVESP01
 SG_ HVESP01_prechargeConStatusReq_6 : 45|1@1+ (1,0) [0|1] ""  HVESP01

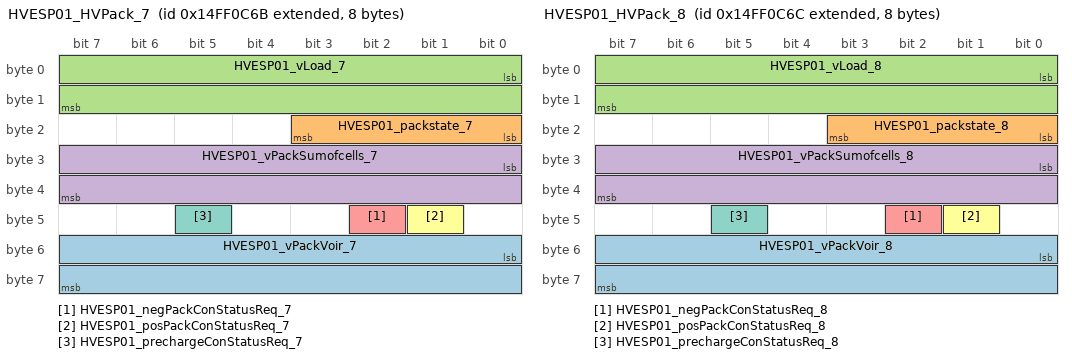
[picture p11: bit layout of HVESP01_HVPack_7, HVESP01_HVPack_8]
BO_ 2499742827 HVESP01_HVPack_7: 8 HVESP01
 SG_ HVESP01_vPackVoir_7 : 48|16@1+ (0.05,0) [0|3276.75] "V"  HVESP01
 SG_ HVESP01_packstate_7 : 16|4@1+ (1,0) [0|15] ""  HVESP01
 SG_ HVESP01_vLoad_7 : 0|16@1+ (0.05,0) [0|3276.75] "V"  HVESP01
 SG_ HVESP01_vPackSumofcells_7 : 24|16@1+ (0.05,0) [0|3276.75] "V"  HVESP01
 SG_ HVESP01_negPackConStatusReq_7 : 42|1@1+ (1,0) [0|1] ""  HVESP01
 SG_ HVESP01_posPackConStatusReq_7 : 41|1@1+ (1,0) [0|1] ""  HVESP01
 SG_ HVESP01_prechargeConStatusReq_7 : 45|1@1+ (1,0) [0|1] ""  HVESP01

BO_ 2499742828 HVESP01_HVPack_8: 8 HVESP01
 SG_ HVESP01_vPackVoir_8 : 48|16@1+ (0.05,0) [0|3276.75] "V"  HVESP01
 SG_ HVESP01_packstate_8 : 16|4@1+ (1,0) [0|15] ""  HVESP01
 SG_ HVESP01_vLoad_8 : 0|16@1+ (0.05,0) [0|3276.75] "V"  HVESP01
 SG_ HVESP01_vPackSumofcells_8 : 24|16@1+ (0.05,0) [0|3276.75] "V"  HVESP01
 SG_ HVESP01_negPackConStatusReq_8 : 42|1@1+ (1,0) [0|1] ""  HVESP01
 SG_ HVESP01_posPackConStatusReq_8 : 41|1@1+ (1,0) [0|1] ""  HVESP01
 SG_ HVESP01_prechargeConStatusReq_8 : 45|1@1+ (1,0) [0|1] ""  HVESP01

BO_ 2499743077 HVESP01_Version_1: 8 HVESP01
 SG_ HVESP01_SwVerSubMinorApp_1 m0: 24|8@1+ (1,0) [0|255] ""  HVESP01
 SG_ HVESP01_SwVerMinorApp_1 m0: 16|8@1+ (1,0) [0|255] ""  HVESP01
 SG_ HVESP01_SwVerMajorApp_1 m0: 8|8@1+ (1,0) [0|255] ""  HVESP01
 SG_ HVESP01_HwVerApp_1 m0: 32|8@1+ (1,0) [0|255] ""  HVESP01
 SG_ HVESP01_SwVerAbsCusApp_1 m0: 40|8@1+ (1,0) [0|255] ""  HVESP01
 SG_ HVESP01_SwVerAbsIntApp_1 m0: 48|8@1+ (1,0) [0|255] ""  HVESP01
 SG_ HVESP01_SwVerSubMinorBl_1 m1: 24|8@1+ (1,0) [0|255] ""  HVESP01
 SG_ HVESP01_SwVerMinorBl_1 m1: 16|8@1+ (1,0) [0|255] ""  HVESP01
 SG_ HVESP01_SwVerMajorBl_1 m1: 8|8@1+ (1,0) [0|255] ""  HVESP01
 SG_ HVESP01_HwVerBl_1 m1: 32|8@1+ (1,0) [0|255] ""  HVESP01
 SG_ HVESP01_SwVerAbsCusBl_1 m1: 40|8@1+ (1,0) [0|255] ""  HVESP01
 SG_ HVESP01_SwVerAbsIntBl_1 m1: 48|8@1+ (1,0) [0|255] ""  HVESP01
 SG_ HVESP01_SwVerSubMinorCal_1 m2: 24|8@1+ (1,0) [0|255] ""  HVESP01
 SG_ HVESP01_SwVerMinorCal_1 m2: 16|8@1+ (1,0) [0|255] ""  HVESP01
 SG_ HVESP01_SwVerMajorCal_1 m2: 8|8@1+ (1,0) [0|255] ""  HVESP01
 SG_ HVESP01_HwVerCal_1 m2: 32|8@1+ (1,0) [0|255] ""  HVESP01
 SG_ HVESP01_SwVerAbsCusCal_1 m2: 40|8@1+ (1,0) [0|255] ""  HVESP01
 SG_ HVESP01_SwVerAbsIntCal_1 m2: 48|8@1+ (1,0) [0|255] ""  HVESP01
 SG_ multiplexorvr_1 M: 0|2@1+ (1,0) [0|2] ""  HVESP01

BO_ 2499743078 HVESP01_Version_2: 8 HVESP01
 SG_ HVESP01_SwVerSubMinorApp_2 m0: 24|8@1+ (1,0) [0|255] ""  HVESP01
 SG_ HVESP01_SwVerMinorApp_2 m0: 16|8@1+ (1,0) [0|255] ""  HVESP01
 SG_ HVESP01_SwVerMajorApp_2 m0: 8|8@1+ (1,0) [0|255] ""  HVESP01
 SG_ HVESP01_HwVerApp_2 m0: 32|8@1+ (1,0) [0|255] ""  HVESP01
 SG_ HVESP01_SwVerAbsCusApp_2 m0: 40|8@1+ (1,0) [0|255] ""  HVESP01
 SG_ HVESP01_SwVerAbsIntApp_2 m0: 48|8@1+ (1,0) [0|255] ""  HVESP01
 SG_ HVESP01_SwVerSubMinorBl_2 m1: 24|8@1+ (1,0) [0|255] ""  HVESP01
 SG_ HVESP01_SwVerMinorBl_2 m1: 16|8@1+ (1,0) [0|255] ""  HVESP01
 SG_ HVESP01_SwVerMajorBl_2 m1: 8|8@1+ (1,0) [0|255] ""  HVESP01
 SG_ HVESP01_HwVerBl_2 m1: 32|8@1+ (1,0) [0|255] ""  HVESP01
 SG_ HVESP01_SwVerAbsCusBl_2 m1: 40|8@1+ (1,0) [0|255] ""  HVESP01
 SG_ HVESP01_SwVerAbsIntBl_2 m1: 48|8@1+ (1,0) [0|255] ""  HVESP01
 SG_ HVESP01_SwVerSubMinorCal_2 m2: 24|8@1+ (1,0) [0|255] ""  HVESP01
 SG_ HVESP01_SwVerMinorCal_2 m2: 16|8@1+ (1,0) [0|255] ""  HVESP01
 SG_ HVESP01_SwVerMajorCal_2 m2: 8|8@1+ (1,0) [0|255] ""  HVESP01
 SG_ HVESP01_HwVerCal_2 m2: 32|8@1+ (1,0) [0|255] ""  HVESP01
 SG_ HVESP01_SwVerAbsCusCal_2 m2: 40|8@1+ (1,0) [0|255] ""  HVESP01
 SG_ HVESP01_SwVerAbsIntCal_2 m2: 48|8@1+ (1,0) [0|255] ""  HVESP01
 SG_ multiplexorvr_2 M: 0|2@1+ (1,0) [0|2] ""  HVESP01

BO_ 2499743079 HVESP01_Version_3: 8 HVESP01
 SG_ HVESP01_SwVerSubMinorApp_3 m0: 24|8@1+ (1,0) [0|255] ""  HVESP01
 SG_ HVESP01_SwVerMinorApp_3 m0: 16|8@1+ (1,0) [0|255] ""  HVESP01
 SG_ HVESP01_SwVerMajorApp_3 m0: 8|8@1+ (1,0) [0|255] ""  HVESP01
 SG_ HVESP01_HwVerApp_3 m0: 32|8@1+ (1,0) [0|255] ""  HVESP01
 SG_ HVESP01_SwVerAbsCusApp_3 m0: 40|8@1+ (1,0) [0|255] ""  HVESP01
 SG_ HVESP01_SwVerAbsIntApp_3 m0: 48|8@1+ (1,0) [0|255] ""  HVESP01
 SG_ HVESP01_SwVerSubMinorBl_3 m1: 24|8@1+ (1,0) [0|255] ""  HVESP01
 SG_ HVESP01_SwVerMinorBl_3 m1: 16|8@1+ (1,0) [0|255] ""  HVESP01
 SG_ HVESP01_SwVerMajorBl_3 m1: 8|8@1+ (1,0) [0|255] ""  HVESP01
 SG_ HVESP01_HwVerBl_3 m1: 32|8@1+ (1,0) [0|255] ""  HVESP01
 SG_ HVESP01_SwVerAbsCusBl_3 m1: 40|8@1+ (1,0) [0|255] ""  HVESP01
 SG_ HVESP01_SwVerAbsIntBl_3 m1: 48|8@1+ (1,0) [0|255] ""  HVESP01
 SG_ HVESP01_SwVerSubMinorCal_3 m2: 24|8@1+ (1,0) [0|255] ""  HVESP01
 SG_ HVESP01_SwVerMinorCal_3 m2: 16|8@1+ (1,0) [0|255] ""  HVESP01
 SG_ HVESP01_SwVerMajorCal_3 m2: 8|8@1+ (1,0) [0|255] ""  HVESP01
 SG_ HVESP01_HwVerCal_3 m2: 32|8@1+ (1,0) [0|255] ""  HVESP01
 SG_ HVESP01_SwVerAbsCusCal_3 m2: 40|8@1+ (1,0) [0|255] ""  HVESP01
 SG_ HVESP01_SwVerAbsIntCal_3 m2: 48|8@1+ (1,0) [0|255] ""  HVESP01
 SG_ multiplexorvr_3 M: 0|2@1+ (1,0) [0|2] ""  HVESP01

BO_ 2499743080 HVESP01_Version_4: 8 HVESP01
 SG_ HVESP01_SwVerSubMinorApp_4 m0: 24|8@1+ (1,0) [0|255] ""  HVESP01
 SG_ HVESP01_SwVerMinorApp_4 m0: 16|8@1+ (1,0) [0|255] ""  HVESP01
 SG_ HVESP01_SwVerMajorApp_4 m0: 8|8@1+ (1,0) [0|255] ""  HVESP01
 SG_ HVESP01_HwVerApp_4 m0: 32|8@1+ (1,0) [0|255] ""  HVESP01
 SG_ HVESP01_SwVerAbsCusApp_4 m0: 40|8@1+ (1,0) [0|255] ""  HVESP01
 SG_ HVESP01_SwVerAbsIntApp_4 m0: 48|8@1+ (1,0) [0|255] ""  HVESP01
 SG_ HVESP01_SwVerSubMinorBl_4 m1: 24|8@1+ (1,0) [0|255] ""  HVESP01
 SG_ HVESP01_SwVerMinorBl_4 m1: 16|8@1+ (1,0) [0|255] ""  HVESP01
 SG_ HVESP01_SwVerMajorBl_4 m1: 8|8@1+ (1,0) [0|255] ""  HVESP01
 SG_ HVESP01_HwVerBl_4 m1: 32|8@1+ (1,0) [0|255] ""  HVESP01
 SG_ HVESP01_SwVerAbsCusBl_4 m1: 40|8@1+ (1,0) [0|255] ""  HVESP01
 SG_ HVESP01_SwVerAbsIntBl_4 m1: 48|8@1+ (1,0) [0|255] ""  HVESP01
 SG_ HVESP01_SwVerSubMinorCal_4 m2: 24|8@1+ (1,0) [0|255] ""  HVESP01
 SG_ HVESP01_SwVerMinorCal_4 m2: 16|8@1+ (1,0) [0|255] ""  HVESP01
 SG_ HVESP01_SwVerMajorCal_4 m2: 8|8@1+ (1,0) [0|255] ""  HVESP01
 SG_ HVESP01_HwVerCal_4 m2: 32|8@1+ (1,0) [0|255] ""  HVESP01
 SG_ HVESP01_SwVerAbsCusCal_4 m2: 40|8@1+ (1,0) [0|255] ""  HVESP01
 SG_ HVESP01_SwVerAbsIntCal_4 m2: 48|8@1+ (1,0) [0|255] ""  HVESP01
 SG_ multiplexorvr_4 M: 0|2@1+ (1,0) [0|2] ""  HVESP01

BO_ 2499743081 HVESP01_Version_5: 8 HVESP01
 SG_ HVESP01_SwVerSubMinorApp_5 m0: 24|8@1+ (1,0) [0|255] ""  HVESP01
 SG_ HVESP01_SwVerMinorApp_5 m0: 16|8@1+ (1,0) [0|255] ""  HVESP01
 SG_ HVESP01_SwVerMajorApp_5 m0: 8|8@1+ (1,0) [0|255] ""  HVESP01
 SG_ HVESP01_HwVerApp_5 m0: 32|8@1+ (1,0) [0|255] ""  HVESP01
 SG_ HVESP01_SwVerAbsCusApp_5 m0: 40|8@1+ (1,0) [0|255] ""  HVESP01
 SG_ HVESP01_SwVerAbsIntApp_5 m0: 48|8@1+ (1,0) [0|255] ""  HVESP01
 SG_ HVESP01_SwVerSubMinorBl_5 m1: 24|8@1+ (1,0) [0|255] ""  HVESP01
 SG_ HVESP01_SwVerMinorBl_5 m1: 16|8@1+ (1,0) [0|255] ""  HVESP01
 SG_ HVESP01_SwVerMajorBl_5 m1: 8|8@1+ (1,0) [0|255] ""  HVESP01
 SG_ HVESP01_HwVerBl_5 m1: 32|8@1+ (1,0) [0|255] ""  HVESP01
 SG_ HVESP01_SwVerAbsCusBl_5 m1: 40|8@1+ (1,0) [0|255] ""  HVESP01
 SG_ HVESP01_SwVerAbsIntBl_5 m1: 48|8@1+ (1,0) [0|255] ""  HVESP01
 SG_ HVESP01_SwVerSubMinorCal_5 m2: 24|8@1+ (1,0) [0|255] ""  HVESP01
 SG_ HVESP01_SwVerMinorCal_5 m2: 16|8@1+ (1,0) [0|255] ""  HVESP01
 SG_ HVESP01_SwVerMajorCal_5 m2: 8|8@1+ (1,0) [0|255] ""  HVESP01
 SG_ HVESP01_HwVerCal_5 m2: 32|8@1+ (1,0) [0|255] ""  HVESP01
 SG_ HVESP01_SwVerAbsCusCal_5 m2: 40|8@1+ (1,0) [0|255] ""  HVESP01
 SG_ HVESP01_SwVerAbsIntCal_5 m2: 48|8@1+ (1,0) [0|255] ""  HVESP01
 SG_ multiplexorvr_5 M: 0|2@1+ (1,0) [0|2] ""  HVESP01

BO_ 2499743082 HVESP01_Version_6: 8 HVESP01
 SG_ HVESP01_SwVerSubMinorApp_6 m0: 24|8@1+ (1,0) [0|255] ""  HVESP01
 SG_ HVESP01_SwVerMinorApp_6 m0: 16|8@1+ (1,0) [0|255] ""  HVESP01
 SG_ HVESP01_SwVerMajorApp_6 m0: 8|8@1+ (1,0) [0|255] ""  HVESP01
 SG_ HVESP01_HwVerApp_6 m0: 32|8@1+ (1,0) [0|255] ""  HVESP01
 SG_ HVESP01_SwVerAbsCusApp_6 m0: 40|8@1+ (1,0) [0|255] ""  HVESP01
 SG_ HVESP01_SwVerAbsIntApp_6 m0: 48|8@1+ (1,0) [0|255] ""  HVESP01
 SG_ HVESP01_SwVerSubMinorBl_6 m1: 24|8@1+ (1,0) [0|255] ""  HVESP01
 SG_ HVESP01_SwVerMinorBl_6 m1: 16|8@1+ (1,0) [0|255] ""  HVESP01
 SG_ HVESP01_SwVerMajorBl_6 m1: 8|8@1+ (1,0) [0|255] ""  HVESP01
 SG_ HVESP01_HwVerBl_6 m1: 32|8@1+ (1,0) [0|255] ""  HVESP01
 SG_ HVESP01_SwVerAbsCusBl_6 m1: 40|8@1+ (1,0) [0|255] ""  HVESP01
 SG_ HVESP01_SwVerAbsIntBl_6 m1: 48|8@1+ (1,0) [0|255] ""  HVESP01
 SG_ HVESP01_SwVerSubMinorCal_6 m2: 24|8@1+ (1,0) [0|255] ""  HVESP01
 SG_ HVESP01_SwVerMinorCal_6 m2: 16|8@1+ (1,0) [0|255] ""  HVESP01
 SG_ HVESP01_SwVerMajorCal_6 m2: 8|8@1+ (1,0) [0|255] ""  HVESP01
 SG_ HVESP01_HwVerCal_6 m2: 32|8@1+ (1,0) [0|255] ""  HVESP01
 SG_ HVESP01_SwVerAbsCusCal_6 m2: 40|8@1+ (1,0) [0|255] ""  HVESP01
 SG_ HVESP01_SwVerAbsIntCal_6 m2: 48|8@1+ (1,0) [0|255] ""  HVESP01
 SG_ multiplexorvr_6 M: 0|2@1+ (1,0) [0|2] ""  HVESP01

BO_ 2499743083 HVESP01_Version_7: 8 HVESP01
 SG_ HVESP01_SwVerSubMinorApp_7 m0: 24|8@1+ (1,0) [0|255] ""  HVESP01
 SG_ HVESP01_SwVerMinorApp_7 m0: 16|8@1+ (1,0) [0|255] ""  HVESP01
 SG_ HVESP01_SwVerMajorApp_7 m0: 8|8@1+ (1,0) [0|255] ""  HVESP01
 SG_ HVESP01_HwVerApp_7 m0: 32|8@1+ (1,0) [0|255] ""  HVESP01
 SG_ HVESP01_SwVerAbsCusApp_7 m0: 40|8@1+ (1,0) [0|255] ""  HVESP01
 SG_ HVESP01_SwVerAbsIntApp_7 m0: 48|8@1+ (1,0) [0|255] ""  HVESP01
 SG_ HVESP01_SwVerSubMinorBl_7 m1: 24|8@1+ (1,0) [0|255] ""  HVESP01
 SG_ HVESP01_SwVerMinorBl_7 m1: 16|8@1+ (1,0) [0|255] ""  HVESP01
 SG_ HVESP01_SwVerMajorBl_7 m1: 8|8@1+ (1,0) [0|255] ""  HVESP01
 SG_ HVESP01_HwVerBl_7 m1: 32|8@1+ (1,0) [0|255] ""  HVESP01
 SG_ HVESP01_SwVerAbsCusBl_7 m1: 40|8@1+ (1,0) [0|255] ""  HVESP01
 SG_ HVESP01_SwVerAbsIntBl_7 m1: 48|8@1+ (1,0) [0|255] ""  HVESP01
 SG_ HVESP01_SwVerSubMinorCal_7 m2: 24|8@1+ (1,0) [0|255] ""  HVESP01
 SG_ HVESP01_SwVerMinorCal_7 m2: 16|8@1+ (1,0) [0|255] ""  HVESP01
 SG_ HVESP01_SwVerMajorCal_7 m2: 8|8@1+ (1,0) [0|255] ""  HVESP01
 SG_ HVESP01_HwVerCal_7 m2: 32|8@1+ (1,0) [0|255] ""  HVESP01
 SG_ HVESP01_SwVerAbsCusCal_7 m2: 40|8@1+ (1,0) [0|255] ""  HVESP01
 SG_ HVESP01_SwVerAbsIntCal_7 m2: 48|8@1+ (1,0) [0|255] ""  HVESP01
 SG_ multiplexorvr_7 M: 0|2@1+ (1,0) [0|2] ""  HVESP01

BO_ 2499743084 HVESP01_Version_8: 8 HVESP01
 SG_ HVESP01_SwVerSubMinorApp_8 m0: 24|8@1+ (1,0) [0|255] ""  HVESP01
 SG_ HVESP01_SwVerMinorApp_8 m0: 16|8@1+ (1,0) [0|255] ""  HVESP01
 SG_ HVESP01_SwVerMajorApp_8 m0: 8|8@1+ (1,0) [0|255] ""  HVESP01
 SG_ HVESP01_HwVerApp_8 m0: 32|8@1+ (1,0) [0|255] ""  HVESP01
 SG_ HVESP01_SwVerAbsCusApp_8 m0: 40|8@1+ (1,0) [0|255] ""  HVESP01
 SG_ HVESP01_SwVerAbsIntApp_8 m0: 48|8@1+ (1,0) [0|255] ""  HVESP01
 SG_ HVESP01_SwVerSubMinorBl_8 m1: 24|8@1+ (1,0) [0|255] ""  HVESP01
 SG_ HVESP01_SwVerMinorBl_8 m1: 16|8@1+ (1,0) [0|255] ""  HVESP01
 SG_ HVESP01_SwVerMajorBl_8 m1: 8|8@1+ (1,0) [0|255] ""  HVESP01
 SG_ HVESP01_HwVerBl_8 m1: 32|8@1+ (1,0) [0|255] ""  HVESP01
 SG_ HVESP01_SwVerAbsCusBl_8 m1: 40|8@1+ (1,0) [0|255] ""  HVESP01
 SG_ HVESP01_SwVerAbsIntBl_8 m1: 48|8@1+ (1,0) [0|255] ""  HVESP01
 SG_ HVESP01_SwVerSubMinorCal_8 m2: 24|8@1+ (1,0) [0|255] ""  HVESP01
 SG_ HVESP01_SwVerMinorCal_8 m2: 16|8@1+ (1,0) [0|255] ""  HVESP01
 SG_ HVESP01_SwVerMajorCal_8 m2: 8|8@1+ (1,0) [0|255] ""  HVESP01
 SG_ HVESP01_HwVerCal_8 m2: 32|8@1+ (1,0) [0|255] ""  HVESP01
 SG_ HVESP01_SwVerAbsCusCal_8 m2: 40|8@1+ (1,0) [0|255] ""  HVESP01
 SG_ HVESP01_SwVerAbsIntCal_8 m2: 48|8@1+ (1,0) [0|255] ""  HVESP01
 SG_ multiplexorvr_8 M: 0|2@1+ (1,0) [0|2] ""  HVESP01

BO_ 2499743333 HVESP01_CellBalance_1: 8 HVESP01
 SG_ HVESP01_CellBalance_01_1 m0: 8|1@1+ (1,0) [0|1] ""  HVESP01
 SG_ HVESP01_CellBalance_02_1 m0: 9|1@1+ (1,0) [0|1] ""  HVESP01
 SG_ HVESP01_CellBalance_03_1 m0: 10|1@1+ (1,0) [0|1] ""  HVESP01
 SG_ HVESP01_CellBalance_04_1 m0: 11|1@1+ (1,0) [0|1] ""  HVESP01
 SG_ HVESP01_CellBalance_05_1 m0: 12|1@1+ (1,0) [0|1] ""  HVESP01
 SG_ HVESP01_CellBalance_06_1 m0: 13|1@1+ (1,0) [0|1] ""  HVESP01
 SG_ HVESP01_CellBalance_07_1 m0: 14|1@1+ (1,0) [0|1] ""  HVESP01
 SG_ HVESP01_CellBalance_08_1 m0: 15|1@1+ (1,0) [0|1] ""  HVESP01
 SG_ HVESP01_CellBalance_09_1 m1: 8|1@1+ (1,0) [0|1] ""  HVESP01
 SG_ HVESP01_CellBalance_10_1 m1: 9|1@1+ (1,0) [0|1] ""  HVESP01
 SG_ HVESP01_CellBalance_11_1 m1: 10|1@1+ (1,0) [0|1] ""  HVESP01
 SG_ HVESP01_CellBalance_12_1 m1: 11|1@1+ (1,0) [0|1] ""  HVESP01
 SG_ HVESP01_CellBalance_13_1 m1: 12|1@1+ (1,0) [0|1] ""  HVESP01
 SG_ HVESP01_CellBalance_14_1 m1: 13|1@1+ (1,0) [0|1] ""  HVESP01
 SG_ HVESP01_CellBalance_15_1 m1: 14|1@1+ (1,0) [0|1] ""  HVESP01
 SG_ HVESP01_CellBalance_16_1 m1: 15|1@1+ (1,0) [0|1] ""  HVESP01
 SG_ HVESP01_CellBalance_17_1 m2: 8|1@1+ (1,0) [0|1] ""  HVESP01
 SG_ HVESP01_CellBalance_18_1 m2: 9|1@1+ (1,0) [0|1] ""  HVESP01
 SG_ HVESP01_CellBalance_19_1 m2: 10|1@1+ (1,0) [0|1] ""  HVESP01
 SG_ HVESP01_CellBalance_20_1 m2: 11|1@1+ (1,0) [0|1] ""  HVESP01
 SG_ HVESP01_CellBalance_21_1 m2: 12|1@1+ (1,0) [0|1] ""  HVESP01
 SG_ HVESP01_CellBalance_22_1 m2: 13|1@1+ (1,0) [0|1] ""  HVESP01
 SG_ HVESP01_CellBalance_23_1 m2: 14|1@1+ (1,0) [0|1] ""  HVESP01
 SG_ HVESP01_CellBalance_24_1 m2: 15|1@1+ (1,0) [0|1] ""  HVESP01
 SG_ HVESP01_CellBalance_25_1 m3: 8|1@1+ (1,0) [0|1] ""  HVESP01
 SG_ HVESP01_CellBalance_26_1 m3: 9|1@1+ (1,0) [0|1] ""  HVESP01
 SG_ HVESP01_CellBalance_27_1 m3: 10|1@1+ (1,0) [0|1] ""  HVESP01
 SG_ HVESP01_CellBalance_28_1 m3: 11|1@1+ (1,0) [0|1] ""  HVESP01
 SG_ HVESP01_CellBalance_29_1 m3: 12|1@1+ (1,0) [0|1] ""  HVESP01
 SG_ HVESP01_CellBalance_30_1 m3: 13|1@1+ (1,0) [0|1] ""  HVESP01
 SG_ HVESP01_CellBalance_31_1 m3: 14|1@1+ (1,0) [0|1] ""  HVESP01
 SG_ HVESP01_CellBalance_32_1 m3: 15|1@1+ (1,0) [0|1] ""  HVESP01
 SG_ HVESP01_CellBalance_33_1 m4: 8|1@1+ (1,0) [0|1] ""  HVESP01
 SG_ HVESP01_CellBalance_34_1 m4: 9|1@1+ (1,0) [0|1] ""  HVESP01
 SG_ HVESP01_CellBalance_35_1 m4: 10|1@1+ (1,0) [0|1] ""  HVESP01
 SG_ HVESP01_CellBalance_36_1 m4: 11|1@1+ (1,0) [0|1] ""  HVESP01
 SG_ HVESP01_CellBalance_37_1 m4: 12|1@1+ (1,0) [0|1] ""  HVESP01
 SG_ HVESP01_CellBalance_38_1 m4: 13|1@1+ (1,0) [0|1] ""  HVESP01
 SG_ HVESP01_CellBalance_39_1 m4: 14|1@1+ (1,0) [0|1] ""  HVESP01
 SG_ HVESP01_CellBalance_40_1 m4: 15|1@1+ (1,0) [0|1] ""  HVESP01
 SG_ HVESP01_CellBalance_41_1 m5: 8|1@1+ (1,0) [0|1] ""  HVESP01
 SG_ HVESP01_CellBalance_42_1 m5: 9|1@1+ (1,0) [0|1] ""  HVESP01
 SG_ HVESP01_CellBalance_43_1 m5: 10|1@1+ (1,0) [0|1] ""  HVESP01
 SG_ HVESP01_CellBalance_44_1 m5: 11|1@1+ (1,0) [0|1] ""  HVESP01
 SG_ HVESP01_CellBalance_45_1 m5: 12|1@1+ (1,0) [0|1] ""  HVESP01
 SG_ HVESP01_CellBalance_46_1 m5: 13|1@1+ (1,0) [0|1] ""  HVESP01
 SG_ HVESP01_CellBalance_47_1 m5: 14|1@1+ (1,0) [0|1] ""  HVESP01
 SG_ HVESP01_CellBalance_48_1 m5: 15|1@1+ (1,0) [0|1] ""  HVESP01
 SG_ HVESP01_CellBalance_49_1 m6: 8|1@1+ (1,0) [0|1] ""  HVESP01
 SG_ HVESP01_CellBalance_50_1 m6: 9|1@1+ (1,0) [0|1] ""  HVESP01
 SG_ HVESP01_CellBalance_51_1 m6: 10|1@1+ (1,0) [0|1] ""  HVESP01
 SG_ HVESP01_CellBalance_52_1 m6: 11|1@1+ (1,0) [0|1] ""  HVESP01
 SG_ HVESP01_CellBalance_53_1 m6: 12|1@1+ (1,0) [0|1] ""  HVESP01
 SG_ HVESP01_CellBalance_54_1 m6: 13|1@1+ (1,0) [0|1] ""  HVESP01
 SG_ HVESP01_CellBalance_55_1 m6: 14|1@1+ (1,0) [0|1] ""  HVESP01
 SG_ HVESP01_CellBalance_56_1 m6: 15|1@1+ (1,0) [0|1] ""  HVESP01
 SG_ HVESP01_CellBalance_57_1 m7: 8|1@1+ (1,0) [0|1] ""  HVESP01
 SG_ HVESP01_CellBalance_58_1 m7: 9|1@1+ (1,0) [0|1] ""  HVESP01
 SG_ HVESP01_CellBalance_59_1 m7: 10|1@1+ (1,0) [0|1] ""  HVESP01
 SG_ HVESP01_CellBalance_60_1 m7: 11|1@1+ (1,0) [0|1] ""  HVESP01
 SG_ HVESP01_CellBalance_61_1 m7: 12|1@1+ (1,0) [0|1] ""  HVESP01
 SG_ HVESP01_CellBalance_62_1 m7: 13|1@1+ (1,0) [0|1] ""  HVESP01
 SG_ HVESP01_CellBalance_63_1 m7: 14|1@1+ (1,0) [0|1] ""  HVESP01
 SG_ HVESP01_CellBalance_64_1 m7: 15|1@1+ (1,0) [0|1] ""  HVESP01
 SG_ HVESP01_CellBalance_65_1 m8: 8|1@1+ (1,0) [0|1] ""  HVESP01
 SG_ HVESP01_CellBalance_66_1 m8: 9|1@1+ (1,0) [0|1] ""  HVESP01
 SG_ HVESP01_CellBalance_67_1 m8: 10|1@1+ (1,0) [0|1] ""  HVESP01
 SG_ HVESP01_CellBalance_68_1 m8: 11|1@1+ (1,0) [0|1] ""  HVESP01
 SG_ HVESP01_CellBalance_69_1 m8: 12|1@1+ (1,0) [0|1] ""  HVESP01
 SG_ HVESP01_CellBalance_70_1 m8: 13|1@1+ (1,0) [0|1] ""  HVESP01
 SG_ HVESP01_CellBalance_71_1 m8: 14|1@1+ (1,0) [0|1] ""  HVESP01
 SG_ HVESP01_CellBalance_72_1 m8: 15|1@1+ (1,0) [0|1] ""  HVESP01
 SG_ HVESP01_CellBalance_73_1 m9: 8|1@1+ (1,0) [0|1] ""  HVESP01
 SG_ HVESP01_CellBalance_74_1 m9: 9|1@1+ (1,0) [0|1] ""  HVESP01
 SG_ HVESP01_CellBalance_75_1 m9: 10|1@1+ (1,0) [0|1] ""  HVESP01
 SG_ HVESP01_CellBalance_76_1 m9: 11|1@1+ (1,0) [0|1] ""  HVESP01
 SG_ HVESP01_CellBalance_77_1 m9: 12|1@1+ (1,0) [0|1] ""  HVESP01
 SG_ HVESP01_CellBalance_78_1 m9: 13|1@1+ (1,0) [0|1] ""  HVESP01
 SG_ HVESP01_CellBalance_79_1 m9: 14|1@1+ (1,0) [0|1] ""  HVESP01
 SG_ HVESP01_CellBalance_80_1 m9: 15|1@1+ (1,0) [0|1] ""  HVESP01
 SG_ HVESP01_CellBalance_81_1 m10: 8|1@1+ (1,0) [0|1] ""  HVESP01
 SG_ HVESP01_CellBalance_82_1 m10: 9|1@1+ (1,0) [0|1] ""  HVESP01
 SG_ HVESP01_CellBalance_83_1 m10: 10|1@1+ (1,0) [0|1] ""  HVESP01
 SG_ HVESP01_CellBalance_84_1 m10: 11|1@1+ (1,0) [0|1] ""  HVESP01
 SG_ HVESP01_CellBalance_85_1 m10: 12|1@1+ (1,0) [0|1] ""  HVESP01
 SG_ HVESP01_CellBalance_86_1 m10: 13|1@1+ (1,0) [0|1] ""  HVESP01
 SG_ HVESP01_CellBalance_87_1 m10: 14|1@1+ (1,0) [0|1] ""  HVESP01
 SG_ HVESP01_CellBalance_88_1 m10: 15|1@1+ (1,0) [0|1] ""  HVESP01
 SG_ HVESP01_CellBalance_89_1 m11: 8|1@1+ (1,0) [0|1] ""  HVESP01
 SG_ HVESP01_CellBalance_90_1 m11: 9|1@1+ (1,0) [0|1] ""  HVESP01
 SG_ HVESP01_CellBalance_91_1 m11: 10|1@1+ (1,0) [0|1] ""  HVESP01
 SG_ HVESP01_CellBalance_92_1 m11: 11|1@1+ (1,0) [0|1] ""  HVESP01
 SG_ HVESP01_CellBalance_93_1 m11: 12|1@1+ (1,0) [0|1] ""  HVESP01
 SG_ HVESP01_CellBalance_94_1 m11: 13|1@1+ (1,0) [0|1] ""  HVESP01
 SG_ HVESP01_CellBalance_95_1 m11: 14|1@1+ (1,0) [0|1] ""  HVESP01
 SG_ HVESP01_CellBalance_96_1 m11: 15|1@1+ (1,0) [0|1] ""  HVESP01
 SG_ HVESP01_CellBalance_97_1 m12: 8|1@1+ (1,0) [0|1] ""  HVESP01
 SG_ HVESP01_CellBalance_98_1 m12: 9|1@1+ (1,0) [0|1] ""  HVESP01
 SG_ HVESP01_CellBalance_99_1 m12: 10|1@1+ (1,0) [0|1] ""  HVESP01
 SG_ HVESP01_CellBalance_100_1 m12: 11|1@1+ (1,0) [0|1] ""  HVESP01
 SG_ HVESP01_CellBalance_101_1 m12: 12|1@1+ (1,0) [0|1] ""  HVESP01
 SG_ HVESP01_CellBalance_102_1 m12: 13|1@1+ (1,0) [0|1] ""  HVESP01
 SG_ HVESP01_CellBalance_103_1 m12: 14|1@1+ (1,0) [0|1] ""  HVESP01
 SG_ HVESP01_CellBalance_104_1 m12: 15|1@1+ (1,0) [0|1] ""  HVESP01
 SG_ HVESP01_CellBalance_105_1 m13: 8|1@1+ (1,0) [0|1] ""  HVESP01
 SG_ HVESP01_CellBalance_106_1 m13: 9|1@1+ (1,0) [0|1] ""  HVESP01
 SG_ HVESP01_CellBalance_107_1 m13: 10|1@1+ (1,0) [0|1] ""  HVESP01
 SG_ HVESP01_CellBalance_108_1 m13: 11|1@1+ (1,0) [0|1] ""  HVESP01
 SG_ HVESP01_CellBalance_109_1 m13: 12|1@1+ (1,0) [0|1] ""  HVESP01
 SG_ HVESP01_CellBalance_110_1 m13: 13|1@1+ (1,0) [0|1] ""  HVESP01
 SG_ HVESP01_CellBalance_111_1 m13: 14|1@1+ (1,0) [0|1] ""  HVESP01
 SG_ HVESP01_CellBalance_112_1 m13: 15|1@1+ (1,0) [0|1] ""  HVESP01
 SG_ HVESP01_CellBalance_113_1 m14: 8|1@1+ (1,0) [0|1] ""  HVESP01
 SG_ HVESP01_CellBalance_114_1 m14: 9|1@1+ (1,0) [0|1] ""  HVESP01
 SG_ HVESP01_CellBalance_115_1 m14: 10|1@1+ (1,0) [0|1] ""  HVESP01
 SG_ HVESP01_CellBalance_116_1 m14: 11|1@1+ (1,0) [0|1] ""  HVESP01
 SG_ HVESP01_CellBalance_117_1 m14: 12|1@1+ (1,0) [0|1] ""  HVESP01
 SG_ HVESP01_CellBalance_118_1 m14: 13|1@1+ (1,0) [0|1] ""  HVESP01
 SG_ HVESP01_CellBalance_119_1 m14: 14|1@1+ (1,0) [0|1] ""  HVESP01
 SG_ HVESP01_CellBalance_120_1 m14: 15|1@1+ (1,0) [0|1] ""  HVESP01
 SG_ HVESP01_CellBalance_121_1 m15: 8|1@1+ (1,0) [0|1] ""  HVESP01
 SG_ HVESP01_CellBalance_122_1 m15: 9|1@1+ (1,0) [0|1] ""  HVESP01
 SG_ HVESP01_CellBalance_123_1 m15: 10|1@1+ (1,0) [0|1] ""  HVESP01
 SG_ HVESP01_CellBalance_124_1 m15: 11|1@1+ (1,0) [0|1] ""  HVESP01
 SG_ HVESP01_CellBalance_125_1 m15: 12|1@1+ (1,0) [0|1] ""  HVESP01
 SG_ HVESP01_CellBalance_126_1 m15: 13|1@1+ (1,0) [0|1] ""  HVESP01
 SG_ HVESP01_CellBalance_127_1 m15: 14|1@1+ (1,0) [0|1] ""  HVESP01
 SG_ HVESP01_CellBalance_128_1 m15: 15|1@1+ (1,0) [0|1] ""  HVESP01
 SG_ HVESP01_CellBalance_129_1 m16: 8|1@1+ (1,0) [0|1] ""  HVESP01
 SG_ HVESP01_CellBalance_130_1 m16: 9|1@1+ (1,0) [0|1] ""  HVESP01
 SG_ HVESP01_CellBalance_131_1 m16: 10|1@1+ (1,0) [0|1] ""  HVESP01
 SG_ HVESP01_CellBalance_132_1 m16: 11|1@1+ (1,0) [0|1] ""  HVESP01
 SG_ HVESP01_CellBalance_133_1 m16: 12|1@1+ (1,0) [0|1] ""  HVESP01
 SG_ HVESP01_CellBalance_134_1 m16: 13|1@1+ (1,0) [0|1] ""  HVESP01
 SG_ HVESP01_CellBalance_135_1 m16: 14|1@1+ (1,0) [0|1] ""  HVESP01
 SG_ HVESP01_CellBalance_136_1 m16: 15|1@1+ (1,0) [0|1] ""  HVESP01
 SG_ HVESP01_CellBalance_137_1 m17: 8|1@1+ (1,0) [0|1] ""  HVESP01
 SG_ HVESP01_CellBalance_138_1 m17: 9|1@1+ (1,0) [0|1] ""  HVESP01
 SG_ HVESP01_CellBalance_139_1 m17: 10|1@1+ (1,0) [0|1] ""  HVESP01
 SG_ HVESP01_CellBalance_140_1 m17: 11|1@1+ (1,0) [0|1] ""  HVESP01
 SG_ HVESP01_CellBalance_141_1 m17: 12|1@1+ (1,0) [0|1] ""  HVESP01
 SG_ HVESP01_CellBalance_142_1 m17: 13|1@1+ (1,0) [0|1] ""  HVESP01
 SG_ HVESP01_CellBalance_143_1 m17: 14|1@1+ (1,0) [0|1] ""  HVESP01
 SG_ HVESP01_CellBalance_144_1 m17: 15|1@1+ (1,0) [0|1] ""  HVESP01
 SG_ HVESP01_CellBalance_145_1 m18: 8|1@1+ (1,0) [0|1] ""  HVESP01
 SG_ HVESP01_CellBalance_146_1 m18: 9|1@1+ (1,0) [0|1] ""  HVESP01
 SG_ HVESP01_CellBalance_147_1 m18: 10|1@1+ (1,0) [0|1] ""  HVESP01
 SG_ HVESP01_CellBalance_148_1 m18: 11|1@1+ (1,0) [0|1] ""  HVESP01
 SG_ HVESP01_CellBalance_149_1 m18: 12|1@1+ (1,0) [0|1] ""  HVESP01
 SG_ HVESP01_CellBalance_150_1 m18: 13|1@1+ (1,0) [0|1] ""  HVESP01
 SG_ HVESP01_CellBalance_151_1 m18: 14|1@1+ (1,0) [0|1] ""  HVESP01
 SG_ HVESP01_CellBalance_152_1 m18: 15|1@1+ (1,0) [0|1] ""  HVESP01
 SG_ HVESP01_CellBalance_153_1 m19: 8|1@1+ (1,0) [0|1] ""  HVESP01
 SG_ HVESP01_CellBalance_154_1 m19: 9|1@1+ (1,0) [0|1] ""  HVESP01
 SG_ HVESP01_CellBalance_155_1 m19: 10|1@1+ (1,0) [0|1] ""  HVESP01
 SG_ HVESP01_CellBalance_156_1 m19: 11|1@1+ (1,0) [0|1] ""  HVESP01
 SG_ HVESP01_CellBalance_157_1 m19: 12|1@1+ (1,0) [0|1] ""  HVESP01
 SG_ HVESP01_CellBalance_158_1 m19: 13|1@1+ (1,0) [0|1] ""  HVESP01
 SG_ HVESP01_CellBalance_159_1 m19: 14|1@1+ (1,0) [0|1] ""  HVESP01
 SG_ HVESP01_CellBalance_160_1 m19: 15|1@1+ (1,0) [0|1] ""  HVESP01
 SG_ HVESP01_CellBalance_161_1 m20: 8|1@1+ (1,0) [0|1] ""  HVESP01
 SG_ HVESP01_CellBalance_162_1 m20: 9|1@1+ (1,0) [0|1] ""  HVESP01
 SG_ HVESP01_CellBalance_163_1 m20: 10|1@1+ (1,0) [0|1] ""  HVESP01
 SG_ HVESP01_CellBalance_164_1 m20: 11|1@1+ (1,0) [0|1] ""  HVESP01
 SG_ HVESP01_CellBalance_165_1 m20: 12|1@1+ (1,0) [0|1] ""  HVESP01
 SG_ HVESP01_CellBalance_166_1 m20: 13|1@1+ (1,0) [0|1] ""  HVESP01
 SG_ HVESP01_CellBalance_167_1 m20: 14|1@1+ (1,0) [0|1] ""  HVESP01
 SG_ HVESP01_CellBalance_168_1 m20: 15|1@1+ (1,0) [0|1] ""  HVESP01
 SG_ HVESP01_CellBalance_169_1 m21: 8|1@1+ (1,0) [0|1] ""  HVESP01
 SG_ HVESP01_CellBalance_170_1 m21: 9|1@1+ (1,0) [0|1] ""  HVESP01
 SG_ HVESP01_CellBalance_171_1 m21: 10|1@1+ (1,0) [0|1] ""  HVESP01
 SG_ HVESP01_CellBalance_172_1 m21: 11|1@1+ (1,0) [0|1] ""  HVESP01
 SG_ HVESP01_CellBalance_173_1 m21: 12|1@1+ (1,0) [0|1] ""  HVESP01
 SG_ HVESP01_CellBalance_174_1 m21: 13|1@1+ (1,0) [0|1] ""  HVESP01
 SG_ HVESP01_CellBalance_175_1 m21: 14|1@1+ (1,0) [0|1] ""  HVESP01
 SG_ HVESP01_CellBalance_176_1 m21: 15|1@1+ (1,0) [0|1] ""  HVESP01
 SG_ HVESP01_CellBalance_177_1 m22: 8|1@1+ (1,0) [0|1] ""  HVESP01
 SG_ HVESP01_CellBalance_178_1 m22: 9|1@1+ (1,0) [0|1] ""  HVESP01
 SG_ HVESP01_CellBalance_179_1 m22: 10|1@1+ (1,0) [0|1] ""  HVESP01
 SG_ HVESP01_CellBalance_180_1 m22: 11|1@1+ (1,0) [0|1] ""  HVESP01
 SG_ HVESP01_CellBalance_181_1 m22: 12|1@1+ (1,0) [0|1] ""  HVESP01
 SG_ HVESP01_CellBalance_182_1 m22: 13|1@1+ (1,0) [0|1] ""  HVESP01
 SG_ HVESP01_CellBalance_183_1 m22: 14|1@1+ (1,0) [0|1] ""  HVESP01
 SG_ HVESP01_CellBalance_184_1 m22: 15|1@1+ (1,0) [0|1] ""  HVESP01
 SG_ HVESP01_CellBalance_185_1 m23: 8|1@1+ (1,0) [0|1] ""  HVESP01
 SG_ HVESP01_CellBalance_186_1 m23: 9|1@1+ (1,0) [0|1] ""  HVESP01
 SG_ HVESP01_CellBalance_187_1 m23: 10|1@1+ (1,0) [0|1] ""  HVESP01
 SG_ HVESP01_CellBalance_188_1 m23: 11|1@1+ (1,0) [0|1] ""  HVESP01
 SG_ HVESP01_CellBalance_189_1 m23: 12|1@1+ (1,0) [0|1] ""  HVESP01
 SG_ HVESP01_CellBalance_190_1 m23: 13|1@1+ (1,0) [0|1] ""  HVESP01
 SG_ HVESP01_CellBalance_191_1 m23: 14|1@1+ (1,0) [0|1] ""  HVESP01
 SG_ HVESP01_CellBalance_192_1 m23: 15|1@1+ (1,0) [0|1] ""  HVESP01
 SG_ multiplexorcb_1 M: 0|8@1+ (1,0) [0|255] ""  HVESP01

BO_ 2499743334 HVESP01_CellBalance_2: 8 HVESP01
 SG_ HVESP01_CellBalance_01_2 m0: 8|1@1+ (1,0) [0|1] ""  HVESP01
 SG_ HVESP01_CellBalance_02_2 m0: 9|1@1+ (1,0) [0|1] ""  HVESP01
 SG_ HVESP01_CellBalance_03_2 m0: 10|1@1+ (1,0) [0|1] ""  HVESP01
 SG_ HVESP01_CellBalance_04_2 m0: 11|1@1+ (1,0) [0|1] ""  HVESP01
 SG_ HVESP01_CellBalance_05_2 m0: 12|1@1+ (1,0) [0|1] ""  HVESP01
 SG_ HVESP01_CellBalance_06_2 m0: 13|1@1+ (1,0) [0|1] ""  HVESP01
 SG_ HVESP01_CellBalance_07_2 m0: 14|1@1+ (1,0) [0|1] ""  HVESP01
 SG_ HVESP01_CellBalance_08_2 m0: 15|1@1+ (1,0) [0|1] ""  HVESP01
 SG_ HVESP01_CellBalance_09_2 m1: 8|1@1+ (1,0) [0|1] ""  HVESP01
 SG_ HVESP01_CellBalance_10_2 m1: 9|1@1+ (1,0) [0|1] ""  HVESP01
 SG_ HVESP01_CellBalance_11_2 m1: 10|1@1+ (1,0) [0|1] ""  HVESP01
 SG_ HVESP01_CellBalance_12_2 m1: 11|1@1+ (1,0) [0|1] ""  HVESP01
 SG_ HVESP01_CellBalance_13_2 m1: 12|1@1+ (1,0) [0|1] ""  HVESP01
 SG_ HVESP01_CellBalance_14_2 m1: 13|1@1+ (1,0) [0|1] ""  HVESP01
 SG_ HVESP01_CellBalance_15_2 m1: 14|1@1+ (1,0) [0|1] ""  HVESP01
 SG_ HVESP01_CellBalance_16_2 m1: 15|1@1+ (1,0) [0|1] ""  HVESP01
 SG_ HVESP01_CellBalance_17_2 m2: 8|1@1+ (1,0) [0|1] ""  HVESP01
 SG_ HVESP01_CellBalance_18_2 m2: 9|1@1+ (1,0) [0|1] ""  HVESP01
 SG_ HVESP01_CellBalance_19_2 m2: 10|1@1+ (1,0) [0|1] ""  HVESP01
 SG_ HVESP01_CellBalance_20_2 m2: 11|1@1+ (1,0) [0|1] ""  HVESP01
 SG_ HVESP01_CellBalance_21_2 m2: 12|1@1+ (1,0) [0|1] ""  HVESP01
 SG_ HVESP01_CellBalance_22_2 m2: 13|1@1+ (1,0) [0|1] ""  HVESP01
 SG_ HVESP01_CellBalance_23_2 m2: 14|1@1+ (1,0) [0|1] ""  HVESP01
 SG_ HVESP01_CellBalance_24_2 m2: 15|1@1+ (1,0) [0|1] ""  HVESP01
 SG_ HVESP01_CellBalance_25_2 m3: 8|1@1+ (1,0) [0|1] ""  HVESP01
 SG_ HVESP01_CellBalance_26_2 m3: 9|1@1+ (1,0) [0|1] ""  HVESP01
 SG_ HVESP01_CellBalance_27_2 m3: 10|1@1+ (1,0) [0|1] ""  HVESP01
 SG_ HVESP01_CellBalance_28_2 m3: 11|1@1+ (1,0) [0|1] ""  HVESP01
 SG_ HVESP01_CellBalance_29_2 m3: 12|1@1+ (1,0) [0|1] ""  HVESP01
 SG_ HVESP01_CellBalance_30_2 m3: 13|1@1+ (1,0) [0|1] ""  HVESP01
 SG_ HVESP01_CellBalance_31_2 m3: 14|1@1+ (1,0) [0|1] ""  HVESP01
 SG_ HVESP01_CellBalance_32_2 m3: 15|1@1+ (1,0) [0|1] ""  HVESP01
 SG_ HVESP01_CellBalance_33_2 m4: 8|1@1+ (1,0) [0|1] ""  HVESP01
 SG_ HVESP01_CellBalance_34_2 m4: 9|1@1+ (1,0) [0|1] ""  HVESP01
 SG_ HVESP01_CellBalance_35_2 m4: 10|1@1+ (1,0) [0|1] ""  HVESP01
 SG_ HVESP01_CellBalance_36_2 m4: 11|1@1+ (1,0) [0|1] ""  HVESP01
 SG_ HVESP01_CellBalance_37_2 m4: 12|1@1+ (1,0) [0|1] ""  HVESP01
 SG_ HVESP01_CellBalance_38_2 m4: 13|1@1+ (1,0) [0|1] ""  HVESP01
 SG_ HVESP01_CellBalance_39_2 m4: 14|1@1+ (1,0) [0|1] ""  HVESP01
 SG_ HVESP01_CellBalance_40_2 m4: 15|1@1+ (1,0) [0|1] ""  HVESP01
 SG_ HVESP01_CellBalance_41_2 m5: 8|1@1+ (1,0) [0|1] ""  HVESP01
 SG_ HVESP01_CellBalance_42_2 m5: 9|1@1+ (1,0) [0|1] ""  HVESP01
 SG_ HVESP01_CellBalance_43_2 m5: 10|1@1+ (1,0) [0|1] ""  HVESP01
 SG_ HVESP01_CellBalance_44_2 m5: 11|1@1+ (1,0) [0|1] ""  HVESP01
 SG_ HVESP01_CellBalance_45_2 m5: 12|1@1+ (1,0) [0|1] ""  HVESP01
 SG_ HVESP01_CellBalance_46_2 m5: 13|1@1+ (1,0) [0|1] ""  HVESP01
 SG_ HVESP01_CellBalance_47_2 m5: 14|1@1+ (1,0) [0|1] ""  HVESP01
 SG_ HVESP01_CellBalance_48_2 m5: 15|1@1+ (1,0) [0|1] ""  HVESP01
 SG_ HVESP01_CellBalance_49_2 m6: 8|1@1+ (1,0) [0|1] ""  HVESP01
 SG_ HVESP01_CellBalance_50_2 m6: 9|1@1+ (1,0) [0|1] ""  HVESP01
 SG_ HVESP01_CellBalance_51_2 m6: 10|1@1+ (1,0) [0|1] ""  HVESP01
 SG_ HVESP01_CellBalance_52_2 m6: 11|1@1+ (1,0) [0|1] ""  HVESP01
 SG_ HVESP01_CellBalance_53_2 m6: 12|1@1+ (1,0) [0|1] ""  HVESP01
 SG_ HVESP01_CellBalance_54_2 m6: 13|1@1+ (1,0) [0|1] ""  HVESP01
 SG_ HVESP01_CellBalance_55_2 m6: 14|1@1+ (1,0) [0|1] ""  HVESP01
 SG_ HVESP01_CellBalance_56_2 m6: 15|1@1+ (1,0) [0|1] ""  HVESP01
 SG_ HVESP01_CellBalance_57_2 m7: 8|1@1+ (1,0) [0|1] ""  HVESP01
 SG_ HVESP01_CellBalance_58_2 m7: 9|1@1+ (1,0) [0|1] ""  HVESP01
 SG_ HVESP01_CellBalance_59_2 m7: 10|1@1+ (1,0) [0|1] ""  HVESP01
 SG_ HVESP01_CellBalance_60_2 m7: 11|1@1+ (1,0) [0|1] ""  HVESP01
 SG_ HVESP01_CellBalance_61_2 m7: 12|1@1+ (1,0) [0|1] ""  HVESP01
 SG_ HVESP01_CellBalance_62_2 m7: 13|1@1+ (1,0) [0|1] ""  HVESP01
 SG_ HVESP01_CellBalance_63_2 m7: 14|1@1+ (1,0) [0|1] ""  HVESP01
 SG_ HVESP01_CellBalance_64_2 m7: 15|1@1+ (1,0) [0|1] ""  HVESP01
 SG_ HVESP01_CellBalance_65_2 m8: 8|1@1+ (1,0) [0|1] ""  HVESP01
 SG_ HVESP01_CellBalance_66_2 m8: 9|1@1+ (1,0) [0|1] ""  HVESP01
 SG_ HVESP01_CellBalance_67_2 m8: 10|1@1+ (1,0) [0|1] ""  HVESP01
 SG_ HVESP01_CellBalance_68_2 m8: 11|1@1+ (1,0) [0|1] ""  HVESP01
 SG_ HVESP01_CellBalance_69_2 m8: 12|1@1+ (1,0) [0|1] ""  HVESP01
 SG_ HVESP01_CellBalance_70_2 m8: 13|1@1+ (1,0) [0|1] ""  HVESP01
 SG_ HVESP01_CellBalance_71_2 m8: 14|1@1+ (1,0) [0|1] ""  HVESP01
 SG_ HVESP01_CellBalance_72_2 m8: 15|1@1+ (1,0) [0|1] ""  HVESP01
 SG_ HVESP01_CellBalance_73_2 m9: 8|1@1+ (1,0) [0|1] ""  HVESP01
 SG_ HVESP01_CellBalance_74_2 m9: 9|1@1+ (1,0) [0|1] ""  HVESP01
 SG_ HVESP01_CellBalance_75_2 m9: 10|1@1+ (1,0) [0|1] ""  HVESP01
 SG_ HVESP01_CellBalance_76_2 m9: 11|1@1+ (1,0) [0|1] ""  HVESP01
 SG_ HVESP01_CellBalance_77_2 m9: 12|1@1+ (1,0) [0|1] ""  HVESP01
 SG_ HVESP01_CellBalance_78_2 m9: 13|1@1+ (1,0) [0|1] ""  HVESP01
 SG_ HVESP01_CellBalance_79_2 m9: 14|1@1+ (1,0) [0|1] ""  HVESP01
 SG_ HVESP01_CellBalance_80_2 m9: 15|1@1+ (1,0) [0|1] ""  HVESP01
 SG_ HVESP01_CellBalance_81_2 m10: 8|1@1+ (1,0) [0|1] ""  HVESP01
 SG_ HVESP01_CellBalance_82_2 m10: 9|1@1+ (1,0) [0|1] ""  HVESP01
 SG_ HVESP01_CellBalance_83_2 m10: 10|1@1+ (1,0) [0|1] ""  HVESP01
 SG_ HVESP01_CellBalance_84_2 m10: 11|1@1+ (1,0) [0|1] ""  HVESP01
 SG_ HVESP01_CellBalance_85_2 m10: 12|1@1+ (1,0) [0|1] ""  HVESP01
 SG_ HVESP01_CellBalance_86_2 m10: 13|1@1+ (1,0) [0|1] ""  HVESP01
 SG_ HVESP01_CellBalance_87_2 m10: 14|1@1+ (1,0) [0|1] ""  HVESP01
 SG_ HVESP01_CellBalance_88_2 m10: 15|1@1+ (1,0) [0|1] ""  HVESP01
 SG_ HVESP01_CellBalance_89_2 m11: 8|1@1+ (1,0) [0|1] ""  HVESP01
 SG_ HVESP01_CellBalance_90_2 m11: 9|1@1+ (1,0) [0|1] ""  HVESP01
 SG_ HVESP01_CellBalance_91_2 m11: 10|1@1+ (1,0) [0|1] ""  HVESP01
 SG_ HVESP01_CellBalance_92_2 m11: 11|1@1+ (1,0) [0|1] ""  HVESP01
 SG_ HVESP01_CellBalance_93_2 m11: 12|1@1+ (1,0) [0|1] ""  HVESP01
 SG_ HVESP01_CellBalance_94_2 m11: 13|1@1+ (1,0) [0|1] ""  HVESP01
 SG_ HVESP01_CellBalance_95_2 m11: 14|1@1+ (1,0) [0|1] ""  HVESP01
 SG_ HVESP01_CellBalance_96_2 m11: 15|1@1+ (1,0) [0|1] ""  HVESP01
 SG_ HVESP01_CellBalance_97_2 m12: 8|1@1+ (1,0) [0|1] ""  HVESP01
 SG_ HVESP01_CellBalance_98_2 m12: 9|1@1+ (1,0) [0|1] ""  HVESP01
 SG_ HVESP01_CellBalance_99_2 m12: 10|1@1+ (1,0) [0|1] ""  HVESP01
 SG_ HVESP01_CellBalance_100_2 m12: 11|1@1+ (1,0) [0|1] ""  HVESP01
 SG_ HVESP01_CellBalance_101_2 m12: 12|1@1+ (1,0) [0|1] ""  HVESP01
 SG_ HVESP01_CellBalance_102_2 m12: 13|1@1+ (1,0) [0|1] ""  HVESP01
 SG_ HVESP01_CellBalance_103_2 m12: 14|1@1+ (1,0) [0|1] ""  HVESP01
 SG_ HVESP01_CellBalance_104_2 m12: 15|1@1+ (1,0) [0|1] ""  HVESP01
 SG_ HVESP01_CellBalance_105_2 m13: 8|1@1+ (1,0) [0|1] ""  HVESP01
 SG_ HVESP01_CellBalance_106_2 m13: 9|1@1+ (1,0) [0|1] ""  HVESP01
 SG_ HVESP01_CellBalance_107_2 m13: 10|1@1+ (1,0) [0|1] ""  HVESP01
 SG_ HVESP01_CellBalance_108_2 m13: 11|1@1+ (1,0) [0|1] ""  HVESP01
 SG_ HVESP01_CellBalance_109_2 m13: 12|1@1+ (1,0) [0|1] ""  HVESP01
 SG_ HVESP01_CellBalance_110_2 m13: 13|1@1+ (1,0) [0|1] ""  HVESP01
 SG_ HVESP01_CellBalance_111_2 m13: 14|1@1+ (1,0) [0|1] ""  HVESP01
 SG_ HVESP01_CellBalance_112_2 m13: 15|1@1+ (1,0) [0|1] ""  HVESP01
 SG_ HVESP01_CellBalance_113_2 m14: 8|1@1+ (1,0) [0|1] ""  HVESP01
 SG_ HVESP01_CellBalance_114_2 m14: 9|1@1+ (1,0) [0|1] ""  HVESP01
 SG_ HVESP01_CellBalance_115_2 m14: 10|1@1+ (1,0) [0|1] ""  HVESP01
 SG_ HVESP01_CellBalance_116_2 m14: 11|1@1+ (1,0) [0|1] ""  HVESP01
 SG_ HVESP01_CellBalance_117_2 m14: 12|1@1+ (1,0) [0|1] ""  HVESP01
 SG_ HVESP01_CellBalance_118_2 m14: 13|1@1+ (1,0) [0|1] ""  HVESP01
 SG_ HVESP01_CellBalance_119_2 m14: 14|1@1+ (1,0) [0|1] ""  HVESP01
 SG_ HVESP01_CellBalance_120_2 m14: 15|1@1+ (1,0) [0|1] ""  HVESP01
 SG_ HVESP01_CellBalance_121_2 m15: 8|1@1+ (1,0) [0|1] ""  HVESP01
 SG_ HVESP01_CellBalance_122_2 m15: 9|1@1+ (1,0) [0|1] ""  HVESP01
 SG_ HVESP01_CellBalance_123_2 m15: 10|1@1+ (1,0) [0|1] ""  HVESP01
 SG_ HVESP01_CellBalance_124_2 m15: 11|1@1+ (1,0) [0|1] ""  HVESP01
 SG_ HVESP01_CellBalance_125_2 m15: 12|1@1+ (1,0) [0|1] ""  HVESP01
 SG_ HVESP01_CellBalance_126_2 m15: 13|1@1+ (1,0) [0|1] ""  HVESP01
 SG_ HVESP01_CellBalance_127_2 m15: 14|1@1+ (1,0) [0|1] ""  HVESP01
 SG_ HVESP01_CellBalance_128_2 m15: 15|1@1+ (1,0) [0|1] ""  HVESP01
 SG_ HVESP01_CellBalance_129_2 m16: 8|1@1+ (1,0) [0|1] ""  HVESP01
 SG_ HVESP01_CellBalance_130_2 m16: 9|1@1+ (1,0) [0|1] ""  HVESP01
 SG_ HVESP01_CellBalance_131_2 m16: 10|1@1+ (1,0) [0|1] ""  HVESP01
 SG_ HVESP01_CellBalance_132_2 m16: 11|1@1+ (1,0) [0|1] ""  HVESP01
 SG_ HVESP01_CellBalance_133_2 m16: 12|1@1+ (1,0) [0|1] ""  HVESP01
 SG_ HVESP01_CellBalance_134_2 m16: 13|1@1+ (1,0) [0|1] ""  HVESP01
 SG_ HVESP01_CellBalance_135_2 m16: 14|1@1+ (1,0) [0|1] ""  HVESP01
 SG_ HVESP01_CellBalance_136_2 m16: 15|1@1+ (1,0) [0|1] ""  HVESP01
 SG_ HVESP01_CellBalance_137_2 m17: 8|1@1+ (1,0) [0|1] ""  HVESP01
 SG_ HVESP01_CellBalance_138_2 m17: 9|1@1+ (1,0) [0|1] ""  HVESP01
 SG_ HVESP01_CellBalance_139_2 m17: 10|1@1+ (1,0) [0|1] ""  HVESP01
 SG_ HVESP01_CellBalance_140_2 m17: 11|1@1+ (1,0) [0|1] ""  HVESP01
 SG_ HVESP01_CellBalance_141_2 m17: 12|1@1+ (1,0) [0|1] ""  HVESP01
 SG_ HVESP01_CellBalance_142_2 m17: 13|1@1+ (1,0) [0|1] ""  HVESP01
 SG_ HVESP01_CellBalance_143_2 m17: 14|1@1+ (1,0) [0|1] ""  HVESP01
 SG_ HVESP01_CellBalance_144_2 m17: 15|1@1+ (1,0) [0|1] ""  HVESP01
 SG_ HVESP01_CellBalance_145_2 m18: 8|1@1+ (1,0) [0|1] ""  HVESP01
 SG_ HVESP01_CellBalance_146_2 m18: 9|1@1+ (1,0) [0|1] ""  HVESP01
 SG_ HVESP01_CellBalance_147_2 m18: 10|1@1+ (1,0) [0|1] ""  HVESP01
 SG_ HVESP01_CellBalance_148_2 m18: 11|1@1+ (1,0) [0|1] ""  HVESP01
 SG_ HVESP01_CellBalance_149_2 m18: 12|1@1+ (1,0) [0|1] ""  HVESP01
 SG_ HVESP01_CellBalance_150_2 m18: 13|1@1+ (1,0) [0|1] ""  HVESP01
 SG_ HVESP01_CellBalance_151_2 m18: 14|1@1+ (1,0) [0|1] ""  HVESP01
 SG_ HVESP01_CellBalance_152_2 m18: 15|1@1+ (1,0) [0|1] ""  HVESP01
 SG_ HVESP01_CellBalance_153_2 m19: 8|1@1+ (1,0) [0|1] ""  HVESP01
 SG_ HVESP01_CellBalance_154_2 m19: 9|1@1+ (1,0) [0|1] ""  HVESP01
 SG_ HVESP01_CellBalance_155_2 m19: 10|1@1+ (1,0) [0|1] ""  HVESP01
 SG_ HVESP01_CellBalance_156_2 m19: 11|1@1+ (1,0) [0|1] ""  HVESP01
 SG_ HVESP01_CellBalance_157_2 m19: 12|1@1+ (1,0) [0|1] ""  HVESP01
 SG_ HVESP01_CellBalance_158_2 m19: 13|1@1+ (1,0) [0|1] ""  HVESP01
 SG_ HVESP01_CellBalance_159_2 m19: 14|1@1+ (1,0) [0|1] ""  HVESP01
 SG_ HVESP01_CellBalance_160_2 m19: 15|1@1+ (1,0) [0|1] ""  HVESP01
 SG_ HVESP01_CellBalance_161_2 m20: 8|1@1+ (1,0) [0|1] ""  HVESP01
 SG_ HVESP01_CellBalance_162_2 m20: 9|1@1+ (1,0) [0|1] ""  HVESP01
 SG_ HVESP01_CellBalance_163_2 m20: 10|1@1+ (1,0) [0|1] ""  HVESP01
 SG_ HVESP01_CellBalance_164_2 m20: 11|1@1+ (1,0) [0|1] ""  HVESP01
 SG_ HVESP01_CellBalance_165_2 m20: 12|1@1+ (1,0) [0|1] ""  HVESP01
 SG_ HVESP01_CellBalance_166_2 m20: 13|1@1+ (1,0) [0|1] ""  HVESP01
 SG_ HVESP01_CellBalance_167_2 m20: 14|1@1+ (1,0) [0|1] ""  HVESP01
 SG_ HVESP01_CellBalance_168_2 m20: 15|1@1+ (1,0) [0|1] ""  HVESP01
 SG_ HVESP01_CellBalance_169_2 m21: 8|1@1+ (1,0) [0|1] ""  HVESP01
 SG_ HVESP01_CellBalance_170_2 m21: 9|1@1+ (1,0) [0|1] ""  HVESP01
 SG_ HVESP01_CellBalance_171_2 m21: 10|1@1+ (1,0) [0|1] ""  HVESP01
 SG_ HVESP01_CellBalance_172_2 m21: 11|1@1+ (1,0) [0|1] ""  HVESP01
 SG_ HVESP01_CellBalance_173_2 m21: 12|1@1+ (1,0) [0|1] ""  HVESP01
 SG_ HVESP01_CellBalance_174_2 m21: 13|1@1+ (1,0) [0|1] ""  HVESP01
 SG_ HVESP01_CellBalance_175_2 m21: 14|1@1+ (1,0) [0|1] ""  HVESP01
 SG_ HVESP01_CellBalance_176_2 m21: 15|1@1+ (1,0) [0|1] ""  HVESP01
 SG_ HVESP01_CellBalance_177_2 m22: 8|1@1+ (1,0) [0|1] ""  HVESP01
 SG_ HVESP01_CellBalance_178_2 m22: 9|1@1+ (1,0) [0|1] ""  HVESP01
 SG_ HVESP01_CellBalance_179_2 m22: 10|1@1+ (1,0) [0|1] ""  HVESP01
 SG_ HVESP01_CellBalance_180_2 m22: 11|1@1+ (1,0) [0|1] ""  HVESP01
 SG_ HVESP01_CellBalance_181_2 m22: 12|1@1+ (1,0) [0|1] ""  HVESP01
 SG_ HVESP01_CellBalance_182_2 m22: 13|1@1+ (1,0) [0|1] ""  HVESP01
 SG_ HVESP01_CellBalance_183_2 m22: 14|1@1+ (1,0) [0|1] ""  HVESP01
 SG_ HVESP01_CellBalance_184_2 m22: 15|1@1+ (1,0) [0|1] ""  HVESP01
 SG_ HVESP01_CellBalance_185_2 m23: 8|1@1+ (1,0) [0|1] ""  HVESP01
 SG_ HVESP01_CellBalance_186_2 m23: 9|1@1+ (1,0) [0|1] ""  HVESP01
 SG_ HVESP01_CellBalance_187_2 m23: 10|1@1+ (1,0) [0|1] ""  HVESP01
 SG_ HVESP01_CellBalance_188_2 m23: 11|1@1+ (1,0) [0|1] ""  HVESP01
 SG_ HVESP01_CellBalance_189_2 m23: 12|1@1+ (1,0) [0|1] ""  HVESP01
 SG_ HVESP01_CellBalance_190_2 m23: 13|1@1+ (1,0) [0|1] ""  HVESP01
 SG_ HVESP01_CellBalance_191_2 m23: 14|1@1+ (1,0) [0|1] ""  HVESP01
 SG_ HVESP01_CellBalance_192_2 m23: 15|1@1+ (1,0) [0|1] ""  HVESP01
 SG_ multiplexorcb_2 M: 0|8@1+ (1,0) [0|255] ""  HVESP01

BO_ 2499743335 HVESP01_CellBalance_3: 8 HVESP01
 SG_ HVESP01_CellBalance_01_3 m0: 8|1@1+ (1,0) [0|1] ""  HVESP01
 SG_ HVESP01_CellBalance_02_3 m0: 9|1@1+ (1,0) [0|1] ""  HVESP01
 SG_ HVESP01_CellBalance_03_3 m0: 10|1@1+ (1,0) [0|1] ""  HVESP01
 SG_ HVESP01_CellBalance_04_3 m0: 11|1@1+ (1,0) [0|1] ""  HVESP01
 SG_ HVESP01_CellBalance_05_3 m0: 12|1@1+ (1,0) [0|1] ""  HVESP01
 SG_ HVESP01_CellBalance_06_3 m0: 13|1@1+ (1,0) [0|1] ""  HVESP01
 SG_ HVESP01_CellBalance_07_3 m0: 14|1@1+ (1,0) [0|1] ""  HVESP01
 SG_ HVESP01_CellBalance_08_3 m0: 15|1@1+ (1,0) [0|1] ""  HVESP01
 SG_ HVESP01_CellBalance_09_3 m1: 8|1@1+ (1,0) [0|1] ""  HVESP01
 SG_ HVESP01_CellBalance_10_3 m1: 9|1@1+ (1,0) [0|1] ""  HVESP01
 SG_ HVESP01_CellBalance_11_3 m1: 10|1@1+ (1,0) [0|1] ""  HVESP01
 SG_ HVESP01_CellBalance_12_3 m1: 11|1@1+ (1,0) [0|1] ""  HVESP01
 SG_ HVESP01_CellBalance_13_3 m1: 12|1@1+ (1,0) [0|1] ""  HVESP01
 SG_ HVESP01_CellBalance_14_3 m1: 13|1@1+ (1,0) [0|1] ""  HVESP01
 SG_ HVESP01_CellBalance_15_3 m1: 14|1@1+ (1,0) [0|1] ""  HVESP01
 SG_ HVESP01_CellBalance_16_3 m1: 15|1@1+ (1,0) [0|1] ""  HVESP01
 SG_ HVESP01_CellBalance_17_3 m2: 8|1@1+ (1,0) [0|1] ""  HVESP01
 SG_ HVESP01_CellBalance_18_3 m2: 9|1@1+ (1,0) [0|1] ""  HVESP01
 SG_ HVESP01_CellBalance_19_3 m2: 10|1@1+ (1,0) [0|1] ""  HVESP01
 SG_ HVESP01_CellBalance_20_3 m2: 11|1@1+ (1,0) [0|1] ""  HVESP01
 SG_ HVESP01_CellBalance_21_3 m2: 12|1@1+ (1,0) [0|1] ""  HVESP01
 SG_ HVESP01_CellBalance_22_3 m2: 13|1@1+ (1,0) [0|1] ""  HVESP01
 SG_ HVESP01_CellBalance_23_3 m2: 14|1@1+ (1,0) [0|1] ""  HVESP01
 SG_ HVESP01_CellBalance_24_3 m2: 15|1@1+ (1,0) [0|1] ""  HVESP01
 SG_ HVESP01_CellBalance_25_3 m3: 8|1@1+ (1,0) [0|1] ""  HVESP01
 SG_ HVESP01_CellBalance_26_3 m3: 9|1@1+ (1,0) [0|1] ""  HVESP01
 SG_ HVESP01_CellBalance_27_3 m3: 10|1@1+ (1,0) [0|1] ""  HVESP01
 SG_ HVESP01_CellBalance_28_3 m3: 11|1@1+ (1,0) [0|1] ""  HVESP01
 SG_ HVESP01_CellBalance_29_3 m3: 12|1@1+ (1,0) [0|1] ""  HVESP01
 SG_ HVESP01_CellBalance_30_3 m3: 13|1@1+ (1,0) [0|1] ""  HVESP01
 SG_ HVESP01_CellBalance_31_3 m3: 14|1@1+ (1,0) [0|1] ""  HVESP01
 SG_ HVESP01_CellBalance_32_3 m3: 15|1@1+ (1,0) [0|1] ""  HVESP01
 SG_ HVESP01_CellBalance_33_3 m4: 8|1@1+ (1,0) [0|1] ""  HVESP01
 SG_ HVESP01_CellBalance_34_3 m4: 9|1@1+ (1,0) [0|1] ""  HVESP01
 SG_ HVESP01_CellBalance_35_3 m4: 10|1@1+ (1,0) [0|1] ""  HVESP01
 SG_ HVESP01_CellBalance_36_3 m4: 11|1@1+ (1,0) [0|1] ""  HVESP01
 SG_ HVESP01_CellBalance_37_3 m4: 12|1@1+ (1,0) [0|1] ""  HVESP01
 SG_ HVESP01_CellBalance_38_3 m4: 13|1@1+ (1,0) [0|1] ""  HVESP01
 SG_ HVESP01_CellBalance_39_3 m4: 14|1@1+ (1,0) [0|1] ""  HVESP01
 SG_ HVESP01_CellBalance_40_3 m4: 15|1@1+ (1,0) [0|1] ""  HVESP01
 SG_ HVESP01_CellBalance_41_3 m5: 8|1@1+ (1,0) [0|1] ""  HVESP01
 SG_ HVESP01_CellBalance_42_3 m5: 9|1@1+ (1,0) [0|1] ""  HVESP01
 SG_ HVESP01_CellBalance_43_3 m5: 10|1@1+ (1,0) [0|1] ""  HVESP01
 SG_ HVESP01_CellBalance_44_3 m5: 11|1@1+ (1,0) [0|1] ""  HVESP01
 SG_ HVESP01_CellBalance_45_3 m5: 12|1@1+ (1,0) [0|1] ""  HVESP01
 SG_ HVESP01_CellBalance_46_3 m5: 13|1@1+ (1,0) [0|1] ""  HVESP01
 SG_ HVESP01_CellBalance_47_3 m5: 14|1@1+ (1,0) [0|1] ""  HVESP01
 SG_ HVESP01_CellBalance_48_3 m5: 15|1@1+ (1,0) [0|1] ""  HVESP01
 SG_ HVESP01_CellBalance_49_3 m6: 8|1@1+ (1,0) [0|1] ""  HVESP01
 SG_ HVESP01_CellBalance_50_3 m6: 9|1@1+ (1,0) [0|1] ""  HVESP01
 SG_ HVESP01_CellBalance_51_3 m6: 10|1@1+ (1,0) [0|1] ""  HVESP01
 SG_ HVESP01_CellBalance_52_3 m6: 11|1@1+ (1,0) [0|1] ""  HVESP01
 SG_ HVESP01_CellBalance_53_3 m6: 12|1@1+ (1,0) [0|1] ""  HVESP01
 SG_ HVESP01_CellBalance_54_3 m6: 13|1@1+ (1,0) [0|1] ""  HVESP01
 SG_ HVESP01_CellBalance_55_3 m6: 14|1@1+ (1,0) [0|1] ""  HVESP01
 SG_ HVESP01_CellBalance_56_3 m6: 15|1@1+ (1,0) [0|1] ""  HVESP01
 SG_ HVESP01_CellBalance_57_3 m7: 8|1@1+ (1,0) [0|1] ""  HVESP01
 SG_ HVESP01_CellBalance_58_3 m7: 9|1@1+ (1,0) [0|1] ""  HVESP01
 SG_ HVESP01_CellBalance_59_3 m7: 10|1@1+ (1,0) [0|1] ""  HVESP01
 SG_ HVESP01_CellBalance_60_3 m7: 11|1@1+ (1,0) [0|1] ""  HVESP01
 SG_ HVESP01_CellBalance_61_3 m7: 12|1@1+ (1,0) [0|1] ""  HVESP01
 SG_ HVESP01_CellBalance_62_3 m7: 13|1@1+ (1,0) [0|1] ""  HVESP01
 SG_ HVESP01_CellBalance_63_3 m7: 14|1@1+ (1,0) [0|1] ""  HVESP01
 SG_ HVESP01_CellBalance_64_3 m7: 15|1@1+ (1,0) [0|1] ""  HVESP01
 SG_ HVESP01_CellBalance_65_3 m8: 8|1@1+ (1,0) [0|1] ""  HVESP01
 SG_ HVESP01_CellBalance_66_3 m8: 9|1@1+ (1,0) [0|1] ""  HVESP01
 SG_ HVESP01_CellBalance_67_3 m8: 10|1@1+ (1,0) [0|1] ""  HVESP01
 SG_ HVESP01_CellBalance_68_3 m8: 11|1@1+ (1,0) [0|1] ""  HVESP01
 SG_ HVESP01_CellBalance_69_3 m8: 12|1@1+ (1,0) [0|1] ""  HVESP01
 SG_ HVESP01_CellBalance_70_3 m8: 13|1@1+ (1,0) [0|1] ""  HVESP01
 SG_ HVESP01_CellBalance_71_3 m8: 14|1@1+ (1,0) [0|1] ""  HVESP01
 SG_ HVESP01_CellBalance_72_3 m8: 15|1@1+ (1,0) [0|1] ""  HVESP01
 SG_ HVESP01_CellBalance_73_3 m9: 8|1@1+ (1,0) [0|1] ""  HVESP01
 SG_ HVESP01_CellBalance_74_3 m9: 9|1@1+ (1,0) [0|1] ""  HVESP01
 SG_ HVESP01_CellBalance_75_3 m9: 10|1@1+ (1,0) [0|1] ""  HVESP01
 SG_ HVESP01_CellBalance_76_3 m9: 11|1@1+ (1,0) [0|1] ""  HVESP01
 SG_ HVESP01_CellBalance_77_3 m9: 12|1@1+ (1,0) [0|1] ""  HVESP01
 SG_ HVESP01_CellBalance_78_3 m9: 13|1@1+ (1,0) [0|1] ""  HVESP01
 SG_ HVESP01_CellBalance_79_3 m9: 14|1@1+ (1,0) [0|1] ""  HVESP01
 SG_ HVESP01_CellBalance_80_3 m9: 15|1@1+ (1,0) [0|1] ""  HVESP01
 SG_ HVESP01_CellBalance_81_3 m10: 8|1@1+ (1,0) [0|1] ""  HVESP01
 SG_ HVESP01_CellBalance_82_3 m10: 9|1@1+ (1,0) [0|1] ""  HVESP01
 SG_ HVESP01_CellBalance_83_3 m10: 10|1@1+ (1,0) [0|1] ""  HVESP01
 SG_ HVESP01_CellBalance_84_3 m10: 11|1@1+ (1,0) [0|1] ""  HVESP01
 SG_ HVESP01_CellBalance_85_3 m10: 12|1@1+ (1,0) [0|1] ""  HVESP01
 SG_ HVESP01_CellBalance_86_3 m10: 13|1@1+ (1,0) [0|1] ""  HVESP01
 SG_ HVESP01_CellBalance_87_3 m10: 14|1@1+ (1,0) [0|1] ""  HVESP01
 SG_ HVESP01_CellBalance_88_3 m10: 15|1@1+ (1,0) [0|1] ""  HVESP01
 SG_ HVESP01_CellBalance_89_3 m11: 8|1@1+ (1,0) [0|1] ""  HVESP01
 SG_ HVESP01_CellBalance_90_3 m11: 9|1@1+ (1,0) [0|1] ""  HVESP01
 SG_ HVESP01_CellBalance_91_3 m11: 10|1@1+ (1,0) [0|1] ""  HVESP01
 SG_ HVESP01_CellBalance_92_3 m11: 11|1@1+ (1,0) [0|1] ""  HVESP01
 SG_ HVESP01_CellBalance_93_3 m11: 12|1@1+ (1,0) [0|1] ""  HVESP01
 SG_ HVESP01_CellBalance_94_3 m11: 13|1@1+ (1,0) [0|1] ""  HVESP01
 SG_ HVESP01_CellBalance_95_3 m11: 14|1@1+ (1,0) [0|1] ""  HVESP01
 SG_ HVESP01_CellBalance_96_3 m11: 15|1@1+ (1,0) [0|1] ""  HVESP01
 SG_ HVESP01_CellBalance_97_3 m12: 8|1@1+ (1,0) [0|1] ""  HVESP01
 SG_ HVESP01_CellBalance_98_3 m12: 9|1@1+ (1,0) [0|1] ""  HVESP01
 SG_ HVESP01_CellBalance_99_3 m12: 10|1@1+ (1,0) [0|1] ""  HVESP01
 SG_ HVESP01_CellBalance_100_3 m12: 11|1@1+ (1,0) [0|1] ""  HVESP01
 SG_ HVESP01_CellBalance_101_3 m12: 12|1@1+ (1,0) [0|1] ""  HVESP01
 SG_ HVESP01_CellBalance_102_3 m12: 13|1@1+ (1,0) [0|1] ""  HVESP01
 SG_ HVESP01_CellBalance_103_3 m12: 14|1@1+ (1,0) [0|1] ""  HVESP01
 SG_ HVESP01_CellBalance_104_3 m12: 15|1@1+ (1,0) [0|1] ""  HVESP01
 SG_ HVESP01_CellBalance_105_3 m13: 8|1@1+ (1,0) [0|1] ""  HVESP01
 SG_ HVESP01_CellBalance_106_3 m13: 9|1@1+ (1,0) [0|1] ""  HVESP01
 SG_ HVESP01_CellBalance_107_3 m13: 10|1@1+ (1,0) [0|1] ""  HVESP01
 SG_ HVESP01_CellBalance_108_3 m13: 11|1@1+ (1,0) [0|1] ""  HVESP01
 SG_ HVESP01_CellBalance_109_3 m13: 12|1@1+ (1,0) [0|1] ""  HVESP01
 SG_ HVESP01_CellBalance_110_3 m13: 13|1@1+ (1,0) [0|1] ""  HVESP01
 SG_ HVESP01_CellBalance_111_3 m13: 14|1@1+ (1,0) [0|1] ""  HVESP01
 SG_ HVESP01_CellBalance_112_3 m13: 15|1@1+ (1,0) [0|1] ""  HVESP01
 SG_ HVESP01_CellBalance_113_3 m14: 8|1@1+ (1,0) [0|1] ""  HVESP01
 SG_ HVESP01_CellBalance_114_3 m14: 9|1@1+ (1,0) [0|1] ""  HVESP01
 SG_ HVESP01_CellBalance_115_3 m14: 10|1@1+ (1,0) [0|1] ""  HVESP01
 SG_ HVESP01_CellBalance_116_3 m14: 11|1@1+ (1,0) [0|1] ""  HVESP01
 SG_ HVESP01_CellBalance_117_3 m14: 12|1@1+ (1,0) [0|1] ""  HVESP01
 SG_ HVESP01_CellBalance_118_3 m14: 13|1@1+ (1,0) [0|1] ""  HVESP01
 SG_ HVESP01_CellBalance_119_3 m14: 14|1@1+ (1,0) [0|1] ""  HVESP01
 SG_ HVESP01_CellBalance_120_3 m14: 15|1@1+ (1,0) [0|1] ""  HVESP01
 SG_ HVESP01_CellBalance_121_3 m15: 8|1@1+ (1,0) [0|1] ""  HVESP01
 SG_ HVESP01_CellBalance_122_3 m15: 9|1@1+ (1,0) [0|1] ""  HVESP01
 SG_ HVESP01_CellBalance_123_3 m15: 10|1@1+ (1,0) [0|1] ""  HVESP01
 SG_ HVESP01_CellBalance_124_3 m15: 11|1@1+ (1,0) [0|1] ""  HVESP01
 SG_ HVESP01_CellBalance_125_3 m15: 12|1@1+ (1,0) [0|1] ""  HVESP01
 SG_ HVESP01_CellBalance_126_3 m15: 13|1@1+ (1,0) [0|1] ""  HVESP01
 SG_ HVESP01_CellBalance_127_3 m15: 14|1@1+ (1,0) [0|1] ""  HVESP01
 SG_ HVESP01_CellBalance_128_3 m15: 15|1@1+ (1,0) [0|1] ""  HVESP01
 SG_ HVESP01_CellBalance_129_3 m16: 8|1@1+ (1,0) [0|1] ""  HVESP01
 SG_ HVESP01_CellBalance_130_3 m16: 9|1@1+ (1,0) [0|1] ""  HVESP01
 SG_ HVESP01_CellBalance_131_3 m16: 10|1@1+ (1,0) [0|1] ""  HVESP01
 SG_ HVESP01_CellBalance_132_3 m16: 11|1@1+ (1,0) [0|1] ""  HVESP01
 SG_ HVESP01_CellBalance_133_3 m16: 12|1@1+ (1,0) [0|1] ""  HVESP01
 SG_ HVESP01_CellBalance_134_3 m16: 13|1@1+ (1,0) [0|1] ""  HVESP01
 SG_ HVESP01_CellBalance_135_3 m16: 14|1@1+ (1,0) [0|1] ""  HVESP01
 SG_ HVESP01_CellBalance_136_3 m16: 15|1@1+ (1,0) [0|1] ""  HVESP01
 SG_ HVESP01_CellBalance_137_3 m17: 8|1@1+ (1,0) [0|1] ""  HVESP01
 SG_ HVESP01_CellBalance_138_3 m17: 9|1@1+ (1,0) [0|1] ""  HVESP01
 SG_ HVESP01_CellBalance_139_3 m17: 10|1@1+ (1,0) [0|1] ""  HVESP01
 SG_ HVESP01_CellBalance_140_3 m17: 11|1@1+ (1,0) [0|1] ""  HVESP01
 SG_ HVESP01_CellBalance_141_3 m17: 12|1@1+ (1,0) [0|1] ""  HVESP01
 SG_ HVESP01_CellBalance_142_3 m17: 13|1@1+ (1,0) [0|1] ""  HVESP01
 SG_ HVESP01_CellBalance_143_3 m17: 14|1@1+ (1,0) [0|1] ""  HVESP01
 SG_ HVESP01_CellBalance_144_3 m17: 15|1@1+ (1,0) [0|1] ""  HVESP01
 SG_ HVESP01_CellBalance_145_3 m18: 8|1@1+ (1,0) [0|1] ""  HVESP01
 SG_ HVESP01_CellBalance_146_3 m18: 9|1@1+ (1,0) [0|1] ""  HVESP01
 SG_ HVESP01_CellBalance_147_3 m18: 10|1@1+ (1,0) [0|1] ""  HVESP01
 SG_ HVESP01_CellBalance_148_3 m18: 11|1@1+ (1,0) [0|1] ""  HVESP01
 SG_ HVESP01_CellBalance_149_3 m18: 12|1@1+ (1,0) [0|1] ""  HVESP01
 SG_ HVESP01_CellBalance_150_3 m18: 13|1@1+ (1,0) [0|1] ""  HVESP01
 SG_ HVESP01_CellBalance_151_3 m18: 14|1@1+ (1,0) [0|1] ""  HVESP01
 SG_ HVESP01_CellBalance_152_3 m18: 15|1@1+ (1,0) [0|1] ""  HVESP01
 SG_ HVESP01_CellBalance_153_3 m19: 8|1@1+ (1,0) [0|1] ""  HVESP01
 SG_ HVESP01_CellBalance_154_3 m19: 9|1@1+ (1,0) [0|1] ""  HVESP01
 SG_ HVESP01_CellBalance_155_3 m19: 10|1@1+ (1,0) [0|1] ""  HVESP01
 SG_ HVESP01_CellBalance_156_3 m19: 11|1@1+ (1,0) [0|1] ""  HVESP01
 SG_ HVESP01_CellBalance_157_3 m19: 12|1@1+ (1,0) [0|1] ""  HVESP01
 SG_ HVESP01_CellBalance_158_3 m19: 13|1@1+ (1,0) [0|1] ""  HVESP01
 SG_ HVESP01_CellBalance_159_3 m19: 14|1@1+ (1,0) [0|1] ""  HVESP01
 SG_ HVESP01_CellBalance_160_3 m19: 15|1@1+ (1,0) [0|1] ""  HVESP01
 SG_ HVESP01_CellBalance_161_3 m20: 8|1@1+ (1,0) [0|1] ""  HVESP01
 SG_ HVESP01_CellBalance_162_3 m20: 9|1@1+ (1,0) [0|1] ""  HVESP01
 SG_ HVESP01_CellBalance_163_3 m20: 10|1@1+ (1,0) [0|1] ""  HVESP01
 SG_ HVESP01_CellBalance_164_3 m20: 11|1@1+ (1,0) [0|1] ""  HVESP01
 SG_ HVESP01_CellBalance_165_3 m20: 12|1@1+ (1,0) [0|1] ""  HVESP01
 SG_ HVESP01_CellBalance_166_3 m20: 13|1@1+ (1,0) [0|1] ""  HVESP01
 SG_ HVESP01_CellBalance_167_3 m20: 14|1@1+ (1,0) [0|1] ""  HVESP01
 SG_ HVESP01_CellBalance_168_3 m20: 15|1@1+ (1,0) [0|1] ""  HVESP01
 SG_ HVESP01_CellBalance_169_3 m21: 8|1@1+ (1,0) [0|1] ""  HVESP01
 SG_ HVESP01_CellBalance_170_3 m21: 9|1@1+ (1,0) [0|1] ""  HVESP01
 SG_ HVESP01_CellBalance_171_3 m21: 10|1@1+ (1,0) [0|1] ""  HVESP01
 SG_ HVESP01_CellBalance_172_3 m21: 11|1@1+ (1,0) [0|1] ""  HVESP01
 SG_ HVESP01_CellBalance_173_3 m21: 12|1@1+ (1,0) [0|1] ""  HVESP01
 SG_ HVESP01_CellBalance_174_3 m21: 13|1@1+ (1,0) [0|1] ""  HVESP01
 SG_ HVESP01_CellBalance_175_3 m21: 14|1@1+ (1,0) [0|1] ""  HVESP01
 SG_ HVESP01_CellBalance_176_3 m21: 15|1@1+ (1,0) [0|1] ""  HVESP01
 SG_ HVESP01_CellBalance_177_3 m22: 8|1@1+ (1,0) [0|1] ""  HVESP01
 SG_ HVESP01_CellBalance_178_3 m22: 9|1@1+ (1,0) [0|1] ""  HVESP01
 SG_ HVESP01_CellBalance_179_3 m22: 10|1@1+ (1,0) [0|1] ""  HVESP01
 SG_ HVESP01_CellBalance_180_3 m22: 11|1@1+ (1,0) [0|1] ""  HVESP01
 SG_ HVESP01_CellBalance_181_3 m22: 12|1@1+ (1,0) [0|1] ""  HVESP01
 SG_ HVESP01_CellBalance_182_3 m22: 13|1@1+ (1,0) [0|1] ""  HVESP01
 SG_ HVESP01_CellBalance_183_3 m22: 14|1@1+ (1,0) [0|1] ""  HVESP01
 SG_ HVESP01_CellBalance_184_3 m22: 15|1@1+ (1,0) [0|1] ""  HVESP01
 SG_ HVESP01_CellBalance_185_3 m23: 8|1@1+ (1,0) [0|1] ""  HVESP01
 SG_ HVESP01_CellBalance_186_3 m23: 9|1@1+ (1,0) [0|1] ""  HVESP01
 SG_ HVESP01_CellBalance_187_3 m23: 10|1@1+ (1,0) [0|1] ""  HVESP01
 SG_ HVESP01_CellBalance_188_3 m23: 11|1@1+ (1,0) [0|1] ""  HVESP01
 SG_ HVESP01_CellBalance_189_3 m23: 12|1@1+ (1,0) [0|1] ""  HVESP01
 SG_ HVESP01_CellBalance_190_3 m23: 13|1@1+ (1,0) [0|1] ""  HVESP01
 SG_ HVESP01_CellBalance_191_3 m23: 14|1@1+ (1,0) [0|1] ""  HVESP01
 SG_ HVESP01_CellBalance_192_3 m23: 15|1@1+ (1,0) [0|1] ""  HVESP01
 SG_ multiplexorcb_3 M: 0|8@1+ (1,0) [0|255] ""  HVESP01

BO_ 2499743336 HVESP01_CellBalance_4: 8 HVESP01
 SG_ HVESP01_CellBalance_01_4 m0: 8|1@1+ (1,0) [0|1] ""  HVESP01
 SG_ HVESP01_CellBalance_02_4 m0: 9|1@1+ (1,0) [0|1] ""  HVESP01
 SG_ HVESP01_CellBalance_03_4 m0: 10|1@1+ (1,0) [0|1] ""  HVESP01
 SG_ HVESP01_CellBalance_04_4 m0: 11|1@1+ (1,0) [0|1] ""  HVESP01
 SG_ HVESP01_CellBalance_05_4 m0: 12|1@1+ (1,0) [0|1] ""  HVESP01
 SG_ HVESP01_CellBalance_06_4 m0: 13|1@1+ (1,0) [0|1] ""  HVESP01
 SG_ HVESP01_CellBalance_07_4 m0: 14|1@1+ (1,0) [0|1] ""  HVESP01
 SG_ HVESP01_CellBalance_08_4 m0: 15|1@1+ (1,0) [0|1] ""  HVESP01
 SG_ HVESP01_CellBalance_09_4 m1: 8|1@1+ (1,0) [0|1] ""  HVESP01
 SG_ HVESP01_CellBalance_10_4 m1: 9|1@1+ (1,0) [0|1] ""  HVESP01
 SG_ HVESP01_CellBalance_11_4 m1: 10|1@1+ (1,0) [0|1] ""  HVESP01
 SG_ HVESP01_CellBalance_12_4 m1: 11|1@1+ (1,0) [0|1] ""  HVESP01
 SG_ HVESP01_CellBalance_13_4 m1: 12|1@1+ (1,0) [0|1] ""  HVESP01
 SG_ HVESP01_CellBalance_14_4 m1: 13|1@1+ (1,0) [0|1] ""  HVESP01
 SG_ HVESP01_CellBalance_15_4 m1: 14|1@1+ (1,0) [0|1] ""  HVESP01
 SG_ HVESP01_CellBalance_16_4 m1: 15|1@1+ (1,0) [0|1] ""  HVESP01
 SG_ HVESP01_CellBalance_17_4 m2: 8|1@1+ (1,0) [0|1] ""  HVESP01
 SG_ HVESP01_CellBalance_18_4 m2: 9|1@1+ (1,0) [0|1] ""  HVESP01
 SG_ HVESP01_CellBalance_19_4 m2: 10|1@1+ (1,0) [0|1] ""  HVESP01
 SG_ HVESP01_CellBalance_20_4 m2: 11|1@1+ (1,0) [0|1] ""  HVESP01
 SG_ HVESP01_CellBalance_21_4 m2: 12|1@1+ (1,0) [0|1] ""  HVESP01
 SG_ HVESP01_CellBalance_22_4 m2: 13|1@1+ (1,0) [0|1] ""  HVESP01
 SG_ HVESP01_CellBalance_23_4 m2: 14|1@1+ (1,0) [0|1] ""  HVESP01
 SG_ HVESP01_CellBalance_24_4 m2: 15|1@1+ (1,0) [0|1] ""  HVESP01
 SG_ HVESP01_CellBalance_25_4 m3: 8|1@1+ (1,0) [0|1] ""  HVESP01
 SG_ HVESP01_CellBalance_26_4 m3: 9|1@1+ (1,0) [0|1] ""  HVESP01
 SG_ HVESP01_CellBalance_27_4 m3: 10|1@1+ (1,0) [0|1] ""  HVESP01
 SG_ HVESP01_CellBalance_28_4 m3: 11|1@1+ (1,0) [0|1] ""  HVESP01
 SG_ HVESP01_CellBalance_29_4 m3: 12|1@1+ (1,0) [0|1] ""  HVESP01
 SG_ HVESP01_CellBalance_30_4 m3: 13|1@1+ (1,0) [0|1] ""  HVESP01
 SG_ HVESP01_CellBalance_31_4 m3: 14|1@1+ (1,0) [0|1] ""  HVESP01
 SG_ HVESP01_CellBalance_32_4 m3: 15|1@1+ (1,0) [0|1] ""  HVESP01
 SG_ HVESP01_CellBalance_33_4 m4: 8|1@1+ (1,0) [0|1] ""  HVESP01
 SG_ HVESP01_CellBalance_34_4 m4: 9|1@1+ (1,0) [0|1] ""  HVESP01
 SG_ HVESP01_CellBalance_35_4 m4: 10|1@1+ (1,0) [0|1] ""  HVESP01
 SG_ HVESP01_CellBalance_36_4 m4: 11|1@1+ (1,0) [0|1] ""  HVESP01
 SG_ HVESP01_CellBalance_37_4 m4: 12|1@1+ (1,0) [0|1] ""  HVESP01
 SG_ HVESP01_CellBalance_38_4 m4: 13|1@1+ (1,0) [0|1] ""  HVESP01
 SG_ HVESP01_CellBalance_39_4 m4: 14|1@1+ (1,0) [0|1] ""  HVESP01
 SG_ HVESP01_CellBalance_40_4 m4: 15|1@1+ (1,0) [0|1] ""  HVESP01
 SG_ HVESP01_CellBalance_41_4 m5: 8|1@1+ (1,0) [0|1] ""  HVESP01
 SG_ HVESP01_CellBalance_42_4 m5: 9|1@1+ (1,0) [0|1] ""  HVESP01
 SG_ HVESP01_CellBalance_43_4 m5: 10|1@1+ (1,0) [0|1] ""  HVESP01
 SG_ HVESP01_CellBalance_44_4 m5: 11|1@1+ (1,0) [0|1] ""  HVESP01
 SG_ HVESP01_CellBalance_45_4 m5: 12|1@1+ (1,0) [0|1] ""  HVESP01
 SG_ HVESP01_CellBalance_46_4 m5: 13|1@1+ (1,0) [0|1] ""  HVESP01
 SG_ HVESP01_CellBalance_47_4 m5: 14|1@1+ (1,0) [0|1] ""  HVESP01
 SG_ HVESP01_CellBalance_48_4 m5: 15|1@1+ (1,0) [0|1] ""  HVESP01
 SG_ HVESP01_CellBalance_49_4 m6: 8|1@1+ (1,0) [0|1] ""  HVESP01
 SG_ HVESP01_CellBalance_50_4 m6: 9|1@1+ (1,0) [0|1] ""  HVESP01
 SG_ HVESP01_CellBalance_51_4 m6: 10|1@1+ (1,0) [0|1] ""  HVESP01
 SG_ HVESP01_CellBalance_52_4 m6: 11|1@1+ (1,0) [0|1] ""  HVESP01
 SG_ HVESP01_CellBalance_53_4 m6: 12|1@1+ (1,0) [0|1] ""  HVESP01
 SG_ HVESP01_CellBalance_54_4 m6: 13|1@1+ (1,0) [0|1] ""  HVESP01
 SG_ HVESP01_CellBalance_55_4 m6: 14|1@1+ (1,0) [0|1] ""  HVESP01
 SG_ HVESP01_CellBalance_56_4 m6: 15|1@1+ (1,0) [0|1] ""  HVESP01
 SG_ HVESP01_CellBalance_57_4 m7: 8|1@1+ (1,0) [0|1] ""  HVESP01
 SG_ HVESP01_CellBalance_58_4 m7: 9|1@1+ (1,0) [0|1] ""  HVESP01
 SG_ HVESP01_CellBalance_59_4 m7: 10|1@1+ (1,0) [0|1] ""  HVESP01
 SG_ HVESP01_CellBalance_60_4 m7: 11|1@1+ (1,0) [0|1] ""  HVESP01
 SG_ HVESP01_CellBalance_61_4 m7: 12|1@1+ (1,0) [0|1] ""  HVESP01
 SG_ HVESP01_CellBalance_62_4 m7: 13|1@1+ (1,0) [0|1] ""  HVESP01
 SG_ HVESP01_CellBalance_63_4 m7: 14|1@1+ (1,0) [0|1] ""  HVESP01
 SG_ HVESP01_CellBalance_64_4 m7: 15|1@1+ (1,0) [0|1] ""  HVESP01
 SG_ HVESP01_CellBalance_65_4 m8: 8|1@1+ (1,0) [0|1] ""  HVESP01
 SG_ HVESP01_CellBalance_66_4 m8: 9|1@1+ (1,0) [0|1] ""  HVESP01
 SG_ HVESP01_CellBalance_67_4 m8: 10|1@1+ (1,0) [0|1] ""  HVESP01
 SG_ HVESP01_CellBalance_68_4 m8: 11|1@1+ (1,0) [0|1] ""  HVESP01
 SG_ HVESP01_CellBalance_69_4 m8: 12|1@1+ (1,0) [0|1] ""  HVESP01
 SG_ HVESP01_CellBalance_70_4 m8: 13|1@1+ (1,0) [0|1] ""  HVESP01
 SG_ HVESP01_CellBalance_71_4 m8: 14|1@1+ (1,0) [0|1] ""  HVESP01
 SG_ HVESP01_CellBalance_72_4 m8: 15|1@1+ (1,0) [0|1] ""  HVESP01
 SG_ HVESP01_CellBalance_73_4 m9: 8|1@1+ (1,0) [0|1] ""  HVESP01
 SG_ HVESP01_CellBalance_74_4 m9: 9|1@1+ (1,0) [0|1] ""  HVESP01
 SG_ HVESP01_CellBalance_75_4 m9: 10|1@1+ (1,0) [0|1] ""  HVESP01
 SG_ HVESP01_CellBalance_76_4 m9: 11|1@1+ (1,0) [0|1] ""  HVESP01
 SG_ HVESP01_CellBalance_77_4 m9: 12|1@1+ (1,0) [0|1] ""  HVESP01
 SG_ HVESP01_CellBalance_78_4 m9: 13|1@1+ (1,0) [0|1] ""  HVESP01
 SG_ HVESP01_CellBalance_79_4 m9: 14|1@1+ (1,0) [0|1] ""  HVESP01
 SG_ HVESP01_CellBalance_80_4 m9: 15|1@1+ (1,0) [0|1] ""  HVESP01
 SG_ HVESP01_CellBalance_81_4 m10: 8|1@1+ (1,0) [0|1] ""  HVESP01
 SG_ HVESP01_CellBalance_82_4 m10: 9|1@1+ (1,0) [0|1] ""  HVESP01
 SG_ HVESP01_CellBalance_83_4 m10: 10|1@1+ (1,0) [0|1] ""  HVESP01
 SG_ HVESP01_CellBalance_84_4 m10: 11|1@1+ (1,0) [0|1] ""  HVESP01
 SG_ HVESP01_CellBalance_85_4 m10: 12|1@1+ (1,0) [0|1] ""  HVESP01
 SG_ HVESP01_CellBalance_86_4 m10: 13|1@1+ (1,0) [0|1] ""  HVESP01
 SG_ HVESP01_CellBalance_87_4 m10: 14|1@1+ (1,0) [0|1] ""  HVESP01
 SG_ HVESP01_CellBalance_88_4 m10: 15|1@1+ (1,0) [0|1] ""  HVESP01
 SG_ HVESP01_CellBalance_89_4 m11: 8|1@1+ (1,0) [0|1] ""  HVESP01
 SG_ HVESP01_CellBalance_90_4 m11: 9|1@1+ (1,0) [0|1] ""  HVESP01
 SG_ HVESP01_CellBalance_91_4 m11: 10|1@1+ (1,0) [0|1] ""  HVESP01
 SG_ HVESP01_CellBalance_92_4 m11: 11|1@1+ (1,0) [0|1] ""  HVESP01
 SG_ HVESP01_CellBalance_93_4 m11: 12|1@1+ (1,0) [0|1] ""  HVESP01
 SG_ HVESP01_CellBalance_94_4 m11: 13|1@1+ (1,0) [0|1] ""  HVESP01
 SG_ HVESP01_CellBalance_95_4 m11: 14|1@1+ (1,0) [0|1] ""  HVESP01
 SG_ HVESP01_CellBalance_96_4 m11: 15|1@1+ (1,0) [0|1] ""  HVESP01
 SG_ HVESP01_CellBalance_97_4 m12: 8|1@1+ (1,0) [0|1] ""  HVESP01
 SG_ HVESP01_CellBalance_98_4 m12: 9|1@1+ (1,0) [0|1] ""  HVESP01
 SG_ HVESP01_CellBalance_99_4 m12: 10|1@1+ (1,0) [0|1] ""  HVESP01
 SG_ HVESP01_CellBalance_100_4 m12: 11|1@1+ (1,0) [0|1] ""  HVESP01
 SG_ HVESP01_CellBalance_101_4 m12: 12|1@1+ (1,0) [0|1] ""  HVESP01
 SG_ HVESP01_CellBalance_102_4 m12: 13|1@1+ (1,0) [0|1] ""  HVESP01
 SG_ HVESP01_CellBalance_103_4 m12: 14|1@1+ (1,0) [0|1] ""  HVESP01
 SG_ HVESP01_CellBalance_104_4 m12: 15|1@1+ (1,0) [0|1] ""  HVESP01
 SG_ HVESP01_CellBalance_105_4 m13: 8|1@1+ (1,0) [0|1] ""  HVESP01
 SG_ HVESP01_CellBalance_106_4 m13: 9|1@1+ (1,0) [0|1] ""  HVESP01
 SG_ HVESP01_CellBalance_107_4 m13: 10|1@1+ (1,0) [0|1] ""  HVESP01
 SG_ HVESP01_CellBalance_108_4 m13: 11|1@1+ (1,0) [0|1] ""  HVESP01
 SG_ HVESP01_CellBalance_109_4 m13: 12|1@1+ (1,0) [0|1] ""  HVESP01
 SG_ HVESP01_CellBalance_110_4 m13: 13|1@1+ (1,0) [0|1] ""  HVESP01
 SG_ HVESP01_CellBalance_111_4 m13: 14|1@1+ (1,0) [0|1] ""  HVESP01
 SG_ HVESP01_CellBalance_112_4 m13: 15|1@1+ (1,0) [0|1] ""  HVESP01
 SG_ HVESP01_CellBalance_113_4 m14: 8|1@1+ (1,0) [0|1] ""  HVESP01
 SG_ HVESP01_CellBalance_114_4 m14: 9|1@1+ (1,0) [0|1] ""  HVESP01
 SG_ HVESP01_CellBalance_115_4 m14: 10|1@1+ (1,0) [0|1] ""  HVESP01
 SG_ HVESP01_CellBalance_116_4 m14: 11|1@1+ (1,0) [0|1] ""  HVESP01
 SG_ HVESP01_CellBalance_117_4 m14: 12|1@1+ (1,0) [0|1] ""  HVESP01
 SG_ HVESP01_CellBalance_118_4 m14: 13|1@1+ (1,0) [0|1] ""  HVESP01
 SG_ HVESP01_CellBalance_119_4 m14: 14|1@1+ (1,0) [0|1] ""  HVESP01
 SG_ HVESP01_CellBalance_120_4 m14: 15|1@1+ (1,0) [0|1] ""  HVESP01
 SG_ HVESP01_CellBalance_121_4 m15: 8|1@1+ (1,0) [0|1] ""  HVESP01
 SG_ HVESP01_CellBalance_122_4 m15: 9|1@1+ (1,0) [0|1] ""  HVESP01
 SG_ HVESP01_CellBalance_123_4 m15: 10|1@1+ (1,0) [0|1] ""  HVESP01
 SG_ HVESP01_CellBalance_124_4 m15: 11|1@1+ (1,0) [0|1] ""  HVESP01
 SG_ HVESP01_CellBalance_125_4 m15: 12|1@1+ (1,0) [0|1] ""  HVESP01
 SG_ HVESP01_CellBalance_126_4 m15: 13|1@1+ (1,0) [0|1] ""  HVESP01
 SG_ HVESP01_CellBalance_127_4 m15: 14|1@1+ (1,0) [0|1] ""  HVESP01
 SG_ HVESP01_CellBalance_128_4 m15: 15|1@1+ (1,0) [0|1] ""  HVESP01
 SG_ HVESP01_CellBalance_129_4 m16: 8|1@1+ (1,0) [0|1] ""  HVESP01
 SG_ HVESP01_CellBalance_130_4 m16: 9|1@1+ (1,0) [0|1] ""  HVESP01
 SG_ HVESP01_CellBalance_131_4 m16: 10|1@1+ (1,0) [0|1] ""  HVESP01
 SG_ HVESP01_CellBalance_132_4 m16: 11|1@1+ (1,0) [0|1] ""  HVESP01
 SG_ HVESP01_CellBalance_133_4 m16: 12|1@1+ (1,0) [0|1] ""  HVESP01
 SG_ HVESP01_CellBalance_134_4 m16: 13|1@1+ (1,0) [0|1] ""  HVESP01
 SG_ HVESP01_CellBalance_135_4 m16: 14|1@1+ (1,0) [0|1] ""  HVESP01
 SG_ HVESP01_CellBalance_136_4 m16: 15|1@1+ (1,0) [0|1] ""  HVESP01
 SG_ HVESP01_CellBalance_137_4 m17: 8|1@1+ (1,0) [0|1] ""  HVESP01
 SG_ HVESP01_CellBalance_138_4 m17: 9|1@1+ (1,0) [0|1] ""  HVESP01
 SG_ HVESP01_CellBalance_139_4 m17: 10|1@1+ (1,0) [0|1] ""  HVESP01
 SG_ HVESP01_CellBalance_140_4 m17: 11|1@1+ (1,0) [0|1] ""  HVESP01
 SG_ HVESP01_CellBalance_141_4 m17: 12|1@1+ (1,0) [0|1] ""  HVESP01
 SG_ HVESP01_CellBalance_142_4 m17: 13|1@1+ (1,0) [0|1] ""  HVESP01
 SG_ HVESP01_CellBalance_143_4 m17: 14|1@1+ (1,0) [0|1] ""  HVESP01
 SG_ HVESP01_CellBalance_144_4 m17: 15|1@1+ (1,0) [0|1] ""  HVESP01
 SG_ HVESP01_CellBalance_145_4 m18: 8|1@1+ (1,0) [0|1] ""  HVESP01
 SG_ HVESP01_CellBalance_146_4 m18: 9|1@1+ (1,0) [0|1] ""  HVESP01
 SG_ HVESP01_CellBalance_147_4 m18: 10|1@1+ (1,0) [0|1] ""  HVESP01
 SG_ HVESP01_CellBalance_148_4 m18: 11|1@1+ (1,0) [0|1] ""  HVESP01
 SG_ HVESP01_CellBalance_149_4 m18: 12|1@1+ (1,0) [0|1] ""  HVESP01
 SG_ HVESP01_CellBalance_150_4 m18: 13|1@1+ (1,0) [0|1] ""  HVESP01
 SG_ HVESP01_CellBalance_151_4 m18: 14|1@1+ (1,0) [0|1] ""  HVESP01
 SG_ HVESP01_CellBalance_152_4 m18: 15|1@1+ (1,0) [0|1] ""  HVESP01
 SG_ HVESP01_CellBalance_153_4 m19: 8|1@1+ (1,0) [0|1] ""  HVESP01
 SG_ HVESP01_CellBalance_154_4 m19: 9|1@1+ (1,0) [0|1] ""  HVESP01
 SG_ HVESP01_CellBalance_155_4 m19: 10|1@1+ (1,0) [0|1] ""  HVESP01
 SG_ HVESP01_CellBalance_156_4 m19: 11|1@1+ (1,0) [0|1] ""  HVESP01
 SG_ HVESP01_CellBalance_157_4 m19: 12|1@1+ (1,0) [0|1] ""  HVESP01
 SG_ HVESP01_CellBalance_158_4 m19: 13|1@1+ (1,0) [0|1] ""  HVESP01
 SG_ HVESP01_CellBalance_159_4 m19: 14|1@1+ (1,0) [0|1] ""  HVESP01
 SG_ HVESP01_CellBalance_160_4 m19: 15|1@1+ (1,0) [0|1] ""  HVESP01
 SG_ HVESP01_CellBalance_161_4 m20: 8|1@1+ (1,0) [0|1] ""  HVESP01
 SG_ HVESP01_CellBalance_162_4 m20: 9|1@1+ (1,0) [0|1] ""  HVESP01
 SG_ HVESP01_CellBalance_163_4 m20: 10|1@1+ (1,0) [0|1] ""  HVESP01
 SG_ HVESP01_CellBalance_164_4 m20: 11|1@1+ (1,0) [0|1] ""  HVESP01
 SG_ HVESP01_CellBalance_165_4 m20: 12|1@1+ (1,0) [0|1] ""  HVESP01
 SG_ HVESP01_CellBalance_166_4 m20: 13|1@1+ (1,0) [0|1] ""  HVESP01
 SG_ HVESP01_CellBalance_167_4 m20: 14|1@1+ (1,0) [0|1] ""  HVESP01
 SG_ HVESP01_CellBalance_168_4 m20: 15|1@1+ (1,0) [0|1] ""  HVESP01
 SG_ HVESP01_CellBalance_169_4 m21: 8|1@1+ (1,0) [0|1] ""  HVESP01
 SG_ HVESP01_CellBalance_170_4 m21: 9|1@1+ (1,0) [0|1] ""  HVESP01
 SG_ HVESP01_CellBalance_171_4 m21: 10|1@1+ (1,0) [0|1] ""  HVESP01
 SG_ HVESP01_CellBalance_172_4 m21: 11|1@1+ (1,0) [0|1] ""  HVESP01
 SG_ HVESP01_CellBalance_173_4 m21: 12|1@1+ (1,0) [0|1] ""  HVESP01
 SG_ HVESP01_CellBalance_174_4 m21: 13|1@1+ (1,0) [0|1] ""  HVESP01
 SG_ HVESP01_CellBalance_175_4 m21: 14|1@1+ (1,0) [0|1] ""  HVESP01
 SG_ HVESP01_CellBalance_176_4 m21: 15|1@1+ (1,0) [0|1] ""  HVESP01
 SG_ HVESP01_CellBalance_177_4 m22: 8|1@1+ (1,0) [0|1] ""  HVESP01
 SG_ HVESP01_CellBalance_178_4 m22: 9|1@1+ (1,0) [0|1] ""  HVESP01
 SG_ HVESP01_CellBalance_179_4 m22: 10|1@1+ (1,0) [0|1] ""  HVESP01
 SG_ HVESP01_CellBalance_180_4 m22: 11|1@1+ (1,0) [0|1] ""  HVESP01
 SG_ HVESP01_CellBalance_181_4 m22: 12|1@1+ (1,0) [0|1] ""  HVESP01
 SG_ HVESP01_CellBalance_182_4 m22: 13|1@1+ (1,0) [0|1] ""  HVESP01
 SG_ HVESP01_CellBalance_183_4 m22: 14|1@1+ (1,0) [0|1] ""  HVESP01
 SG_ HVESP01_CellBalance_184_4 m22: 15|1@1+ (1,0) [0|1] ""  HVESP01
 SG_ HVESP01_CellBalance_185_4 m23: 8|1@1+ (1,0) [0|1] ""  HVESP01
 SG_ HVESP01_CellBalance_186_4 m23: 9|1@1+ (1,0) [0|1] ""  HVESP01
 SG_ HVESP01_CellBalance_187_4 m23: 10|1@1+ (1,0) [0|1] ""  HVESP01
 SG_ HVESP01_CellBalance_188_4 m23: 11|1@1+ (1,0) [0|1] ""  HVESP01
 SG_ HVESP01_CellBalance_189_4 m23: 12|1@1+ (1,0) [0|1] ""  HVESP01
 SG_ HVESP01_CellBalance_190_4 m23: 13|1@1+ (1,0) [0|1] ""  HVESP01
 SG_ HVESP01_CellBalance_191_4 m23: 14|1@1+ (1,0) [0|1] ""  HVESP01
 SG_ HVESP01_CellBalance_192_4 m23: 15|1@1+ (1,0) [0|1] ""  HVESP01
 SG_ multiplexorcb_4 M: 0|8@1+ (1,0) [0|255] ""  HVESP01

BA_DEF_ BO_  "GenMsgDiag" ENUM "No","Yes";
BA_DEF_ BO_  "GenMsgInstanced" STRING ;
BA_DEF_ SG_  "SigType" ENUM "Default","Range","RangeSigned","ASCII","Discrete","Control","ReferencePGN","DTC","StringDelimiter","StringLength","StringLengthControl","MessageCounter","MessageChecksum";
BA_DEF_ SG_  "GenSigEVName" STRING ;
BA_DEF_ SG_  "GenSigILSupport" ENUM "No","Yes";
BA_DEF_ SG_  "GenSigSendType" ENUM "Cyclic","OnWrite","OnWriteWithRepetition","OnChange","OnChangeWithRepetition","IfActive","IfActiveWithRepetition","NoSigSendType";
BA_DEF_ BO_  "GenMsgILSupport" ENUM "No","Yes";
BA_DEF_ BO_  "GenMsgSendType" ENUM "cyclic","NotUsed","IfActive","NotUsed","NotUsed","NotUsed","NotUsed","NotUsed","noMsgSendType";
BA_DEF_ BO_  "GenMsgRequestable" INT 0 1;
BA_DEF_ BO_  "GenMsgCycleTime" INT 0 3600000;
BA_DEF_ BO_  "VFrameFormat" ENUM "StandardCAN","ExtendedCAN","reserved","J1939PG";
BA_DEF_ SG_  "SystemSignalLongSymbol" STRING ;
BA_DEF_DEF_  "GenMsgDiag" "No";
BA_DEF_DEF_  "GenMsgInstanced" "No";
BA_DEF_DEF_  "SigType" "Default";
BA_DEF_DEF_  "GenSigEVName" "Env@Nodename_@Signame";
BA_DEF_DEF_  "GenSigILSupport" "Yes";
BA_DEF_DEF_  "GenSigSendType" "NoSigSendType";
BA_DEF_DEF_  "GenMsgILSupport" "Yes";
BA_DEF_DEF_  "GenMsgSendType" "noMsgSendType";
BA_DEF_DEF_  "GenMsgRequestable" 1;
BA_DEF_DEF_  "GenMsgCycleTime" 0;
BA_DEF_DEF_  "VFrameFormat" "J1939PG";
BA_DEF_DEF_  "SystemSignalLongSymbol" "";
BA_ "GenMsgDiag" BO_ 2499741802 1;
BA_ "GenMsgDiag" BO_ 2499741803 1;
BA_ "GenMsgDiag" BO_ 2499741804 1;
BA_ "GenMsgInstanced" BO_ 2499741802 "False";
BA_ "GenMsgInstanced" BO_ 2499741803 "False";
BA_ "GenMsgInstanced" BO_ 2499741804 "False";
BA_ "GenMsgInstanced" BO_ 2499742053 "False";
BA_ "GenMsgInstanced" BO_ 2499742054 "False";
BA_ "GenMsgInstanced" BO_ 2499742055 "False";
BA_ "GenMsgInstanced" BO_ 2499742056 "False";
BA_ "GenMsgInstanced" BO_ 2499742057 "False";
BA_ "GenMsgInstanced" BO_ 2499742058 "False";
BA_ "GenMsgInstanced" BO_ 2499742059 "False";
BA_ "GenMsgInstanced" BO_ 2499742060 "False";
BA_ "GenMsgInstanced" BO_ 2499742309 "False";
BA_ "GenMsgInstanced" BO_ 2499742310 "False";
BA_ "GenMsgInstanced" BO_ 2499742311 "False";
BA_ "GenMsgInstanced" BO_ 2499742312 "False";
BA_ "GenMsgInstanced" BO_ 2499742313 "False";
BA_ "GenMsgInstanced" BO_ 2499742314 "False";
BA_ "GenMsgInstanced" BO_ 2499742315 "False";
BA_ "GenMsgInstanced" BO_ 2499742316 "False";
BA_ "GenMsgInstanced" BO_ 2499742565 "False";
BA_ "GenMsgInstanced" BO_ 2499742566 "False";
BA_ "GenMsgInstanced" BO_ 2499742567 "False";
BA_ "GenMsgInstanced" BO_ 2499742568 "False";
BA_ "GenMsgInstanced" BO_ 2499742569 "False";
BA_ "GenMsgInstanced" BO_ 2499742570 "False";
BA_ "GenMsgInstanced" BO_ 2499742571 "False";
BA_ "GenMsgInstanced" BO_ 2499742572 "False";
BA_ "GenMsgInstanced" BO_ 2499742821 "False";
BA_ "GenMsgInstanced" BO_ 2499742822 "False";
BA_ "GenMsgInstanced" BO_ 2499742823 "False";
BA_ "GenMsgInstanced" BO_ 2499742824 "False";
BA_ "GenMsgInstanced" BO_ 2499742825 "False";
BA_ "GenMsgInstanced" BO_ 2499742826 "False";
BA_ "GenMsgInstanced" BO_ 2499742827 "False";
BA_ "GenMsgInstanced" BO_ 2499742828 "False";
BA_ "GenMsgInstanced" BO_ 2499743077 "False";
BA_ "GenMsgInstanced" BO_ 2499743078 "False";
BA_ "GenMsgInstanced" BO_ 2499743079 "False";
BA_ "GenMsgInstanced" BO_ 2499743080 "False";
BA_ "GenMsgInstanced" BO_ 2499743081 "False";
BA_ "GenMsgInstanced" BO_ 2499743082 "False";
BA_ "GenMsgInstanced" BO_ 2499743083 "False";
BA_ "GenMsgInstanced" BO_ 2499743084 "False";
BA_ "GenMsgInstanced" BO_ 2499743333 "False";
BA_ "GenMsgInstanced" BO_ 2499743334 "False";
BA_ "GenMsgInstanced" BO_ 2499743335 "False";
BA_ "GenMsgInstanced" BO_ 2499743336 "False";
BA_ "GenMsgCycleTime" BO_ 2499742309 100;
BA_ "GenMsgCycleTime" BO_ 2499742310 100;
BA_ "GenMsgCycleTime" BO_ 2499742311 100;
BA_ "GenMsgCycleTime" BO_ 2499742312 100;
BA_ "GenMsgCycleTime" BO_ 2499742313 100;
BA_ "GenMsgCycleTime" BO_ 2499742314 100;
BA_ "GenMsgCycleTime" BO_ 2499742315 100;
BA_ "GenMsgCycleTime" BO_ 2499742316 100;
BA_ "GenMsgCycleTime" BO_ 2499742565 100;
BA_ "GenMsgCycleTime" BO_ 2499742566 100;
BA_ "GenMsgCycleTime" BO_ 2499742567 100;
BA_ "GenMsgCycleTime" BO_ 2499742568 100;
BA_ "GenMsgCycleTime" BO_ 2499742569 100;
BA_ "GenMsgCycleTime" BO_ 2499742570 100;
BA_ "GenMsgCycleTime" BO_ 2499742571 100;
BA_ "GenMsgCycleTime" BO_ 2499742572 100;
BA_ "GenMsgCycleTime" BO_ 2499742821 100;
BA_ "GenMsgCycleTime" BO_ 2499742822 100;
BA_ "GenMsgCycleTime" BO_ 2499742823 100;
BA_ "GenMsgCycleTime" BO_ 2499742824 100;
BA_ "GenMsgCycleTime" BO_ 2499742825 100;
BA_ "GenMsgCycleTime" BO_ 2499742826 100;
BA_ "GenMsgCycleTime" BO_ 2499742827 100;
BA_ "GenMsgCycleTime" BO_ 2499742828 100;
BA_ "VFrameFormat" BO_ 2499742821 1;
BA_ "VFrameFormat" BO_ 2499742822 1;
BA_ "VFrameFormat" BO_ 2499742823 1;
BA_ "VFrameFormat" BO_ 2499742824 1;
BA_ "VFrameFormat" BO_ 2499742825 1;
BA_ "VFrameFormat" BO_ 2499742826 1;
BA_ "VFrameFormat" BO_ 2499742827 1;
BA_ "VFrameFormat" BO_ 2499742828 1;
BA_ "VFrameFormat" BO_ 2499743077 1;
BA_ "VFrameFormat" BO_ 2499743078 1;
BA_ "VFrameFormat" BO_ 2499743079 1;
BA_ "VFrameFormat" BO_ 2499743080 1;
BA_ "VFrameFormat" BO_ 2499743081 1;
BA_ "VFrameFormat" BO_ 2499743082 1;
BA_ "VFrameFormat" BO_ 2499743083 1;
BA_ "VFrameFormat" BO_ 2499743084 1;
VAL_ 2499742821 HVESP01_packstate_1  7 "Disengage"  6 "Connected"  5 "ExternalIsolationCheck"  4 "PrepareBusJoin"  3 "PrepareBusPrecharge"  2 "StandbyReady"  1 "StandbyNotReady"  0 "StandbyInit"  ;
VAL_ 2499742821 HVESP01_negPackConStatusReq_1  3 "DontCare"  2 "EmergencyContactorClose"  1 "CloseContactor"  0 "OpenContactor"  ;
VAL_ 2499742821 HVESP01_posPackConStatusReq_1  3 "DontCare"  2 "EmergencyContactorClose"  1 "CloseContactor"  0 "OpenContactor"  ;
VAL_ 2499742821 HVESP01_prechargeConStatusReq_1  3 "DontCare"  2 "EmergencyContactorClose"  1 "CloseContactor"  0 "OpenContactor"  ;
VAL_ 2499742822 HVESP01_packstate_2  7 "Disengage"  6 "Connected"  5 "ExternalIsolationCheck"  4 "PrepareBusJoin"  3 "PrepareBusPrecharge"  2 "StandbyReady"  1 "StandbyNotReady"  0 "StandbyInit"  ;
VAL_ 2499742822 HVESP01_negPackConStatusReq_2  3 "DontCare"  2 "EmergencyContactorClose"  1 "CloseContactor"  0 "OpenContactor"  ;
VAL_ 2499742822 HVESP01_posPackConStatusReq_2  3 "DontCare"  2 "EmergencyContactorClose"  1 "CloseContactor"  0 "OpenContactor"  ;
VAL_ 2499742822 HVESP01_prechargeConStatusReq_2  3 "DontCare"  2 "EmergencyContactorClose"  1 "CloseContactor"  0 "OpenContactor"  ;
VAL_ 2499742823 HVESP01_packstate_3  7 "Disengage"  6 "Connected"  5 "ExternalIsolationCheck"  4 "PrepareBusJoin"  3 "PrepareBusPrecharge"  2 "StandbyReady"  1 "StandbyNotReady"  0 "StandbyInit"  ;
VAL_ 2499742823 HVESP01_negPackConStatusReq_3  3 "DontCare"  2 "EmergencyContactorClose"  1 "CloseContactor"  0 "OpenContactor"  ;
VAL_ 2499742823 HVESP01_posPackConStatusReq_3  3 "DontCare"  2 "EmergencyContactorClose"  1 "CloseContactor"  0 "OpenContactor"  ;
VAL_ 2499742823 HVESP01_prechargeConStatusReq_3  3 "DontCare"  2 "EmergencyContactorClose"  1 "CloseContactor"  0 "OpenContactor"  ;
VAL_ 2499742824 HVESP01_packstate_4  7 "Disengage"  6 "Connected"  5 "ExternalIsolationCheck"  4 "PrepareBusJoin"  3 "PrepareBusPrecharge"  2 "StandbyReady"  1 "StandbyNotReady"  0 "StandbyInit"  ;
VAL_ 2499742824 HVESP01_negPackConStatusReq_4  3 "DontCare"  2 "EmergencyContactorClose"  1 "CloseContactor"  0 "OpenContactor"  ;
VAL_ 2499742824 HVESP01_posPackConStatusReq_4  3 "DontCare"  2 "EmergencyContactorClose"  1 "CloseContactor"  0 "OpenContactor"  ;
VAL_ 2499742824 HVESP01_prechargeConStatusReq_4  3 "DontCare"  2 "EmergencyContactorClose"  1 "CloseContactor"  0 "OpenContactor"  ;
VAL_ 2499742825 HVESP01_packstate_5  7 "Disengage"  6 "Connected"  5 "ExternalIsolationCheck"  4 "PrepareBusJoin"  3 "PrepareBusPrecharge"  2 "StandbyReady"  1 "StandbyNotReady"  0 "StandbyInit"  ;
VAL_ 2499742825 HVESP01_negPackConStatusReq_5  3 "DontCare"  2 "EmergencyContactorClose"  1 "CloseContactor"  0 "OpenContactor"  ;
VAL_ 2499742825 HVESP01_posPackConStatusReq_5  3 "DontCare"  2 "EmergencyContactorClose"  1 "CloseContactor"  0 "OpenContactor"  ;
VAL_ 2499742825 HVESP01_prechargeConStatusReq_5  3 "DontCare"  2 "EmergencyContactorClose"  1 "CloseContactor"  0 "OpenContactor"  ;
VAL_ 2499742826 HVESP01_packstate_6  7 "Disengage"  6 "Connected"  5 "ExternalIsolationCheck"  4 "PrepareBusJoin"  3 "PrepareBusPrecharge"  2 "StandbyReady"  1 "StandbyNotReady"  0 "StandbyInit"  ;
VAL_ 2499742826 HVESP01_negPackConStatusReq_6  3 "DontCare"  2 "EmergencyContactorClose"  1 "CloseContactor"  0 "OpenContactor"  ;
VAL_ 2499742826 HVESP01_posPackConStatusReq_6  3 "DontCare"  2 "EmergencyContactorClose"  1 "CloseContactor"  0 "OpenContactor"  ;
VAL_ 2499742826 HVESP01_prechargeConStatusReq_6  3 "DontCare"  2 "EmergencyContactorClose"  1 "CloseContactor"  0 "OpenContactor"  ;
VAL_ 2499742827 HVESP01_packstate_7  7 "Disengage"  6 "Connected"  5 "ExternalIsolationCheck"  4 "PrepareBusJoin"  3 "PrepareBusPrecharge"  2 "StandbyReady"  1 "StandbyNotReady"  0 "StandbyInit"  ;
VAL_ 2499742827 HVESP01_negPackConStatusReq_7  3 "DontCare"  2 "EmergencyContactorClose"  1 "CloseContactor"  0 "OpenContactor"  ;
VAL_ 2499742827 HVESP01_posPackConStatusReq_7  3 "DontCare"  2 "EmergencyContactorClose"  1 "CloseContactor"  0 "OpenContactor"  ;
VAL_ 2499742827 HVESP01_prechargeConStatusReq_7  3 "DontCare"  2 "EmergencyContactorClose"  1 "CloseContactor"  0 "OpenContactor"  ;
VAL_ 2499742828 HVESP01_packstate_8  7 "Disengage"  6 "Connected"  5 "ExternalIsolationCheck"  4 "PrepareBusJoin"  3 "PrepareBusPrecharge"  2 "StandbyReady"  1 "StandbyNotReady"  0 "StandbyInit"  ;
VAL_ 2499742828 HVESP01_negPackConStatusReq_8  3 "DontCare"  2 "EmergencyContactorClose"  1 "CloseContactor"  0 "OpenContactor"  ;
VAL_ 2499742828 HVESP01_posPackConStatusReq_8  3 "DontCare"  2 "EmergencyContactorClose"  1 "CloseContactor"  0 "OpenContactor"  ;
VAL_ 2499742828 HVESP01_prechargeConStatusReq_8  3 "DontCare"  2 "EmergencyContactorClose"  1 "CloseContactor"  0 "OpenContactor"  ;
